VERSION "HNNBNNNYNNNNNNNNNNNNNNNNNNNNNNNNNNNNNNNNNN/4/%%%/4/'%**4NNN///"

NS_ :

BS_:

BU_: AWC BAP_Tester BMC_MLBevo BMS_MV BMS_NV DCDC_800V_PAG DCDC_HV DCDC_HV_02 DCDC_IHEV FCU_MLBevo_FCEV Gateway Gateway_PAG Ladegeraet_2 Ladegeraet_Konzern LE1 LE2 LE2_3_MLBevo_LB LE_MLBevo LE_MLBevo_LB Sub_Gateway TME

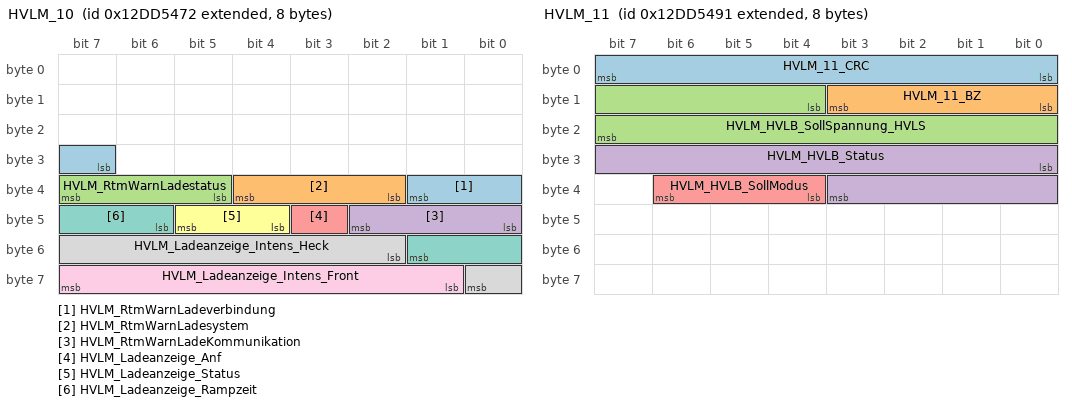
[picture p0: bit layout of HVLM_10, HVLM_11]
BO_ 2463978610 HVLM_10: 8 Ladegeraet_Konzern
 SG_ HVLM_RtmWarnLadeverbindung : 31|3@1+ (1,0) [0|7] ""  Gateway,Gateway_PAG,Sub_Gateway
 SG_ HVLM_RtmWarnLadesystem : 34|3@1+ (1,0) [0|7] ""  Gateway,Gateway_PAG,Sub_Gateway
 SG_ HVLM_RtmWarnLadestatus : 37|3@1+ (1,0) [0|7] ""  Gateway,Gateway_PAG,Sub_Gateway
 SG_ HVLM_RtmWarnLadeKommunikation : 40|3@1+ (1,0) [0|7] ""  Gateway,Gateway_PAG,Sub_Gateway
 SG_ HVLM_Ladeanzeige_Anf : 43|1@1+ (1,0) [0|1] ""  Gateway,Gateway_PAG,Sub_Gateway
 SG_ HVLM_Ladeanzeige_Status : 44|2@1+ (1,0) [0|3] ""  Gateway,Gateway_PAG,Sub_Gateway
 SG_ HVLM_Ladeanzeige_Rampzeit : 46|4@1+ (50,0) [0|750] "Unit_MilliSecon"  Gateway,Gateway_PAG,Sub_Gateway
 SG_ HVLM_Ladeanzeige_Intens_Heck : 50|7@1+ (1,0) [0|100] "Unit_PerCent"  Gateway,Gateway_PAG,Sub_Gateway
 SG_ HVLM_Ladeanzeige_Intens_Front : 57|7@1+ (1,0) [0|100] "Unit_PerCent"  Gateway,Gateway_PAG,Sub_Gateway

BO_ 2463978641 HVLM_11: 8 Ladegeraet_Konzern
 SG_ HVLM_11_CRC : 0|8@1+ (1,0) [0|255] ""  DCDC_HV_02
 SG_ HVLM_11_BZ : 8|4@1+ (1,0) [0|15] ""  DCDC_HV_02
 SG_ HVLM_HVLB_SollSpannung_HVLS : 12|12@1+ (0.25,0) [0|1023.25] "Unit_Volt"  DCDC_HV_02
 SG_ HVLM_HVLB_Status : 24|12@1+ (1,0) [0|4095] ""  DCDC_HV_02
 SG_ HVLM_HVLB_SollModus : 36|3@1+ (1,0) [0|7] ""  DCDC_HV_02

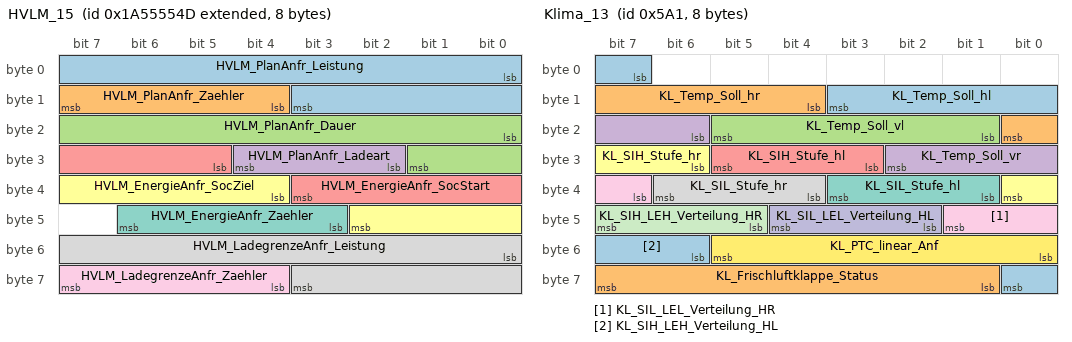
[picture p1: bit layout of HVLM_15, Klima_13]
BO_ 2589283661 HVLM_15: 8 Ladegeraet_Konzern
 SG_ HVLM_PlanAnfr_Leistung : 0|12@1+ (200,0) [0|818600] "Unit_Watt"  AWC,DCDC_HV_02,TME
 SG_ HVLM_PlanAnfr_Zaehler : 12|4@1+ (1,0) [0|13] "Unit_None"  AWC,DCDC_HV_02,TME
 SG_ HVLM_PlanAnfr_Dauer : 16|10@1+ (1,0) [0|1021] "Unit_Minut"  AWC,DCDC_HV_02,TME
 SG_ HVLM_PlanAnfr_Ladeart : 26|3@1+ (1,0) [0|7] ""  AWC,DCDC_HV_02,TME
 SG_ HVLM_EnergieAnfr_SocStart : 29|7@1+ (1,0) [0|100] "Unit_PerCent"  BMC_MLBevo
 SG_ HVLM_EnergieAnfr_SocZiel : 36|7@1+ (1,0) [0|100] "Unit_PerCent"  BMC_MLBevo
 SG_ HVLM_EnergieAnfr_Zaehler : 43|4@1+ (1,0) [0|13] "Unit_None"  BMC_MLBevo
 SG_ HVLM_LadegrenzeAnfr_Leistung : 48|12@1+ (200,0) [0|818600] "Unit_Watt"  BMC_MLBevo
 SG_ HVLM_LadegrenzeAnfr_Zaehler : 60|4@1+ (1,0) [0|13] "Unit_None"  BMC_MLBevo

BO_ 1857 ISO_DCDC_Req: 8 Gateway
 SG_ ISO_DCDC_Req_Data : 0|64@1+ (1,0) [0|1.84467440737096E+019] ""  DCDC_IHEV

BO_ 1963 ISO_DCDC_Resp: 8 DCDC_IHEV
 SG_ ISO_DCDC_Resp_Data : 0|64@1+ (1,0) [0|1.84467440737096E+019] ""  Gateway,Gateway_PAG

BO_ 1795 ISO_Funktionaler_Req_Abgas: 8 Gateway
 SG_ ISO_Funktionaler_Req_Abgas : 0|64@1+ (1,0) [0|1.84467440737096E+019] ""  AWC,BMC_MLBevo,BMS_MV,Ladegeraet_2,Ladegeraet_Konzern,TME

BO_ 1792 ISO_Funktionaler_Req_All: 8 Gateway
 SG_ ISO_ALL_01_Req_Data : 0|64@1+ (1,0) [0|1.84467440737096E+019] ""  AWC,BMC_MLBevo,BMS_MV,BMS_NV,DCDC_800V_PAG,DCDC_HV,DCDC_HV_02,DCDC_IHEV,FCU_MLBevo_FCEV,Ladegeraet_2,Ladegeraet_Konzern,Sub_Gateway,TME

BO_ 2015 ISO_Funktionaler_Req_OBD: 8 Gateway
 SG_ ISO_OBD_Funktionaler_Req_Data : 0|64@1+ (1,0) [0|1.84467440737096E+019] ""  AWC,BMC_MLBevo,BMS_MV,Ladegeraet_2,Ladegeraet_Konzern,TME

BO_ 1860 ISO_Ladegeraet_Req: 8 Gateway
 SG_ ISO_Ladegeraet_Req_Data : 0|64@1+ (1,0) [0|1.84467440737096E+019] ""  Ladegeraet_Konzern

BO_ 1966 ISO_Ladegeraet_Resp: 8 Ladegeraet_Konzern
 SG_ ISO_Ladegeraet_Resp_Data : 0|64@1+ (1,0) [0|1.84467440737096E+019] ""  Gateway,Gateway_PAG

BO_ 2021 ISO_OBD_04_Req: 8 Gateway
 SG_ ISO_OBD_04_Req_Data : 0|64@1+ (1,0) [0|1.84467440737096E+019] ""  BMC_MLBevo,BMS_MV

BO_ 2029 ISO_OBD_04_Resp: 8 BMC_MLBevo
 SG_ ISO_OBD_04_Resp_Data : 0|64@1+ (1,0) [0|1.84467440737096E+019] ""  Gateway,Gateway_PAG

BO_ 2023 ISO_OBD_06_Req: 8 Gateway
 SG_ ISO_OBD_06_Req_Data : 0|64@1+ (1,0) [0|1.84467440737096E+019] ""  TME

BO_ 2031 ISO_OBD_06_Resp: 8 TME
 SG_ ISO_OBD_06_Resp_Data : 0|64@1+ (1,0) [0|1.84467440737096E+019] ""  Gateway,Gateway_PAG

BO_ 2549350937 ISO_OBDC_RTM_Req: 8 Gateway
 SG_ ISO_OBDC_RTM_Req_Data : 0|64@1+ (1,0) [0|1.84467440737096E+019] ""  Sub_Gateway

BO_ 2549487874 ISO_OBDC_RTM_Resp: 8 Sub_Gateway
 SG_ ISO_OBDC_RTM_Resp_Data : 0|64@1+ (1,0) [0|1.84467440737096E+019] ""  Gateway,Gateway_PAG

BO_ 2549356802 ISO_RTM_OBDC_Req: 8 Sub_Gateway
 SG_ ISO_RTM_OBDC_Req_Data : 0|64@1+ (1,0) [0|1.84467440737096E+019] ""  Gateway,Gateway_PAG

BO_ 2549482009 ISO_RTM_OBDC_Resp: 8 Gateway
 SG_ ISO_RTM_OBDC_Resp_Data : 0|64@1+ (1,0) [0|1.84467440737096E+019] ""  Sub_Gateway

BO_ 1865 ISO_Sub_Gateway_Req: 8 Gateway
 SG_ ISO_Sub_Gateway_Req_Data : 0|64@1+ (1,0) [0|1.84467440737096E+019] ""  Sub_Gateway

BO_ 1971 ISO_Sub_Gateway_Resp: 8 Sub_Gateway
 SG_ ISO_Sub_Gateway_Resp_Data : 0|64@1+ (1,0) [0|1.84467440737096E+019] ""  Gateway,Gateway_PAG

BO_ 1858 ISO_TME_Req: 8 Gateway
 SG_ ISO_TME_Req_Data : 0|64@1+ (1,0) [0|1.84467440737096E+019] ""  TME

BO_ 1964 ISO_TME_Resp: 8 TME
 SG_ ISO_TME_Resp_Data : 0|64@1+ (1,0) [0|1.84467440737096E+019] ""  Gateway,Gateway_PAG

BO_ 2549874831 ISOx_AWC_Req: 8 Gateway
 SG_ ISO_AWC_Req_Data : 0|64@1+ (1,0) [0|1.84467440737096E+019] ""  AWC

BO_ 2550005903 ISOx_AWC_Resp: 8 AWC
 SG_ ISO_AWC_Resp_Data : 0|64@1+ (1,0) [0|1.84467440737096E+019] ""  Gateway,Gateway_PAG

BO_ 2549874862 ISOx_BattRegelung_Req: 8 Gateway
 SG_ ISO_BattRegelung_Req_Data : 0|64@1+ (1,0) [0|1.84467440737096E+019] ""  BMS_NV

BO_ 2550005934 ISOx_BattRegelung_Resp: 8 BMS_NV
 SG_ ISO_BattRegelung_Resp_Data : 0|64@1+ (1,0) [0|1.84467440737096E+019] ""  Gateway,Gateway_PAG

BO_ 2549874844 ISOx_BMS_48V_Req: 8 Gateway
 SG_ ISO_BMS_48V_Req_Data : 0|64@1+ (1,0) [0|1.84467440737096E+019] ""  BMS_MV

BO_ 2550005916 ISOx_BMS_48V_Resp: 8 BMS_MV
 SG_ ISO_BMS_48V_Resp_Data : 0|64@1+ (1,0) [0|1.84467440737096E+019] ""  Gateway,Gateway_PAG

BO_ 2549874887 ISOx_DCDC_HV_02_Req: 8 Gateway
 SG_ ISO_DCDC_HV_02_Req_Data : 0|64@1+ (1,0) [0|1.84467440737096E+019] "Unit_None"  DCDC_HV_02

BO_ 2550005959 ISOx_DCDC_HV_02_Resp: 8 DCDC_HV_02
 SG_ ISO_DCDC_HV_02_Resp_Data : 0|64@1+ (1,0) [0|1.84467440737096E+019] "Unit_None"  Gateway,Gateway_PAG

BO_ 2549874895 ISOx_DCDC_HV_03_Req: 8 Gateway
 SG_ ISOx_DCDC_HV_03_Req_Data : 0|64@1+ (1,0) [0|1.84467440737096E+019] ""  FCU_MLBevo_FCEV

BO_ 2550005967 ISOx_DCDC_HV_03_Resp: 8 FCU_MLBevo_FCEV
 SG_ ISOx_DCDC_HV_03_Resp_Data : 0|64@1+ (1,0) [0|1.84467440737096E+019] ""  Gateway

BO_ 2549874871 ISOx_DCDC_HV_Req: 8 Gateway
 SG_ ISO_DCDC_HV_Req_Data : 0|64@1+ (1,0) [0|1.84467440737096E+019] ""  DCDC_800V_PAG,DCDC_HV

BO_ 2550005943 ISOx_DCDC_HV_Resp: 8 DCDC_800V_PAG
 SG_ ISO_DCDC_HV_Resp_Data : 0|64@1+ (1,0) [0|1.84467440737096E+019] ""  Gateway,Gateway_PAG

BO_ 2549874869 ISOx_FCU_Req: 8 Gateway
 SG_ ISOx_FCU_Req_Data : 0|64@1+ (1,0) [0|1.84467440737096E+019] ""  FCU_MLBevo_FCEV

BO_ 2550005941 ISOx_FCU_Resp: 8 FCU_MLBevo_FCEV
 SG_ ISOx_FCU_Resp_Data : 0|64@1+ (1,0) [0|1.84467440737096E+019] ""  Gateway

BO_ 2549874811 ISOx_Hybrid_01_Req: 8 Gateway
 SG_ ISO_Hybrid_01_Req_Data : 0|64@1+ (1,0) [0|1.84467440737096E+019] ""  BMC_MLBevo

BO_ 2550005883 ISOx_Hybrid_01_Resp: 8 BMC_MLBevo
 SG_ ISO_Hybrid_01_Resp_Data : 0|64@1+ (1,0) [0|1.84467440737096E+019] ""  Gateway,Gateway_PAG

BO_ 2549874886 ISOx_Ladegeraet_2_Req: 8 Gateway
 SG_ ISO_Ladegeraet_2_Req_Data : 0|64@1+ (1,0) [0|1.84467440737096E+019] "Unit_None"  Ladegeraet_2

BO_ 2550005958 ISOx_Ladegeraet_2_Resp: 8 Ladegeraet_2
 SG_ ISO_Ladegeraet_2_Resp_Data : 0|64@1+ (1,0) [0|1.84467440737096E+019] "Unit_None"  Gateway,Gateway_PAG

BO_ 2549874868 ISOx_TelemetrieSG_Req: 8 Gateway
 SG_ ISOx_TelemetrieSG_Req_Data : 0|64@1+ (1,0) [0|1.84467440737096E+019] ""  Sub_Gateway

BO_ 2550005940 ISOx_TelemetrieSG_Resp: 8 Sub_Gateway
 SG_ ISOx_TelemetrieSG_Resp_Data : 0|64@1+ (1,0) [0|1.84467440737096E+019] ""  Gateway,Gateway_PAG

BO_ 497 Kessy_11: 8 Gateway
 SG_ KY_IDG_in_Reichweite : 12|1@1+ (1,0) [0|1] "" Vector__XXX
 SG_ KY_Auf_Taste : 13|1@1+ (1,0) [0|1] ""  FCU_MLBevo_FCEV,Ladegeraet_Konzern
 SG_ KY_HDF_Taste : 14|1@1+ (1,0) [0|1] "" Vector__XXX
 SG_ KY_Panik_Taste : 15|1@1+ (1,0) [0|1] "" Vector__XXX
 SG_ KY_Zu_Taste : 16|1@1+ (1,0) [0|1] ""  Ladegeraet_Konzern
 SG_ KY_FT_Entriegelung_Autorisiert : 17|1@1+ (1,0) [0|1] ""  FCU_MLBevo_FCEV
 SG_ KY_FT_Verriegelung_Autorisiert : 18|1@1+ (1,0) [0|1] "" Vector__XXX
 SG_ KY_BT_Entriegelung_Autorisiert : 19|1@1+ (1,0) [0|1] ""  FCU_MLBevo_FCEV
 SG_ KY_BT_Verriegelung_Autorisiert : 20|1@1+ (1,0) [0|1] "" Vector__XXX
 SG_ KY_HFS_Entriegelung_Autorisiert : 21|1@1+ (1,0) [0|1] ""  FCU_MLBevo_FCEV
 SG_ KY_HFS_Verriegelung_Autorisiert : 22|1@1+ (1,0) [0|1] "" Vector__XXX
 SG_ KY_HBFS_Entriegelung_Autorisiert : 23|1@1+ (1,0) [0|1] ""  FCU_MLBevo_FCEV
 SG_ KY_HBFS_Verriegelung_Autorisiert : 24|1@1+ (1,0) [0|1] "" Vector__XXX
 SG_ KY_Front_Entr_Autorisiert : 25|1@1+ (1,0) [0|1] "" Vector__XXX
 SG_ KY_Front_Verr_Autorisiert : 26|1@1+ (1,0) [0|1] "" Vector__XXX
 SG_ KY_HD_Entriegelung_Autorisiert : 27|1@1+ (1,0) [0|1] ""  FCU_MLBevo_FCEV
 SG_ KY_HD_Verriegelung_Autorisiert : 28|1@1+ (1,0) [0|1] "" Vector__XXX
 SG_ KY_Bereich : 29|3@1+ (1,0) [0|7] "" Vector__XXX
 SG_ KY_Position : 32|3@1+ (1,0) [0|7] "" Vector__XXX
 SG_ KY_ZV_Signatur : 35|11@1+ (1,0) [0|2047] "" Vector__XXX
 SG_ Schluesselnr_Personalisierung : 46|4@1+ (1,0) [0|15] "" Vector__XXX
 SG_ FFB_FDF_Taste : 50|1@1+ (1,0) [0|1] "" Vector__XXX
 SG_ FFB_Joker_Taste : 51|1@1+ (1,0) [0|1] "" Vector__XXX
 SG_ FFB_Park_Taste : 52|1@1+ (1,0) [0|1] "" Vector__XXX
 SG_ FFB_Remotestart_Taste : 53|1@1+ (1,0) [0|1] "" Vector__XXX
 SG_ FBS_Aktivierung_Pilot_Parken : 54|1@1+ (1,0) [0|1] "" Vector__XXX
 SG_ KY_Schluessel_im_Fzg : 55|1@1+ (1,0) [0|1] "" Vector__XXX
 SG_ KY_EasyClose_Abbruch : 56|1@1+ (1,0) [0|1] "" Vector__XXX
 SG_ KY_EasyClose_Status : 57|3@1+ (1,0) [0|7] "" Vector__XXX
 SG_ KY_HD_Auffahrt : 60|1@1+ (1,0) [0|1] "" Vector__XXX
 SG_ KY_HD_Zufahrt : 61|1@1+ (1,0) [0|1] "" Vector__XXX
 SG_ KY_LKL_1_Autorisierung : 62|1@1+ (1,0) [0|1] ""  Ladegeraet_Konzern
 SG_ KY_LKL_2_Autorisierung : 63|1@1+ (1,0) [0|1] ""  Ladegeraet_Konzern

BO_ 960 Klemmen_Status_01: 4 Gateway
 SG_ Klemmen_Status_01_CRC : 0|8@1+ (1,0) [0|255] ""  BMC_MLBevo,DCDC_HV_02,FCU_MLBevo_FCEV,Ladegeraet_2,Ladegeraet_Konzern
 SG_ Klemmen_Status_01_BZ : 8|4@1+ (1,0) [0|15] ""  BMC_MLBevo,DCDC_HV_02,FCU_MLBevo_FCEV,Ladegeraet_2,Ladegeraet_Konzern
 SG_ RSt_Fahrerhinweise : 12|4@1+ (1,0) [0|15] ""  FCU_MLBevo_FCEV
 SG_ ZAS_Kl_S : 16|1@1+ (1,0) [0|1] ""  FCU_MLBevo_FCEV,Ladegeraet_2,Ladegeraet_Konzern,TME
 SG_ ZAS_Kl_15 : 17|1@1+ (1,0) [0|1] ""  AWC,BMC_MLBevo,BMS_NV,DCDC_800V_PAG,DCDC_HV,DCDC_HV_02,DCDC_IHEV,FCU_MLBevo_FCEV,Ladegeraet_2,Ladegeraet_Konzern,Sub_Gateway,TME
 SG_ ZAS_Kl_X : 18|1@1+ (1,0) [0|1] ""  FCU_MLBevo_FCEV
 SG_ ZAS_Kl_50_Startanforderung : 19|1@1+ (1,0) [0|1] ""  AWC,BMC_MLBevo,FCU_MLBevo_FCEV,Ladegeraet_2,Ladegeraet_Konzern,TME
 SG_ BCM_Remotestart_Betrieb : 20|1@1+ (1,0) [0|1] ""  FCU_MLBevo_FCEV
 SG_ ZAS_Kl_Infotainment : 21|1@1+ (1,0) [0|1] ""  FCU_MLBevo_FCEV
 SG_ BCM_Remotestart_KL15_Anf : 22|1@1+ (1,0) [0|1] ""  FCU_MLBevo_FCEV
 SG_ BCM_Remotestart_MO_Start : 23|1@1+ (1,0) [0|1] ""  FCU_MLBevo_FCEV
 SG_ KST_Warn_P1_ZST_def : 24|1@1+ (1,0) [0|1] ""  FCU_MLBevo_FCEV
 SG_ KST_Warn_P2_ZST_def : 25|1@1+ (1,0) [0|1] ""  FCU_MLBevo_FCEV
 SG_ KST_Fahrerhinweis_1 : 26|1@1+ (1,0) [0|1] ""  FCU_MLBevo_FCEV
 SG_ KST_Fahrerhinweis_2 : 27|1@1+ (1,0) [0|1] ""  FCU_MLBevo_FCEV
 SG_ BCM_Ausparken_Betrieb : 28|1@1+ (1,0) [0|1] ""  FCU_MLBevo_FCEV
 SG_ KST_Fahrerhinweis_4 : 29|1@1+ (1,0) [0|1] ""  FCU_MLBevo_FCEV
 SG_ KST_Fahrerhinweis_5 : 30|1@1+ (1,0) [0|1] ""  FCU_MLBevo_FCEV
 SG_ KST_Fahrerhinweis_6 : 31|1@1+ (1,0) [0|1] ""  FCU_MLBevo_FCEV

BO_ 1646 Klima_03: 8 Gateway
 SG_ KL_STL_aktiv : 0|1@1+ (1,0) [0|1] "" Vector__XXX
 SG_ KL_STH_aktiv : 1|1@1+ (1,0) [0|1] "" Vector__XXX
 SG_ KL_Solarluefter_aktiv : 2|1@1+ (1,0) [0|1] "" Vector__XXX
 SG_ KL_Umluft_Taste : 3|1@1+ (1,0) [0|1] ""  TME
 SG_ KL_Geblaese_Fond_Status : 4|4@1+ (1,0) [0|15] ""  TME
 SG_ KL_STH_Ansteuerung : 8|2@1+ (1,0) [0|3] "" Vector__XXX
 SG_ KL_STH_Betriebsdauer : 10|6@1+ (1,0) [0|60] "Unit_Minut" Vector__XXX
 SG_ KL_Magnetventil : 16|1@1+ (1,0) [0|1] "" Vector__XXX
 SG_ KL_WaPu : 17|1@1+ (1,0) [0|1] "" Vector__XXX
 SG_ KL_Geblaese_Status : 18|4@1+ (1,0) [0|15] ""  TME
 SG_ KL_Restwaerme_aktiv : 22|1@1+ (1,0) [0|1] "" Vector__XXX
 SG_ KL_Kompressorkupplung : 23|1@1+ (1,0) [0|1] "" Vector__XXX
 SG_ KL_BCmE_Livetip_Freigabe : 24|1@1+ (1,0) [0|1] ""  TME
 SG_ KL_HYB_ASV_hinten_schliessen_Anf : 25|1@1+ (1,0) [0|1] ""  TME
 SG_ KL_HYB_ASV_vorne_schliessen_Anf : 26|1@1+ (1,0) [0|1] ""  TME
 SG_ KL_ErwVK_Zusatzrelais : 27|1@1+ (1,0) [0|1] "" Vector__XXX
 SG_ KL_Status_Beduftung : 28|1@1+ (1,0) [0|1] "" Vector__XXX
 SG_ KL_Status_Ionisator_Front : 29|1@1+ (1,0) [0|1] "" Vector__XXX
 SG_ KL_STH_Timer_Status : 30|1@1+ (1,0) [0|1] "" Vector__XXX
 SG_ KL_ErwVK_Anf : 31|1@1+ (1,0) [0|1] ""  TME
 SG_ KL_Innen_Temp : 32|8@1+ (0.5,-50) [-50|76] "Unit_DegreCelsi"  TME
 SG_ KL_I_Geblaese_Fond : 40|8@1+ (0.25,0) [0|63.5] "Unit_Amper" Vector__XXX
 SG_ KL_Anf_AussenspiegelHzg : 48|1@1+ (1,0) [0|1] "" Vector__XXX
 SG_ KL_Heizkreisventilstellung : 49|2@1+ (1,0) [0|3] "" Vector__XXX
 SG_ KL_FSH_Automatikbetrieb : 51|1@1+ (1,0) [0|1] "" Vector__XXX
 SG_ KL_SIH_LEH_Verteilung_VL : 52|3@1+ (1,0) [0|7] "" Vector__XXX
 SG_ KL_SIH_LEL_Verteilung_VL : 55|3@1+ (1,0) [0|7] "" Vector__XXX
 SG_ KL_SIH_LEH_Verteilung_VR : 58|3@1+ (1,0) [0|7] "" Vector__XXX
 SG_ KL_SIH_LEL_Verteilung_VR : 61|3@1+ (1,0) [0|7] "" Vector__XXX

BO_ 1649 Klima_06: 8 Gateway
 SG_ KL_ZZ_Minute : 0|6@1+ (1,0) [0|59] "Unit_Minut"  TME
 SG_ KL_ZZ_Status_Timer : 6|2@1+ (1,0) [0|3] ""  TME
 SG_ KL_ZZ_Monat : 8|4@1+ (1,0) [1|12] "Unit_Month"  TME
 SG_ KL_ZZ_Stunde : 16|5@1+ (1,0) [0|23] "Unit_Hours"  TME
 SG_ KL_ZZ_Betriebsmodus : 21|3@1+ (1,0) [0|7] ""  TME
 SG_ KL_ZZ_Tag : 24|5@1+ (1,0) [1|31] "Unit_Day"  TME
 SG_ KL_Betriebsmodus_FH : 29|3@1+ (1,0) [0|7] "" Vector__XXX
 SG_ KL_Stopp_Wiederstart_Anz_01 : 32|1@1+ (1,0) [0|1] "" Vector__XXX
 SG_ KL_Stopp_Wiederstart_Anz_02 : 33|1@1+ (1,0) [0|1] "" Vector__XXX
 SG_ KL_Stopp_Wiederstart_Anz_03 : 34|1@1+ (1,0) [0|1] "" Vector__XXX
 SG_ KL_Stopp_Wiederstart_Anz_04 : 35|1@1+ (1,0) [0|1] "" Vector__XXX
 SG_ KL_Stopp_Wiederstart_Anz_05 : 36|1@1+ (1,0) [0|1] "" Vector__XXX
 SG_ KL_Stopp_Wiederstart_Anz_06 : 37|1@1+ (1,0) [0|1] "" Vector__XXX
 SG_ KL_Stopp_Wiederstart_Anz_07 : 38|1@1+ (1,0) [0|1] "" Vector__XXX
 SG_ KL_Stopp_Wiederstart_Anz_08 : 39|1@1+ (1,0) [0|1] "" Vector__XXX
 SG_ KL_Stopp_Wiederstart_Anz_09 : 40|1@1+ (1,0) [0|1] "" Vector__XXX
 SG_ KL_Stopp_Wiederstart_Anz_Std1 : 41|1@1+ (1,0) [0|1] "" Vector__XXX
 SG_ KL_Stopp_Wiederstart_Anz_Std2 : 42|1@1+ (1,0) [0|1] "" Vector__XXX

BO_ 949 Klima_11: 8 Gateway
 SG_ KL_Drehz_Anh : 0|1@1+ (1,0) [0|1] ""  TME
 SG_ KL_Vorwarn_Komp_ein : 1|1@1+ (1,0) [0|1] ""  TME
 SG_ KL_AC_Schalter : 2|1@1+ (1,0) [0|1] ""  TME
 SG_ KL_Komp_Moment_alt : 3|1@1+ (1,0) [0|1] ""  TME
 SG_ KL_Vorwarn_Zuheizer_ein : 6|1@1+ (1,0) [0|1] "" Vector__XXX
 SG_ KL_Zustand : 7|1@1+ (1,0) [0|1] ""  TME
 SG_ KL_Kompressorkupplung_linear : 8|8@1+ (20,0) [0|4000] "Unit_MilliAmper" Vector__XXX
 SG_ KL_Charisma_FahrPr : 16|4@1+ (1,0) [0|15] ""  TME
 SG_ KL_Charisma_Status : 20|2@1+ (1,0) [0|3] ""  TME
 SG_ KL_nachtr_Stopp_Anf : 22|1@1+ (1,0) [0|1] "" Vector__XXX
 SG_ KL_T_Charge : 23|1@1+ (1,0) [0|1] "" Vector__XXX
 SG_ KL_Last_Kompr : 24|8@1+ (0.25,0) [0|63.5] "Unit_NewtoMeter"  TME
 SG_ KL_Spannungs_Anf : 32|2@1+ (1,0) [0|3] "" Vector__XXX
 SG_ KL_Thermomanagement : 34|2@1+ (1,0) [0|3] ""  TME
 SG_ KL_StartStopp_Info : 36|2@1+ (1,0) [0|3] ""  TME
 SG_ KL_Freilauf_Info : 38|2@1+ (1,0) [0|3] "" Vector__XXX
 SG_ KL_Anf_KL : 40|8@1+ (0.4,0) [0|101.6] "Unit_PerCent"  TME
 SG_ KL_el_Zuheizer_Stufe : 48|3@1+ (1,0) [0|7] ""  TME
 SG_ KL_Ausstattung_Klima : 51|3@1+ (1,0) [0|7] "" Vector__XXX
 SG_ KL_Variante_Standheizung : 54|2@1+ (1,0) [0|3] "" Vector__XXX

BO_ 1640 Klima_12: 8 Gateway
 SG_ KL_LRH_Taster : 0|1@1+ (1,0) [0|1] "" Vector__XXX
 SG_ KL_LRH_Stufe : 1|2@1+ (1,0) [0|3] "" Vector__XXX
 SG_ HSH_Taster : 3|2@1+ (1,0) [0|3] "" Vector__XXX
 SG_ FSH_Taster : 5|1@1+ (1,0) [0|1] "" Vector__XXX
 SG_ KL_Zuheizer_Freigabe : 6|1@1+ (1,0) [0|1] ""  TME
 SG_ KL_Beschlagsgefahr : 7|1@1+ (1,0) [0|1] ""  TME
 SG_ KL_SIH_Soll_li : 8|3@1+ (1,0) [0|7] ""  TME
 SG_ KL_SIH_Soll_re : 11|3@1+ (1,0) [0|7] ""  TME
 SG_ KRH_Soll_li : 14|2@1+ (1,0) [0|3] "" Vector__XXX
 SG_ KL_SIL_Soll_li : 16|3@1+ (1,0) [0|7] ""  TME
 SG_ KL_SIL_Soll_re : 19|3@1+ (1,0) [0|7] ""  TME
 SG_ KRH_Soll_re : 22|2@1+ (1,0) [0|3] "" Vector__XXX
 SG_ KL_Geblspng_Soll : 24|8@1+ (0.05,1.45) [1.5|14] "Unit_Volt" Vector__XXX
 SG_ KL_Geblspng_Fond_Soll : 32|8@1+ (0.05,1.45) [1.5|14] "Unit_Volt" Vector__XXX
 SG_ KL_I_Geblaese : 40|8@1+ (0.25,0) [0|63.5] "Unit_Amper" Vector__XXX
 SG_ KL_Kompressorstrom_soll : 48|10@1+ (1,0) [0|1021] ""  TME
 SG_ KL_Umluftklappe_Status : 58|4@1+ (1,0) [0|15] ""  TME
 SG_ KL_PTC_Verbauinfo : 62|2@1+ (1,0) [0|3] "" Vector__XXX

BO_ 1441 Klima_13: 8 Gateway
 SG_ KL_Temp_Soll_hl : 7|5@1+ (0.5,15.5) [15.5|30] "Unit_DegreCelsi"  TME
 SG_ KL_Temp_Soll_hr : 12|5@1+ (0.5,15.5) [15.5|30] "Unit_DegreCelsi"  TME
 SG_ KL_Temp_Soll_vl : 17|5@1+ (0.5,15.5) [15.5|30] "Unit_DegreCelsi"  TME
 SG_ KL_Temp_Soll_vr : 22|5@1+ (0.5,15.5) [15.5|30] "Unit_DegreCelsi"  TME
 SG_ KL_SIH_Stufe_hl : 27|3@1+ (1,0) [0|6] "" Vector__XXX
 SG_ KL_SIH_Stufe_hr : 30|3@1+ (1,0) [0|6] "" Vector__XXX
 SG_ KL_SIL_Stufe_hl : 33|3@1+ (1,0) [0|6] "" Vector__XXX
 SG_ KL_SIL_Stufe_hr : 36|3@1+ (1,0) [0|6] "" Vector__XXX
 SG_ KL_SIL_LEL_Verteilung_HR : 39|3@1+ (1,0) [0|7] "" Vector__XXX
 SG_ KL_SIL_LEL_Verteilung_HL : 42|3@1+ (1,0) [0|7] "" Vector__XXX
 SG_ KL_SIH_LEH_Verteilung_HR : 45|3@1+ (1,0) [0|7] "" Vector__XXX
 SG_ KL_PTC_linear_Anf : 48|6@1+ (50,0) [0|3100] "Unit_Watt" Vector__XXX
 SG_ KL_SIH_LEH_Verteilung_HL : 54|3@1+ (1,0) [0|7] "" Vector__XXX
 SG_ KL_Frischluftklappe_Status : 57|7@1+ (1,0) [0|100] "Unit_PerCent"  TME

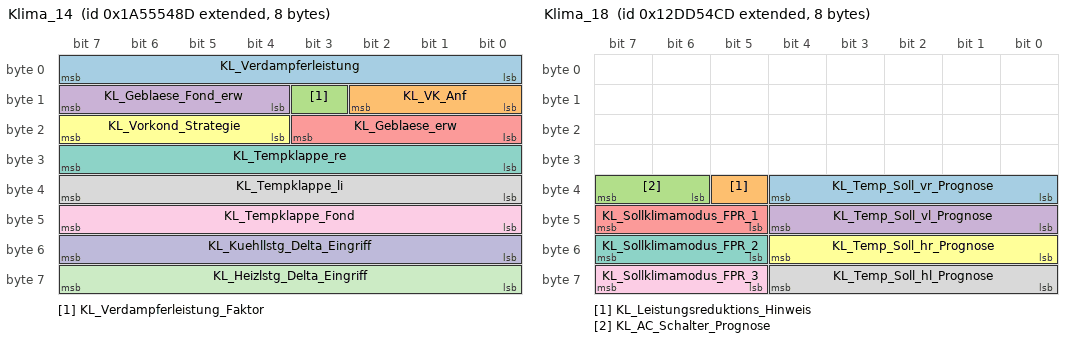
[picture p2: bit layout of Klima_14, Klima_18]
BO_ 2589283469 Klima_14: 8 Gateway
 SG_ KL_Verdampferleistung : 0|8@1+ (25,0) [0|6325] "Unit_Watt"  TME
 SG_ KL_VK_Anf : 8|3@1+ (1,0) [0|7] ""  Ladegeraet_Konzern,TME
 SG_ KL_Verdampferleistung_Faktor : 11|1@1+ (1,0) [0|1] ""  TME
 SG_ KL_Geblaese_Fond_erw : 12|4@1+ (1,0) [0|15] "" Vector__XXX
 SG_ KL_Geblaese_erw : 16|4@1+ (1,0) [0|15] "" Vector__XXX
 SG_ KL_Vorkond_Strategie : 20|4@1+ (1,0) [0|15] ""  TME
 SG_ KL_Tempklappe_re : 24|8@1+ (0.5,0) [0|100] "Unit_PerCent"  TME
 SG_ KL_Tempklappe_li : 32|8@1+ (0.5,0) [0|100] "Unit_PerCent"  TME
 SG_ KL_Tempklappe_Fond : 40|8@1+ (0.5,0) [0|100] "Unit_PerCent"  TME
 SG_ KL_Kuehllstg_Delta_Eingriff : 48|8@1+ (50,-6300) [-6300|6350] "Unit_Watt"  TME
 SG_ KL_Heizlstg_Delta_Eingriff : 56|8@1+ (50,-6300) [-6300|6350] "Unit_Watt"  TME

BO_ 2589283621 Klima_17: 8 Gateway
 SG_ KL_NV_Energie_Anf : 12|8@1+ (10,0) [0|2530] "Unit_WattHour"  Ladegeraet_Konzern,TME
 SG_ KL_FlHz_Soll_VL : 20|3@1+ (1,0) [0|6] "Unit_None" Vector__XXX
 SG_ KL_FlHz_Soll_HL : 23|3@1+ (1,0) [0|6] "Unit_None" Vector__XXX
 SG_ KL_FlHz_Soll_VR : 26|3@1+ (1,0) [0|6] "Unit_None" Vector__XXX
 SG_ KL_FlHz_Soll_HR : 29|3@1+ (1,0) [0|6] "Unit_None" Vector__XXX
 SG_ KL_Umluft_Connect_status : 32|3@1+ (1,0) [0|7] "" Vector__XXX
 SG_ KL_ECO_PRO_Aktiv : 35|1@1+ (1,0) [0|1] ""  TME
 SG_ KL_QBit_Sonnenintensitaet : 36|1@1+ (1,0) [0|1] ""  TME
 SG_ KL_ZR_Anforderung : 37|2@1+ (1,0) [0|3] "" Vector__XXX
 SG_ KL_ACmax_Aktiv : 39|1@1+ (1,0) [0|1] ""  TME
 SG_ KL_Defrost_Aktiv : 40|1@1+ (1,0) [0|1] ""  TME
 SG_ KL_ECO_Aktiv : 41|1@1+ (1,0) [0|1] ""  TME
 SG_ KL_Status_Klimastil : 42|2@1+ (1,0) [0|3] ""  TME
 SG_ KL_Kundeneingriff_Geblaese : 44|1@1+ (1,0) [0|1] ""  TME
 SG_ KL_Thermischer_Bedarf : 45|3@1+ (1,0) [0|7] ""  TME
 SG_ KL_Eps_Innen : 48|8@1+ (0.5,-50) [-50|50] "Unit_DegreCelsi"  TME
 SG_ KL_Sonnenintensitaet : 56|8@1+ (10,0) [0|1000] "Unit_WattPerMeterSquar"  TME

BO_ 2463978701 Klima_18: 8 Gateway
 SG_ KL_Temp_Soll_vr_Prognose : 32|5@1+ (0.5,15.5) [15.5|30] "Unit_DegreCelsi"  TME
 SG_ KL_Leistungsreduktions_Hinweis : 37|1@1+ (1,0) [0|1] "" Vector__XXX
 SG_ KL_AC_Schalter_Prognose : 38|2@1+ (1,0) [0|3] ""  TME
 SG_ KL_Temp_Soll_vl_Prognose : 40|5@1+ (0.5,15.5) [15.5|30] "Unit_DegreCelsi"  TME
 SG_ KL_Sollklimamodus_FPR_1 : 45|3@1+ (1,0) [0|7] ""  TME
 SG_ KL_Temp_Soll_hr_Prognose : 48|5@1+ (0.5,15.5) [15.5|30] "Unit_DegreCelsi"  TME
 SG_ KL_Sollklimamodus_FPR_2 : 53|3@1+ (1,0) [0|7] ""  TME
 SG_ KL_Temp_Soll_hl_Prognose : 56|5@1+ (0.5,15.5) [15.5|30] "Unit_DegreCelsi"  TME
 SG_ KL_Sollklimamodus_FPR_3 : 61|3@1+ (1,0) [0|7] ""  TME

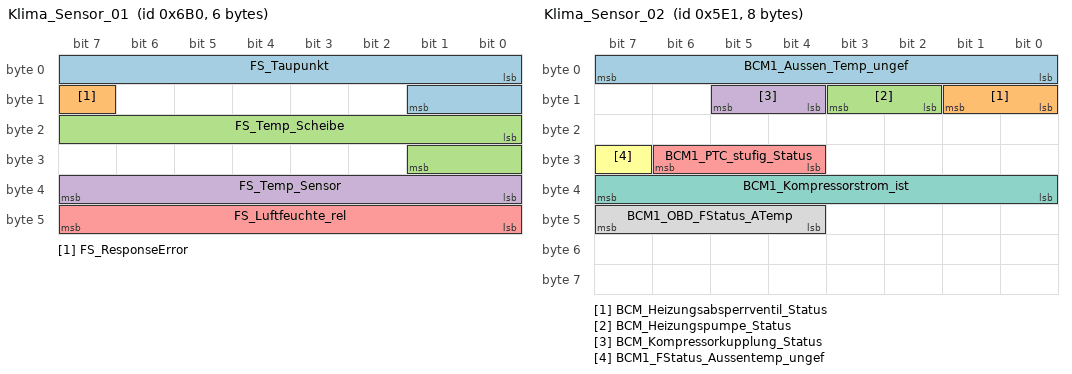
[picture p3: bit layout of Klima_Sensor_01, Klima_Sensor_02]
BO_ 1712 Klima_Sensor_01: 6 Gateway
 SG_ FS_Taupunkt : 0|10@1+ (0.1,-39.6) [-39.5|60.4] "Unit_DegreCelsi"  TME
 SG_ FS_ResponseError : 15|1@1+ (1,0) [0|1] "" Vector__XXX
 SG_ FS_Temp_Scheibe : 16|10@1+ (0.1,-39.6) [-39.5|60.4] "Unit_DegreCelsi"  TME
 SG_ FS_Temp_Sensor : 32|8@1+ (0.5,-40) [-39.5|87] "Unit_DegreCelsi"  TME
 SG_ FS_Luftfeuchte_rel : 40|8@1+ (0.5,-0.5) [0|100] "Unit_PerCent"  TME

BO_ 1505 Klima_Sensor_02: 8 Gateway
 SG_ BCM1_Aussen_Temp_ungef : 0|8@1+ (0.5,-50) [-50|76] "Unit_DegreCelsi"  BMC_MLBevo,BMS_NV,FCU_MLBevo_FCEV,Ladegeraet_Konzern,TME
 SG_ BCM_Heizungsabsperrventil_Status : 8|2@1+ (1,0) [0|3] "" Vector__XXX
 SG_ BCM_Heizungspumpe_Status : 10|2@1+ (1,0) [0|3] "" Vector__XXX
 SG_ BCM_Kompressorkupplung_Status : 12|2@1+ (1,0) [0|3] "" Vector__XXX
 SG_ BCM1_PTC_stufig_Status : 28|3@1+ (1,0) [0|7] "" Vector__XXX
 SG_ BCM1_FStatus_Aussentemp_ungef : 31|1@1+ (1,0) [0|1] ""  TME
 SG_ BCM1_Kompressorstrom_ist : 32|8@1+ (4,0) [0|1000] "Unit_MilliAmper" Vector__XXX
 SG_ BCM1_OBD_FStatus_ATemp : 44|4@1+ (1,0) [0|15] ""  BMC_MLBevo,Ladegeraet_Konzern,TME

BO_ 1717 Klima_Sensor_03: 8 Gateway
 SG_ FSA_Taupunkt : 0|10@1+ (0.1,-40) [-40|60] "Unit_DegreCelsi"  TME
 SG_ FSA_Err_Defekt_Tsens_TF : 10|1@1+ (1,0) [0|1] "" Vector__XXX
 SG_ FSA_Luftfeuchte_TNCTOC : 11|1@1+ (1,0) [0|1] "" Vector__XXX
 SG_ FSA_Luftfeuchte_TF : 12|1@1+ (1,0) [0|1] "" Vector__XXX
 SG_ FSA_Err_Unterspannung_TF : 13|1@1+ (1,0) [0|1] "" Vector__XXX
 SG_ FSA_Err_RAMROM_Check_TF : 14|1@1+ (1,0) [0|1] "" Vector__XXX
 SG_ FSA_ResponseError : 15|1@1+ (1,0) [0|1] "" Vector__XXX
 SG_ FSA_Temp_Luft : 16|10@1+ (0.1,-40) [-40|61] "Unit_DegreCelsi"  TME
 SG_ FSA_Err_RAMROM_Check_TNCTOC : 26|1@1+ (1,0) [0|1] "" Vector__XXX
 SG_ FSA_Lokal_Bus_elektr_Fehler : 27|1@1+ (1,0) [0|1] "" Vector__XXX
 SG_ FSA_Timeout : 28|1@1+ (1,0) [0|1] "" Vector__XXX
 SG_ FSA_Lokal_Bus_Unterbrechung : 29|1@1+ (1,0) [0|1] "" Vector__XXX
 SG_ FSA_Err_Ueberspannung_TF : 30|1@1+ (1,0) [0|1] "" Vector__XXX
 SG_ FSA_Luftfeuchte_rel : 32|8@1+ (0.5,0) [0|126] "Unit_PerCent"  TME
 SG_ FSA_HW : 40|4@1+ (1,0) [0|15] "" Vector__XXX
 SG_ FSA_SW : 44|4@1+ (1,0) [0|15] "" Vector__XXX
 SG_ FSA_Temp_Sensor : 48|11@1+ (0.1,-40) [-40|90] "Unit_DegreCelsi"  TME
 SG_ FSA_Sensorheizung_Status : 59|1@1+ (1,0) [0|1] ""  TME
 SG_ FSA_Err_Defekt_HumSense_TF : 60|1@1+ (1,0) [0|1] "" Vector__XXX
 SG_ FSA_Err_Defekt_HumSens_TNCTOC : 61|1@1+ (1,0) [0|1] "" Vector__XXX
 SG_ FSA_ErrMemState : 62|2@1+ (1,0) [0|3] "" Vector__XXX

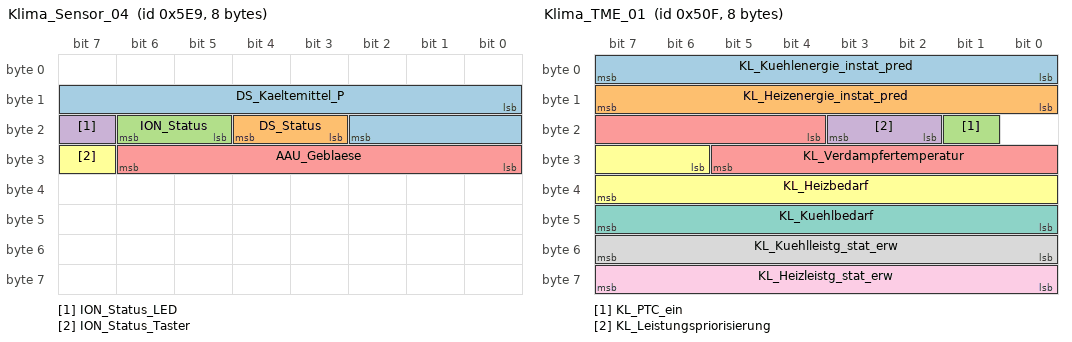
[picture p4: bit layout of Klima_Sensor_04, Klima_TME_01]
BO_ 1513 Klima_Sensor_04: 8 Gateway
 SG_ DS_Kaeltemittel_P : 8|11@1+ (0.0161,0) [0|32.9245] "Unit_Bar"  TME
 SG_ DS_Status : 19|2@1+ (1,0) [0|3] ""  TME
 SG_ ION_Status : 21|2@1+ (1,0) [0|3] "" Vector__XXX
 SG_ ION_Status_LED : 23|1@1+ (1,0) [0|1] "" Vector__XXX
 SG_ AAU_Geblaese : 24|7@1+ (1,0) [0|100] "Unit_PerCent" Vector__XXX
 SG_ ION_Status_Taster : 31|1@1+ (1,0) [0|1] "" Vector__XXX

BO_ 1295 Klima_TME_01: 8 Gateway
 SG_ KL_Kuehlenergie_instat_pred : 0|8@1+ (25,0) [0|6325] "Unit_WattHour"  TME
 SG_ KL_Heizenergie_instat_pred : 8|8@1+ (25,0) [0|6325] "Unit_WattHour"  TME
 SG_ KL_PTC_ein : 17|1@1+ (1,0) [0|1] "" Vector__XXX
 SG_ KL_Leistungspriorisierung : 18|2@1+ (1,0) [0|3] ""  TME
 SG_ KL_Verdampfertemperatur : 20|10@1+ (0.1,-20) [-20|70] "Unit_DegreCelsi"  TME
 SG_ KL_Heizbedarf : 30|10@1+ (0.1,0) [0.1|90] "Unit_DegreCelsi"  TME
 SG_ KL_Kuehlbedarf : 40|8@1+ (0.1,0) [0|25] "Unit_DegreCelsi"  TME
 SG_ KL_Kuehlleistg_stat_erw : 48|8@1+ (50,0) [0|12650] "Unit_Watt"  TME
 SG_ KL_Heizleistg_stat_erw : 56|8@1+ (50,0) [0|12650] "Unit_Watt"  TME

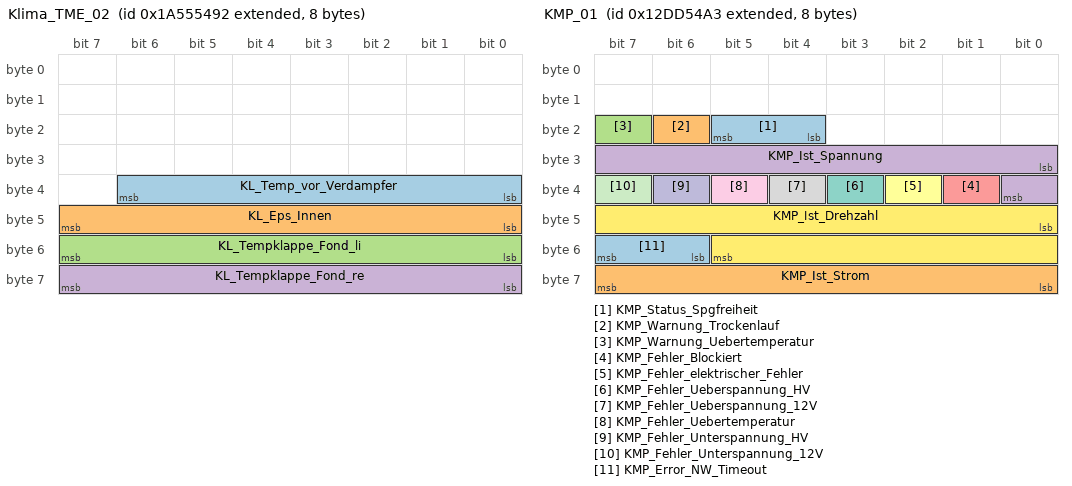
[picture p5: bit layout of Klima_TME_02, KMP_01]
BO_ 2589283474 Klima_TME_02: 8 Gateway
 SG_ KL_Temp_vor_Verdampfer : 32|7@1+ (1,-20) [-20|70] "Unit_DegreCelsi"  TME
 SG_ KL_Eps_Innen : 40|8@1+ (0.5,-50) [-50|50] "Unit_DegreCelsi" Vector__XXX
 SG_ KL_Tempklappe_Fond_li : 48|8@1+ (0.5,0) [0|100] "Unit_PerCent" Vector__XXX
 SG_ KL_Tempklappe_Fond_re : 56|8@1+ (0.5,0) [0|100] "Unit_PerCent" Vector__XXX

BO_ 2463978659 KMP_01: 8 FCU_MLBevo_FCEV
 SG_ KMP_Status_Spgfreiheit : 20|2@1+ (1,0) [0|3] ""  Gateway
 SG_ KMP_Warnung_Trockenlauf : 22|1@1+ (1,0) [0|1] "" Vector__XXX
 SG_ KMP_Warnung_Uebertemperatur : 23|1@1+ (1,0) [0|1] "" Vector__XXX
 SG_ KMP_Ist_Spannung : 24|9@1+ (2,0) [0|1022] "Unit_Volt"  Gateway
 SG_ KMP_Fehler_Blockiert : 33|1@1+ (1,0) [0|1] "" Vector__XXX
 SG_ KMP_Fehler_elektrischer_Fehler : 34|1@1+ (1,0) [0|1] "" Vector__XXX
 SG_ KMP_Fehler_Ueberspannung_HV : 35|1@1+ (1,0) [0|1] "" Vector__XXX
 SG_ KMP_Fehler_Ueberspannung_12V : 36|1@1+ (1,0) [0|1] "" Vector__XXX
 SG_ KMP_Fehler_Uebertemperatur : 37|1@1+ (1,0) [0|1] "" Vector__XXX
 SG_ KMP_Fehler_Unterspannung_HV : 38|1@1+ (1,0) [0|1] "" Vector__XXX
 SG_ KMP_Fehler_Unterspannung_12V : 39|1@1+ (1,0) [0|1] "" Vector__XXX
 SG_ KMP_Ist_Drehzahl : 40|14@1+ (1,0) [0|16383] "Unit_RevPerMinute"  TME
 SG_ KMP_Error_NW_Timeout : 54|2@1+ (1,0) [0|3] "" Vector__XXX
 SG_ KMP_Ist_Strom : 56|8@1+ (0.1,0) [0|25.5] "Unit_Amper" Vector__XXX

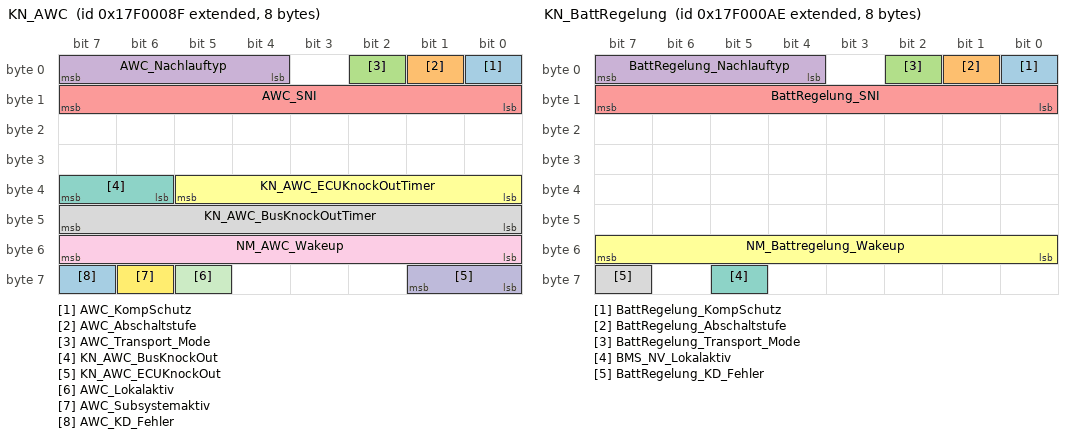
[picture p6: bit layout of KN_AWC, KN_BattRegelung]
BO_ 2549088399 KN_AWC: 8 AWC
 SG_ AWC_KompSchutz : 0|1@1+ (1,0) [0|1] "" Vector__XXX
 SG_ AWC_Abschaltstufe : 1|1@1+ (1,0) [0|1] "" Vector__XXX
 SG_ AWC_Transport_Mode : 2|1@1+ (1,0) [0|1] "" Vector__XXX
 SG_ AWC_Nachlauftyp : 4|4@1+ (1,0) [0|15] ""  Gateway,Gateway_PAG
 SG_ AWC_SNI : 8|8@1+ (1,0) [0|255] ""  Gateway,Gateway_PAG
 SG_ KN_AWC_ECUKnockOutTimer : 32|6@1+ (1,0) [0|62] "Unit_Minut"  Gateway,Gateway_PAG
 SG_ KN_AWC_BusKnockOut : 38|2@1+ (1,0) [0|3] ""  Gateway,Gateway_PAG
 SG_ KN_AWC_BusKnockOutTimer : 40|8@1+ (1,0) [0|254] ""  Gateway,Gateway_PAG
 SG_ NM_AWC_Wakeup : 48|8@1+ (1,0) [0|255] "" Vector__XXX
 SG_ KN_AWC_ECUKnockOut : 56|2@1+ (1,0) [0|3] ""  Gateway,Gateway_PAG
 SG_ AWC_Lokalaktiv : 61|1@1+ (1,0) [0|1] ""  Gateway,Gateway_PAG
 SG_ AWC_Subsystemaktiv : 62|1@1+ (1,0) [0|1] "" Vector__XXX
 SG_ AWC_KD_Fehler : 63|1@1+ (1,0) [0|1] ""  Gateway,Gateway_PAG

BO_ 2549088430 KN_BattRegelung: 8 BMS_NV
 SG_ BattRegelung_KompSchutz : 0|1@1+ (1,0) [0|1] "" Vector__XXX
 SG_ BattRegelung_Abschaltstufe : 1|1@1+ (1,0) [0|1] "" Vector__XXX
 SG_ BattRegelung_Transport_Mode : 2|1@1+ (1,0) [0|1] "" Vector__XXX
 SG_ BattRegelung_Nachlauftyp : 4|4@1+ (1,0) [0|15] ""  Gateway,Gateway_PAG
 SG_ BattRegelung_SNI : 8|8@1+ (1,0) [0|255] ""  Gateway,Gateway_PAG
 SG_ NM_Battregelung_Wakeup : 48|8@1+ (1,0) [0|255] "" Vector__XXX
 SG_ BMS_NV_Lokalaktiv : 61|1@1+ (1,0) [0|1] ""  Gateway,Gateway_PAG
 SG_ BattRegelung_KD_Fehler : 63|1@1+ (1,0) [0|1] ""  Gateway,Gateway_PAG

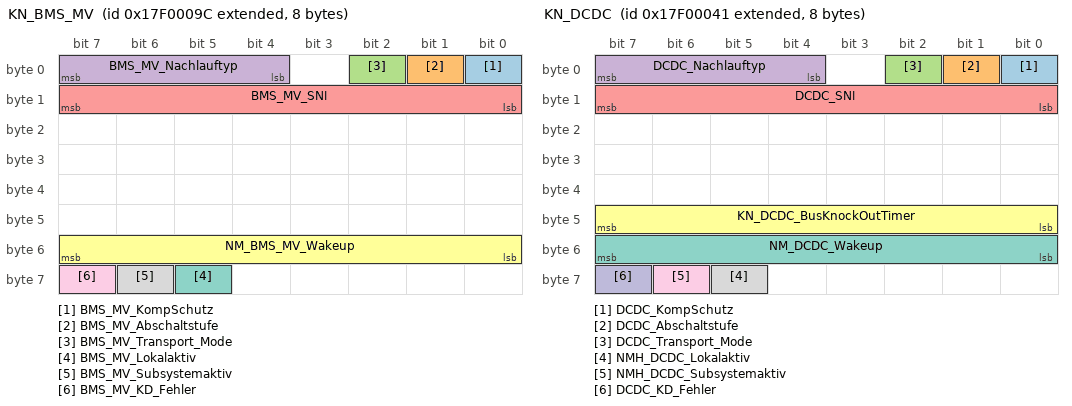
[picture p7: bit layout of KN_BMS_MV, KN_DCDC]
BO_ 2549088412 KN_BMS_MV: 8 Vector__XXX
 SG_ BMS_MV_KompSchutz : 0|1@1+ (1,0) [0|1] "" Vector__XXX
 SG_ BMS_MV_Abschaltstufe : 1|1@1+ (1,0) [0|1] "" Vector__XXX
 SG_ BMS_MV_Transport_Mode : 2|1@1+ (1,0) [0|1] "" Vector__XXX
 SG_ BMS_MV_Nachlauftyp : 4|4@1+ (1,0) [0|15] ""  Gateway,Gateway_PAG
 SG_ BMS_MV_SNI : 8|8@1+ (1,0) [0|255] ""  Gateway,Gateway_PAG
 SG_ NM_BMS_MV_Wakeup : 48|8@1+ (1,0) [0|255] "" Vector__XXX
 SG_ BMS_MV_Lokalaktiv : 61|1@1+ (1,0) [0|1] ""  Gateway,Gateway_PAG
 SG_ BMS_MV_Subsystemaktiv : 62|1@1+ (1,0) [0|1] ""  Gateway,Gateway_PAG
 SG_ BMS_MV_KD_Fehler : 63|1@1+ (1,0) [0|1] ""  Gateway,Gateway_PAG

BO_ 2549088321 KN_DCDC: 8 DCDC_IHEV
 SG_ DCDC_KompSchutz : 0|1@1+ (1,0) [0|1] "" Vector__XXX
 SG_ DCDC_Abschaltstufe : 1|1@1+ (1,0) [0|1] "" Vector__XXX
 SG_ DCDC_Transport_Mode : 2|1@1+ (1,0) [0|1] "" Vector__XXX
 SG_ DCDC_Nachlauftyp : 4|4@1+ (1,0) [0|15] ""  Gateway,Gateway_PAG
 SG_ DCDC_SNI : 8|8@1+ (1,0) [0|255] ""  Gateway,Gateway_PAG
 SG_ KN_DCDC_BusKnockOutTimer : 40|8@1+ (1,0) [0|254] ""  Gateway,Gateway_PAG
 SG_ NM_DCDC_Wakeup : 48|8@1+ (1,0) [0|255] "" Vector__XXX
 SG_ NMH_DCDC_Lokalaktiv : 61|1@1+ (1,0) [0|1] ""  Gateway,Gateway_PAG
 SG_ NMH_DCDC_Subsystemaktiv : 62|1@1+ (1,0) [0|1] "" Vector__XXX
 SG_ DCDC_KD_Fehler : 63|1@1+ (1,0) [0|1] ""  Gateway,Gateway_PAG

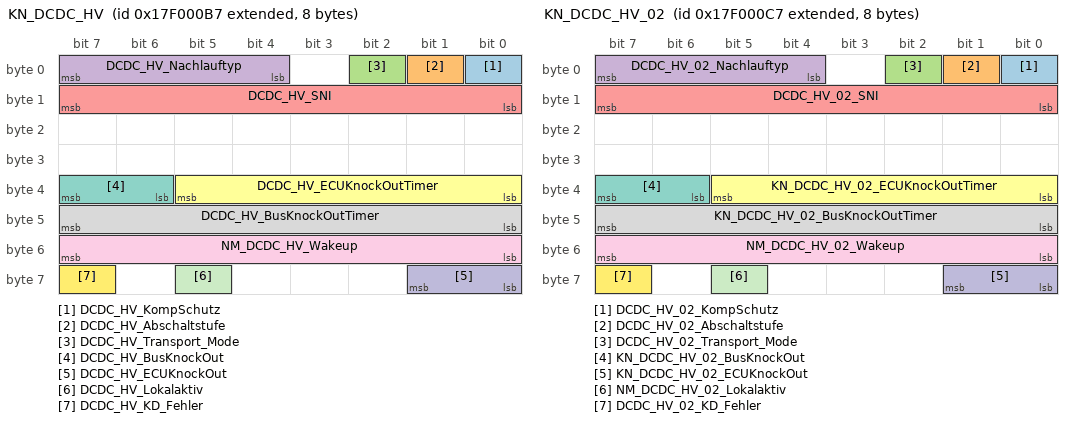
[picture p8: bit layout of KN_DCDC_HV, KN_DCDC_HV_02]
BO_ 2549088439 KN_DCDC_HV: 8 DCDC_800V_PAG
 SG_ DCDC_HV_KompSchutz : 0|1@1+ (1,0) [0|1] "" Vector__XXX
 SG_ DCDC_HV_Abschaltstufe : 1|1@1+ (1,0) [0|1] "" Vector__XXX
 SG_ DCDC_HV_Transport_Mode : 2|1@1+ (1,0) [0|1] "" Vector__XXX
 SG_ DCDC_HV_Nachlauftyp : 4|4@1+ (1,0) [0|15] ""  Gateway,Gateway_PAG
 SG_ DCDC_HV_SNI : 8|8@1+ (1,0) [0|255] ""  Gateway,Gateway_PAG
 SG_ DCDC_HV_ECUKnockOutTimer : 32|6@1+ (1,0) [0|62] "Unit_Minut"  Gateway,Gateway_PAG
 SG_ DCDC_HV_BusKnockOut : 38|2@1+ (1,0) [0|3] ""  Gateway,Gateway_PAG
 SG_ DCDC_HV_BusKnockOutTimer : 40|8@1+ (1,0) [0|254] ""  Gateway,Gateway_PAG
 SG_ NM_DCDC_HV_Wakeup : 48|8@1+ (1,0) [0|255] "" Vector__XXX
 SG_ DCDC_HV_ECUKnockOut : 56|2@1+ (1,0) [0|3] ""  Gateway,Gateway_PAG
 SG_ DCDC_HV_Lokalaktiv : 61|1@1+ (1,0) [0|1] ""  Gateway,Gateway_PAG
 SG_ DCDC_HV_KD_Fehler : 63|1@1+ (1,0) [0|1] ""  Gateway,Gateway_PAG

BO_ 2549088455 KN_DCDC_HV_02: 8 DCDC_HV_02
 SG_ DCDC_HV_02_KompSchutz : 0|1@1+ (1,0) [0|1] "" Vector__XXX
 SG_ DCDC_HV_02_Abschaltstufe : 1|1@1+ (1,0) [0|1] "" Vector__XXX
 SG_ DCDC_HV_02_Transport_Mode : 2|1@1+ (1,0) [0|1] "" Vector__XXX
 SG_ DCDC_HV_02_Nachlauftyp : 4|4@1+ (1,0) [0|15] ""  Gateway,Gateway_PAG
 SG_ DCDC_HV_02_SNI : 8|8@1+ (1,0) [0|255] ""  Gateway,Gateway_PAG
 SG_ KN_DCDC_HV_02_ECUKnockOutTimer : 32|6@1+ (1,0) [0|62] "Unit_Minut"  Gateway,Gateway_PAG
 SG_ KN_DCDC_HV_02_BusKnockOut : 38|2@1+ (1,0) [0|3] ""  Gateway,Gateway_PAG
 SG_ KN_DCDC_HV_02_BusKnockOutTimer : 40|8@1+ (1,0) [0|254] ""  Gateway,Gateway_PAG
 SG_ NM_DCDC_HV_02_Wakeup : 48|8@1+ (1,0) [0|255] "" Vector__XXX
 SG_ KN_DCDC_HV_02_ECUKnockOut : 56|2@1+ (1,0) [0|3] ""  Gateway,Gateway_PAG
 SG_ NM_DCDC_HV_02_Lokalaktiv : 61|1@1+ (1,0) [0|1] ""  Gateway,Gateway_PAG
 SG_ DCDC_HV_02_KD_Fehler : 63|1@1+ (1,0) [0|1] ""  Gateway,Gateway_PAG

BO_TX_BU_ 1857 : Gateway,Gateway_PAG;
BO_TX_BU_ 1795 : Gateway,Gateway_PAG;
BO_TX_BU_ 1792 : Gateway,Gateway_PAG;
BO_TX_BU_ 2015 : Gateway,Gateway_PAG;
BO_TX_BU_ 1860 : Gateway,Gateway_PAG;
BO_TX_BU_ 2021 : Gateway,Gateway_PAG;
BO_TX_BU_ 2029 : BMC_MLBevo,BMS_MV;
BO_TX_BU_ 2023 : Gateway,Gateway_PAG;
BO_TX_BU_ 2549350937 : Gateway,Gateway_PAG;
BO_TX_BU_ 2549482009 : Gateway,Gateway_PAG;
BO_TX_BU_ 1865 : Gateway,Gateway_PAG;
BO_TX_BU_ 1858 : Gateway,Gateway_PAG;
BO_TX_BU_ 2549874831 : Gateway,Gateway_PAG;
BO_TX_BU_ 2549874862 : Gateway,Gateway_PAG;
BO_TX_BU_ 2549874844 : Gateway,Gateway_PAG;
BO_TX_BU_ 2549874887 : Gateway,Gateway_PAG;
BO_TX_BU_ 2549874871 : Gateway,Gateway_PAG;
BO_TX_BU_ 2550005943 : DCDC_800V_PAG,DCDC_HV;
BO_TX_BU_ 2549874811 : Gateway,Gateway_PAG;
BO_TX_BU_ 2549874886 : Gateway,Gateway_PAG;
BO_TX_BU_ 2549874868 : Gateway,Gateway_PAG;
BO_TX_BU_ 497 : Gateway,Gateway_PAG;
BO_TX_BU_ 960 : Gateway,Gateway_PAG;
BO_TX_BU_ 1646 : Gateway,Gateway_PAG;
BO_TX_BU_ 1649 : Gateway,Gateway_PAG;
BO_TX_BU_ 949 : Gateway,Gateway_PAG;
BO_TX_BU_ 1640 : Gateway,Gateway_PAG;
BO_TX_BU_ 1441 : Gateway,Gateway_PAG;
BO_TX_BU_ 2589283469 : Gateway,Gateway_PAG;
BO_TX_BU_ 2589283621 : Gateway,Gateway_PAG;
BO_TX_BU_ 2463978701 : Gateway,Gateway_PAG;
BO_TX_BU_ 1712 : Gateway,Gateway_PAG;
BO_TX_BU_ 1505 : Gateway,Gateway_PAG;
BO_TX_BU_ 1717 : Gateway,Gateway_PAG;
BO_TX_BU_ 1513 : Gateway,Gateway_PAG;
BO_TX_BU_ 1295 : Gateway,Gateway_PAG;
BO_TX_BU_ 2589283474 : Gateway,Gateway_PAG;
BO_TX_BU_ 2549088439 : DCDC_800V_PAG,DCDC_HV;
CM_ SG_ 2463978610 HVLM_RtmWarnLadeverbindung "RTM Charging connection fault";
CM_ SG_ 2463978610 HVLM_RtmWarnLadesystem "RTM Electrical machine CAN communication fault";
CM_ SG_ 2463978610 HVLM_RtmWarnLadestatus "RTM Warning of charging status fault";
CM_ SG_ 2463978610 HVLM_RtmWarnLadeKommunikation "RTM Warning of charging communction fault";
CM_ SG_ 2463978610 HVLM_Ladeanzeige_Anf "Lichtmuster für Charge Check
Sendeart = On Change, Zykluszeit = 500ms, Inhibitzeit = 10ms anlog des Signals im MQB (HVLM_10) auf dem A CAN";
CM_ SG_ 2463978610 HVLM_Ladeanzeige_Status "Funktionsstatus ChargeCheck
Sendeart = On Change, Zykluszeit = 500ms, Inhibitzeit = 10ms anlog des Signals im MQB (HVLM_10) auf dem A CAN";
CM_ SG_ 2463978610 HVLM_Ladeanzeige_Rampzeit "Zeit innerhalb der die gesendet Intensität für die Ladeanzeige erreicht werden soll";
CM_ SG_ 2463978610 HVLM_Ladeanzeige_Intens_Heck "aktuelle Helligkeit für die Anzeige des Ladestatus über Heck-Fahrzeug-Lichtelemente";
CM_ SG_ 2463978610 HVLM_Ladeanzeige_Intens_Front "aktuelle Helligkeit für die Anzeige des Ladestatus über Front-Fahrzeug-Lichtelemente ";
CM_ SG_ 2463978641 HVLM_11_CRC "Für MLB:
Berechnung siehe Lastenheft 'Kommunikationsabsicherung für FlexRay und CAN'
Ab MQB und MLBevo:
Berechnung siehe Lastenheft 'End-to-End Kommunikationsabsicherung'

Endwerte siehe Begleitdokument 'S-PDU Kennungsfolgen'";
CM_ SG_ 2463978641 HVLM_11_BZ "4bit Botschaftszähler, wird mit jeder Sendebotschaft inkrementiert";
CM_ SG_ 2463978641 HVLM_HVLB_SollSpannung_HVLS "Vorgabe SollSpannung Eingangsseite vom HVLM an HVLB";
CM_ SG_ 2463978641 HVLM_HVLB_Status "Statusübermittlung von Ladesäulenspezifika";
CM_ SG_ 2463978641 HVLM_HVLB_SollModus "Vorgabe SollModus vom HVLM an HVLB";
CM_ SG_ 2589283661 HVLM_PlanAnfr_Leistung "Ladeplan-Anfrage für die Ladeplanung: Leistung";
CM_ SG_ 2589283661 HVLM_PlanAnfr_Zaehler "Ladeplan-Anfrage für die Ladeplanung: Zähler";
CM_ SG_ 2589283661 HVLM_PlanAnfr_Dauer "Ladeplan-Anfrage für die Ladeplanung: Dauer";
CM_ SG_ 2589283661 HVLM_PlanAnfr_Ladeart "Anfrage Ladeart für Ladeplanerstellung";
CM_ SG_ 2589283661 HVLM_EnergieAnfr_SocStart "Energieanfrage für die Ladeplanung: Start-SoC";
CM_ SG_ 2589283661 HVLM_EnergieAnfr_SocZiel "Energieanfrage für die Ladeplanung: Ziel-SOC";
CM_ SG_ 2589283661 HVLM_EnergieAnfr_Zaehler "Fortlaufender Zähler für die Anfrage Energie";
CM_ SG_ 2589283661 HVLM_LadegrenzeAnfr_Leistung "Anfrage Ladeleistung mit welcher bis zu SOC aus BMS_LadegrenzeAntw_SOC geladen werden kann";
CM_ SG_ 2589283661 HVLM_LadegrenzeAnfr_Zaehler "Fortlaufender Zähler für die Anfrage Ladegrenze";
CM_ SG_ 1857 ISO_DCDC_Req_Data "Diagnose Request DCDC-Wandler";
CM_ SG_ 1963 ISO_DCDC_Resp_Data "Diagnose Response DCDC-Wandler";
CM_ SG_ 1795 ISO_Funktionaler_Req_Abgas "Funktionaler Request für abgasrelevante Steuergeraete";
CM_ SG_ 1792 ISO_ALL_01_Req_Data "Funktionaler Request ALL";
CM_ SG_ 2015 ISO_OBD_Funktionaler_Req_Data "Funktionaler Request für OBD relevante Steuergeraete";
CM_ SG_ 1860 ISO_Ladegeraet_Req_Data "Diagnose Request Ladegerät";
CM_ SG_ 1966 ISO_Ladegeraet_Resp_Data "Diagnose Response Ladegerät";
CM_ SG_ 2021 ISO_OBD_04_Req_Data "Diagnose Request 04 für OBD relevante Steuergeraete
MLB: BMS
MLBevo: BMS
MQB: BMC";
CM_ SG_ 2029 ISO_OBD_04_Resp_Data "Diagnose Response 04 für OBD relevante Steuergeraete
MLB: BMS
MLBevo: BMS
MQB: BMC";
CM_ SG_ 2023 ISO_OBD_06_Req_Data "Diagnose Request 06 für OBD relevante Steuergeraete
MLBevo: TME
MQB: Klima-SG";
CM_ SG_ 2031 ISO_OBD_06_Resp_Data "Diagnose Response 06 für OBD relevante Steuergeraete
MLBevo: TME
MQB: Klima-SG";
CM_ BO_ 2549350937 "Datenübertragung vom OBDC zum Datenanforderer OPR";
CM_ SG_ 2549350937 ISO_OBDC_RTM_Req_Data "Kommunikation zwischen OBDC (Onboard Data Collector) und Datenanforderer RTM (RealTimeMonitoring)";
CM_ BO_ 2549487874 "Datenübertragung vom OBDC zum Datenanforderer OPR";
CM_ SG_ 2549487874 ISO_OBDC_RTM_Resp_Data "Kommunikation zwischen OBDC (Onboard Data Collector) und Datenanforderer RTM (RealTimeMonitoring)";
CM_ BO_ 2549356802 "Datenübertragung vom OBDC zum Datenanforderer OPR";
CM_ SG_ 2549356802 ISO_RTM_OBDC_Req_Data "Kommunikation zwischen Datenanforderer RTM (RealTimeMonitoring) und OBDC (Onboard Data Collector)";
CM_ BO_ 2549482009 "Datenübertragung vom OBDC zum Datenanforderer OPR";
CM_ SG_ 2549482009 ISO_RTM_OBDC_Resp_Data "Kommunikation zwischen Datenanforderer RTM (RealTimeMonitoring) und OBDC (Onboard Data Collector)";
CM_ SG_ 1865 ISO_Sub_Gateway_Req_Data "Diagnose Request Sub_Gateway";
CM_ SG_ 1971 ISO_Sub_Gateway_Resp_Data "Diagnose Response Sub_Gateway";
CM_ SG_ 1858 ISO_TME_Req_Data "Diagnose Request TME";
CM_ SG_ 1964 ISO_TME_Resp_Data "Diagnose Response TME";
CM_ SG_ 2549874831 ISO_AWC_Req_Data "Diagnose Request Automatic wireless charging";
CM_ SG_ 2550005903 ISO_AWC_Resp_Data "Diagnose Response Automatic wireless charging";
CM_ SG_ 2549874862 ISO_BattRegelung_Req_Data "Diagnose Request BattRegelung";
CM_ SG_ 2550005934 ISO_BattRegelung_Resp_Data "Diagnose Response BattRegelung";
CM_ SG_ 2549874844 ISO_BMS_48V_Req_Data "Diagnose Request Batterie-Management-System 48V";
CM_ SG_ 2550005916 ISO_BMS_48V_Resp_Data "Diagnose Response Batterie-Management-System 48V";
CM_ SG_ 2549874887 ISO_DCDC_HV_02_Req_Data "Diagnose Request DCDC_HV_02";
CM_ SG_ 2550005959 ISO_DCDC_HV_02_Resp_Data "Diagnose Request DCDC_HV_02";
CM_ SG_ 2549874895 ISOx_DCDC_HV_03_Req_Data "Diagnose Request";
CM_ SG_ 2550005967 ISOx_DCDC_HV_03_Resp_Data "Diagnose Response";
CM_ SG_ 2549874869 ISOx_FCU_Req_Data "Diagnose Request";
CM_ SG_ 2550005941 ISOx_FCU_Resp_Data "Diagnose Response";
CM_ SG_ 2549874811 ISO_Hybrid_01_Req_Data "Diagnose Request Batterie-Management-System";
CM_ SG_ 2550005883 ISO_Hybrid_01_Resp_Data "Diagnose Response Batterie-Management-System";
CM_ SG_ 2549874886 ISO_Ladegeraet_2_Req_Data "Diagnose Request Ladegerät_2";
CM_ SG_ 2550005958 ISO_Ladegeraet_2_Resp_Data "Diagnose Response Ladegerät_2";
CM_ SG_ 2549874868 ISOx_TelemetrieSG_Req_Data "Diagnose Request TelemetrieSG";
CM_ SG_ 2550005940 ISOx_TelemetrieSG_Resp_Data "Diagnose Response TelemetrieSG";
CM_ SG_ 497 KY_IDG_in_Reichweite "Für elektrisch betätigte Türen und Klappen muss für eine Betätigung über Funk eine Reichweitenbegrenzung eingeführt werden. Diese Bit zeigt an, dass sich der Funkschlüssel innerhalb der geforderten Reichweite befindet";
CM_ SG_ 497 KY_Auf_Taste "Auf-Taste Funkschluessel";
CM_ SG_ 497 KY_HDF_Taste "HDF Taste am Funkschluessel";
CM_ SG_ 497 KY_Panik_Taste "Panik Taste Funkschluessel";
CM_ SG_ 497 KY_Zu_Taste "Zu-Taste Funkschluessel";
CM_ SG_ 497 KY_FT_Entriegelung_Autorisiert "Erkennung / Authorisierung Keyless FT
";
CM_ SG_ 497 KY_FT_Verriegelung_Autorisiert "Authorisierung Verriegelungssensor Keyless FT
";
CM_ SG_ 497 KY_BT_Entriegelung_Autorisiert "Erkennung / Authorisierung Keyless BT
";
CM_ SG_ 497 KY_BT_Verriegelung_Autorisiert "Authorisierung Verriegelungssensor Keyless BT
";
CM_ SG_ 497 KY_HFS_Entriegelung_Autorisiert "Erkennung / Authorisierung Keyless HFS
";
CM_ SG_ 497 KY_HFS_Verriegelung_Autorisiert "Authorisierung Verriegelungssensor Keyless HFS

";
CM_ SG_ 497 KY_HBFS_Entriegelung_Autorisiert "Erkennung / Authorisierung Keyless HBFS
";
CM_ SG_ 497 KY_HBFS_Verriegelung_Autorisiert "Authorisierung Verriegelungssensor Keyless HBFS


";
CM_ SG_ 497 KY_Front_Entr_Autorisiert "Erkennung / Authorisierung Keyless Front";
CM_ SG_ 497 KY_Front_Verr_Autorisiert "Authorisierung Verriegelungssensor Keyless Front";
CM_ SG_ 497 KY_HD_Entriegelung_Autorisiert "Erkennung / Authorisierung Keyless Heck
";
CM_ SG_ 497 KY_HD_Verriegelung_Autorisiert "Autorisierung der Schließanforderung über Verriegelungsinnentaster";
CM_ SG_ 497 KY_Bereich "Schlüsselentfernung für Funktionen Annäherungslicht, automatisches Entriegeln";
CM_ SG_ 497 KY_Position "Schlüsselposition für Funktionen Annäherungslicht, automatisches Entriegeln";
CM_ SG_ 497 KY_ZV_Signatur "Signatur der ZV";
CM_ SG_ 497 Schluesselnr_Personalisierung "Signal gibt die jewels aktuelle Schlüsselnummer für die Personalisierung wieder";
CM_ SG_ 497 FFB_FDF_Taste "FDF Taste am Funkschluessel";
CM_ SG_ 497 FFB_Joker_Taste "Frei konfigurierbare Taste auf der Funkfernbedienung (für Verdecktaste, UGDO Taste).
";
CM_ SG_ 497 FFB_Park_Taste "Parktaste Funkschluessel";
CM_ SG_ 497 FFB_Remotestart_Taste "Remotestart Taste Funkschluessel";
CM_ SG_ 497 FBS_Aktivierung_Pilot_Parken "Aktivierung der Funktion pilotiertes Parken";
CM_ SG_ 497 KY_Schluessel_im_Fzg "Zeigt einen erkannten Schlüssel im Fzg an.";
CM_ SG_ 497 KY_EasyClose_Abbruch "ID-Geber während HD-Zufahrt im Nahbereich EasyClose erkannt";
CM_ SG_ 497 KY_EasyClose_Status "Signal zur LED Ansteuerung im HD-Verriegelungstaster für die Funktion EasyClose.";
CM_ SG_ 497 KY_HD_Auffahrt "Auffahrt HD nach Wiedereintritt ID-Geber in EasyClose Nahbereich";
CM_ SG_ 497 KY_HD_Zufahrt "Zufahrt HD nach erfolgreicher Funktion EasyClose";
CM_ SG_ 497 KY_LKL_1_Autorisierung "Schlüsselstatus für Anfragen der Ladeklappe 1";
CM_ SG_ 497 KY_LKL_2_Autorisierung "Schlüsselstatus für Anfragen der Ladeklappe 2";
CM_ BO_ 960 "MQB";
CM_ SG_ 960 Klemmen_Status_01_CRC "Für MLB:
'Berechnung siehe Lastenheft 'Kommunikationsabsicherung für FlexRay und CAN''

Ab MQB und MLBevo:
'Berechnung siehe Lastenheft 'End-to-End Kommunikationsabsicherung''

Endwerte siehe Begleitdokument 'S-PDU Kennungsfolgen'";
CM_ SG_ 960 Klemmen_Status_01_BZ "4bit Botschaftszaehler; wird in jeder Sendebotschaft inkrementiert";
CM_ SG_ 960 RSt_Fahrerhinweise "Über das Signal fordert das BCM Fahrerhinweise im Kombi für die Funktion RemoteStart an.";
CM_ SG_ 960 ZAS_Kl_S "Klemme S: S-Kontakt (Schluessel steckt)
";
CM_ SG_ 960 ZAS_Kl_15 "Klemme 15: Zuendung (SW-Kl.15)
";
CM_ SG_ 960 ZAS_Kl_X "Klemme 75
";
CM_ SG_ 960 ZAS_Kl_50_Startanforderung "Klemme 50: Startwunsch Fahrer
";
CM_ SG_ 960 BCM_Remotestart_Betrieb "Zeigt den Status des RemoteStarts an, d.h. KL15_RSt ist aktiviert und der Motorlauf ist im RSt-Betrieb aktiv.";
CM_ SG_ 960 ZAS_Kl_Infotainment "Separate Klemmeninformation für das Infotainment. Signal entspricht im wesentlichen einer Klemme S Information, kann aber über einen Vor - bzw. Nachlauf zu Klemme S verfügen. 
Ein konkreter Anwendungsfall für einen Nachlauf ist die Abschaltung der Klemme";
CM_ SG_ 960 BCM_Remotestart_KL15_Anf "Zeigt den Status der Aktivierung der KL15_RST durch das BCM an.";
CM_ SG_ 960 BCM_Remotestart_MO_Start "Nachdem das BCM die Remotestart MSG Freigabe sicher erkannt hat, fordert das BCM wiederum über dieses Signal vom MSG einen Motorstart durchzuführen.";
CM_ SG_ 960 KST_Warn_P1_ZST_def "Kombi Prio Warnung Klemmensteuerung 
Zündschloß defekt, Service aufsuchen!";
CM_ SG_ 960 KST_Warn_P2_ZST_def "Kombi Prio Warnung Klemmensteuerung
Zündschloß defekt!
";
CM_ SG_ 960 KST_Fahrerhinweis_1 "Signalisierung Fahrerhinweis 1 der Klemmensteuerung an das Kombi";
CM_ SG_ 960 KST_Fahrerhinweis_2 "Signalisierung Fahrerhinweis 2 der Klemmensteuerung an das Kombi";
CM_ SG_ 960 BCM_Ausparken_Betrieb "Anforderung zur erneuten Lampenaufprüfung und Anzeige von Warnhinweisen nach einem pilotierten Ausparkvorgang (Trigger: fallende Flanke)";
CM_ SG_ 960 KST_Fahrerhinweis_4 "Signalisierung Fahrerhinweis 4 der Klemmensteuerung an das Kombi";
CM_ SG_ 960 KST_Fahrerhinweis_5 "Anzeigesignal für RemoteStart";
CM_ SG_ 960 KST_Fahrerhinweis_6 "Signal aktiviert die Kombi-Anzeigeinstrumente (Drehzahl, Tankinhalt, Kühlmitteltemperatur) während aktiviertem RemoteStart-Betrieb";
CM_ BO_ 1646 "ab MQB 7.3";
CM_ SG_ 1646 KL_STL_aktiv "Betriebsstatus Standlueftung
";
CM_ SG_ 1646 KL_STH_aktiv "Betriebsstatus Standheizung
";
CM_ SG_ 1646 KL_Solarluefter_aktiv "Betriebsstatus Solarluefter
";
CM_ SG_ 1646 KL_Umluft_Taste "Betaetigung Umlufttaste
";
CM_ SG_ 1646 KL_Geblaese_Fond_Status "Status Geblaese









";
CM_ SG_ 1646 KL_STH_Ansteuerung "Ansteuerung STH

";
CM_ SG_ 1646 KL_STH_Betriebsdauer "Betriebsdauer STH";
CM_ SG_ 1646 KL_Magnetventil "Anforderung des Bypassventils.";
CM_ SG_ 1646 KL_WaPu "Ansteuerung der Standheizungswasserpumpe";
CM_ SG_ 1646 KL_Geblaese_Status "Status Geblaese









";
CM_ SG_ 1646 KL_Restwaerme_aktiv "Signal zur Aktivierung/Deaktivierung der Wasserpumpe bei Restwärme; 
reduzierte IRÜ Empfindlichkeit";
CM_ SG_ 1646 KL_Kompressorkupplung "Signal zur Aktivierung/Deaktivierung der Kompressorkupplung";
CM_ SG_ 1646 KL_BCmE_Livetip_Freigabe "Status der Klimaanlage. 
Zeigt an, ob der Livetip 'Fenster schließen wegen Ineffizienz Klimaanlage' sinvollerweise angezeigt werden soll";
CM_ SG_ 1646 KL_HYB_ASV_hinten_schliessen_Anf "Anforderung der Klima an das BMS, das Absperrventil des Kältemittelkreislaufs zur Batteriekühlung zu schliessen";
CM_ SG_ 1646 KL_HYB_ASV_vorne_schliessen_Anf "Anforderung der Klima an das BMS, das Absperrventil des Kältemittelkreislaufs der Klimaanlage zu schliessen";
CM_ SG_ 1646 KL_ErwVK_Zusatzrelais "Steuerung Zusatzrelais für Erweiterte Voko";
CM_ SG_ 1646 KL_Status_Beduftung "Status der Beduftung";
CM_ SG_ 1646 KL_Status_Ionisator_Front "Status des Ionisator Front";
CM_ SG_ 1646 KL_STH_Timer_Status "Status des Standheizungstimers (für VW621 initial zur Übermittelung der Information von KlimaMSB zu Kombi)
Zur Anzeige im Kombi für 10 Sekunden nach Kl.15 aus;";
CM_ SG_ 1646 KL_ErwVK_Anf "Erweiterte Voko angefordertert / aktiv";
CM_ SG_ 1646 KL_Innen_Temp "Innentemperatur

";
CM_ SG_ 1646 KL_I_Geblaese_Fond "Stromaufnahme Gebläse Heck";
CM_ SG_ 1646 KL_Anf_AussenspiegelHzg "Anforderung Außenspiegelheizung seitens Klimafunktion (z.B. bei Erweiterter VoKo)";
CM_ SG_ 1646 KL_Heizkreisventilstellung "Bei MQB PHEV: Stellung Heizkreisventil Motor";
CM_ SG_ 1646 KL_FSH_Automatikbetrieb "Ermöglicht eine Unterscheidung von Anforderung FSH durch Kundenwunsch und Anforderung FSH durch Regelung des Klimasteuergeräts.
Das Signal liegt als Pegel an.";
CM_ SG_ 1646 KL_SIH_LEH_Verteilung_VL "Vom Kunden eingestellte Aufteilung der Heizleistung auf Sitzfläche und Lehnefläche für Sitz vorne links";
CM_ SG_ 1646 KL_SIH_LEL_Verteilung_VL "Vom Kunden eingestellte Aufteilung der Lüftungsleistung auf Sitzfläche und Lehnenfläche für Sitz vorne links";
CM_ SG_ 1646 KL_SIH_LEH_Verteilung_VR "Vom Kunden eingestellte Aufteilung der Heizleistung auf Sitzfläche und Lehnefläche für Sitz vorne rechts";
CM_ SG_ 1646 KL_SIH_LEL_Verteilung_VR "Vom Kunden eingestellte Aufteilung der Lüftungsleistung auf Sitzfläche und Lehnenfläche für Sitz vorne rechts";
CM_ SG_ 1649 KL_ZZ_Minute "Zielzeittimeranzeige im Display der Funkfernbedienung (Minute); Initwert ist der zuletzt gültige Wert";
CM_ SG_ 1649 KL_ZZ_Status_Timer "Timerstatusanzeige im Display der Funkfernbedienung (Timer aktiv/n.aktiv)";
CM_ SG_ 1649 KL_ZZ_Monat "Zielzeittimeranzeige im Display der Funkfernbedienung (Datum, Monat); Initwert ist der zuletzt gültige Wert";
CM_ SG_ 1649 KL_ZZ_Stunde "Zielzeittimeranzeige im Display der Funkfernbedienung (Stunde); Initwert ist der zuletzt gültige Wert";
CM_ SG_ 1649 KL_ZZ_Betriebsmodus "Betriebsdauerberechnung anhand Aussentemperaturauswertung mit Faktor 'ZZ_Betriebsmodus'";
CM_ SG_ 1649 KL_ZZ_Tag "Zielzeittimeranzeige im Display der Funkfernbedienung (Datum, Tag); Initwert ist der zuletzt gültige Wert";
CM_ SG_ 1649 KL_Betriebsmodus_FH "Synchronisation des Betriebsmodus zwischen Front und Fond";
CM_ SG_ 1649 KL_Stopp_Wiederstart_Anz_01 "Dieses Signal gibt die detaillierte Begründung für eine Stoppverbot-/Wiederstartanfrage der Klima-SG an.";
CM_ SG_ 1649 KL_Stopp_Wiederstart_Anz_02 "Dieses Signal gibt die detaillierte Begründung für eine Stoppverbot-/Wiederstartanfrage der Klima-SG an.";
CM_ SG_ 1649 KL_Stopp_Wiederstart_Anz_03 "Dieses Signal gibt die detaillierte Begründung für eine Stoppverbot-/Wiederstartanfrage der Klima-SG an.";
CM_ SG_ 1649 KL_Stopp_Wiederstart_Anz_04 "Dieses Signal gibt die detaillierte Begründung für eine Stoppverbot-/Wiederstartanfrage der Klima-SG an.";
CM_ SG_ 1649 KL_Stopp_Wiederstart_Anz_05 "Dieses Signal gibt die detaillierte Begründung für eine Stoppverbot-/Wiederstartanfrage der Klima-SG an.";
CM_ SG_ 1649 KL_Stopp_Wiederstart_Anz_06 "Dieses Signal gibt die detaillierte Begründung für eine Stoppverbot-/Wiederstartanfrage der Klima-SG an.";
CM_ SG_ 1649 KL_Stopp_Wiederstart_Anz_07 "Dieses Signal gibt die detaillierte Begründung für eine Stoppverbot-/Wiederstartanfrage der Klima-SG an.";
CM_ SG_ 1649 KL_Stopp_Wiederstart_Anz_08 "Dieses Signal gibt die detaillierte Begründung für eine Stoppverbot-/Wiederstartanfrage der Klima-SG an.";
CM_ SG_ 1649 KL_Stopp_Wiederstart_Anz_09 "Dieses Signal gibt die detaillierte Begründung für eine Stoppverbot-/Wiederstartanfrage der Klima-SG an.";
CM_ SG_ 1649 KL_Stopp_Wiederstart_Anz_Std1 "Dieses Signal gibt die detaillierte Begründung für eine Stoppverbot-/Wiederstartanfrage der Klima-SG an.";
CM_ SG_ 1649 KL_Stopp_Wiederstart_Anz_Std2 "Dieses Signal gibt die detaillierte Begründung für eine Stoppverbot-/Wiederstartanfrage der Klima-SG an.";
CM_ BO_ 949 "ab MQB 7.4";
CM_ SG_ 949 KL_Drehz_Anh "Drehzahlanhebung vom Motor angefordert

";
CM_ SG_ 949 KL_Vorwarn_Komp_ein "Vorwarnung Kompressor ein; 140ms vorher; Information für Motor zum Aufbau Momentenreserve";
CM_ SG_ 949 KL_AC_Schalter "AC Schalter
";
CM_ SG_ 949 KL_Vorwarn_Zuheizer_ein "Vorwarnung Zuheizerbetrieb
";
CM_ SG_ 949 KL_Zustand "Beschreibt den Zustand des Klima-/Heizungsbedienteils. (OFF-Mode Bedienteil)

PAG (MLB): Beschreibt den Zustand des Kompressors";
CM_ SG_ 949 KL_Kompressorkupplung_linear "Sollwert zur Ansteuerung der Kompressorkupplung";
CM_ SG_ 949 KL_Charisma_FahrPr "MLBevo: Aktuelles Fahrprogramm des Charisma-Teilnehmers (siehe Systemlastenheft Drive Select)
MQB: Istwert der Kennlinie (siehe Systemlastenheft MQB FPA)";
CM_ SG_ 949 KL_Charisma_Status "Charisma Systemstatus des Charisma-Teilnehmers

Wert 0x3 ist nur für Fahrzeuge ab MQB relevant";
CM_ SG_ 949 KL_nachtr_Stopp_Anf "Dieses Signal dient dem Motor als Trigger, dass ein nachträglicher Motorstopp eingeleitet werden kann, wenn es die Bedingungen des StSt Koordinators dies zulassen. ";
CM_ SG_ 949 KL_T_Charge "Signal für Tastenbetätigung Charge-Taste (SOC Increasing)";
CM_ SG_ 949 KL_Last_Kompr "Aktuelles Verlustmoment der Klimaanlage bezogen auf die Kurbelwelle. Wird der Klimakompressor nicht angesteuert, ist das Schleppmoment bezogen auf die Kurbelwelle zu senden.";
CM_ SG_ 949 KL_Spannungs_Anf "Forderung des Klima-SG's zur Spannungsanhebung.";
CM_ SG_ 949 KL_Thermomanagement "Stufen des Thermomanagements;
Bei Klemme 15 AUS und erkannten Timeout zum Klimabedienteil (z.B. Klimabedienteil während des Motorsteuergeräte-Kommunikations-Nachlaufs bereits im NM-Zustand ¿Bus Sleep¿)
erfolgt keine Ansteuerung der Wasserpumpe durch die";
CM_ SG_ 949 KL_StartStopp_Info "Stopp-Freigabe und Start-Anforderung an den Start-Stopp-Koordinator";
CM_ SG_ 949 KL_Freilauf_Info "Freilauf Informationssignal von Klima zum Freilaufkoordinator. Klima kann über dieses Signal den Freilauf freigeben, verhindern bzw. explizit anfordern.";
CM_ SG_ 949 KL_Anf_KL "Anforderung Kühlerlüfter der Klimaanlage in Prozent

";
CM_ SG_ 949 KL_el_Zuheizer_Stufe "Vorgabe für Motorsteuergeraet PTC-Stufe; im MLB-B8 und MQB nur Stufe 0...3

";
CM_ SG_ 949 KL_Ausstattung_Klima "Austtattungsart der Klimabedienung";
CM_ SG_ 949 KL_Variante_Standheizung "Identifikation der Variante der Standheizungen zur Berechnung der energetischen Zielzeit";
CM_ BO_ 1640 "ab MQB IS-4";
CM_ SG_ 1640 KL_LRH_Taster "Tasterbetätigung Lenkradheizung";
CM_ SG_ 1640 KL_LRH_Stufe "Eingestellte Temperaturstufe der Lenkradheizung";
CM_ SG_ 1640 HSH_Taster "An-/Abforderung Heckscheibenheizung über spezielles Tastersignal
";
CM_ SG_ 1640 FSH_Taster "Tasterbetätigung Frontscheibenheizung
";
CM_ SG_ 1640 KL_Zuheizer_Freigabe "Freigabe Zuheizer
";
CM_ SG_ 1640 KL_Beschlagsgefahr "Beschlagsgefahr auf der Frontscheibe im Bereich des Spiegelfusses. Dient zur präventiven Ansteuerung der  Kamera-Scheibenheizung, um Kamera-Blindheit zu vermeiden
PHEV: volle Leistungsfreigabe 
HV Heizer und HV EKK bei Scheibenbeschlag ";
CM_ SG_ 1640 KL_SIH_Soll_li "Einstellung Sitzheizung Fahrer (0...6)";
CM_ SG_ 1640 KL_SIH_Soll_re "Einstellung Sitzheizung Beifahrer (0...6)";
CM_ SG_ 1640 KRH_Soll_li "Ausgabe des Sollwertes für die Kopfraumheizung links.";
CM_ SG_ 1640 KL_SIL_Soll_li "Einstellung Sitzlüftung Fahrer (0...6)";
CM_ SG_ 1640 KL_SIL_Soll_re "Einstellung Sitzlüftung Beifahrer (0...6)";
CM_ SG_ 1640 KRH_Soll_re "Ausgabe des Sollwertes für die Kopfraumheizung rechts.";
CM_ SG_ 1640 KL_Geblspng_Soll "Ausgabe des Sollwertes für die Spannung des Klimagebläsemotores vorne.







";
CM_ SG_ 1640 KL_Geblspng_Fond_Soll "Ausgabe des Sollwertes für die Spannung des Klimagebläsemotores hinten.






";
CM_ SG_ 1640 KL_I_Geblaese "Stromaufnahme Gebläse";
CM_ SG_ 1640 KL_Kompressorstrom_soll "Sollvorgabe Klima-Kompressorstrom";
CM_ SG_ 1640 KL_Umluftklappe_Status "Status Umluftklappe";
CM_ SG_ 1640 KL_PTC_Verbauinfo "Im Klima- bzw. Heizungsbedienteil wird der Verbau eines PTCs und dessen elektr. Leistungsklasse codiert";
CM_ SG_ 1441 KL_Temp_Soll_hl "Eingestellte Solltemperatur hinten links für verteilte Komfortfunktionen";
CM_ SG_ 1441 KL_Temp_Soll_hr "Eingestellte Solltemperatur hinten rechts für verteilte Komfortfunktionen";
CM_ SG_ 1441 KL_Temp_Soll_vl "Eingestellte Solltemperatur vorne links für verteilte Komfortfunktionen";
CM_ SG_ 1441 KL_Temp_Soll_vr "Eingestellte Solltemperatur vorne rechts für verteilte Komfortfunktionen";
CM_ SG_ 1441 KL_SIH_Stufe_hl "Eingestellte Sitzheizungsstufe hinten links für verteilte Komfortfunktionen";
CM_ SG_ 1441 KL_SIH_Stufe_hr "Eingestellte Sitzheizungsstufe hinten rechts für verteilte Komfortfunktionen";
CM_ SG_ 1441 KL_SIL_Stufe_hl "Eingestellte Sitzlüftungsstufe hinten links für verteilte Komfortfunktionen";
CM_ SG_ 1441 KL_SIL_Stufe_hr "Eingestellte Sitzlüftungsstufe hinten rechts für verteilte Komfortfunktionen";
CM_ SG_ 1441 KL_SIL_LEL_Verteilung_HR "Vom Kunden eingestellte Aufteilung der Lüftungsleistung auf Sitzfläche und Lehnenfläche für Sitz hinten rechts";
CM_ SG_ 1441 KL_SIL_LEL_Verteilung_HL "Vom Kunden eingestellte Aufteilung der Lüftungsleistung auf Sitzfläche und Lehnenfläche für Sitz hinten links";
CM_ SG_ 1441 KL_SIH_LEH_Verteilung_HR "Vom Kunden eingestellte Aufteilung der Heizleistung auf Sitz und Lehne für Sitz hinten rechts.";
CM_ SG_ 1441 KL_PTC_linear_Anf "Kundenanforderung des PTC (linear)";
CM_ SG_ 1441 KL_SIH_LEH_Verteilung_HL "Vom Kunden eingestellte Aufteilung der Heizleistung auf Sitz und Lehne für Sitz hinten links";
CM_ SG_ 1441 KL_Frischluftklappe_Status "Aktuelle Position der Frischluftklappe";
CM_ SG_ 2589283469 KL_Verdampferleistung "Ist-Kühlleistung am Verdampfer
Bei KL_Verdampferleistung_Faktor = 1 wird der Signalwert mit dem Faktor 2 multipliziert.";
CM_ SG_ 2589283469 KL_VK_Anf "Starten einer Standklimatisierung ausgehend von der Climatronic Richtung Lademanagment.";
CM_ SG_ 2589283469 KL_Verdampferleistung_Faktor "Faktor für Signal KL_Verdampferleistung, 
Bei Signalwert 1 wird das Signal KL_Verdampferleistung mit dem Faktor 2 Multipliziert";
CM_ SG_ 2589283469 KL_Geblaese_Fond_erw "Erwarteter Fond-Gebläsestatus im eingeschwungenen Zustand";
CM_ SG_ 2589283469 KL_Geblaese_erw "Erwarteter Gebläsestatus im eingeschwungenen Zustand";
CM_ SG_ 2589283469 KL_Vorkond_Strategie "Strategie der Vorkonditionierung des Innenraums";
CM_ SG_ 2589283469 KL_Tempklappe_re "Sollwert der Temperaturklappe rechts";
CM_ SG_ 2589283469 KL_Tempklappe_li "Sollwert der Temperaturklappe links (2 zonig)
Sollwert der Temperaturklappe (1-zonig)";
CM_ SG_ 2589283469 KL_Tempklappe_Fond "Sollwert der Temperaturklappe Fond";
CM_ SG_ 2589283469 KL_Kuehllstg_Delta_Eingriff "Durch Kundeneingriff erwartete Veränderung der  Kühlleistung bei aktuellen klimatischen Bedingungen";
CM_ SG_ 2589283469 KL_Heizlstg_Delta_Eingriff "Durch Kundeneingriff erwartete Veränderung der  Heizleistung bei aktuellen klimatischen Bedingungen";
CM_ SG_ 2589283621 KL_NV_Energie_Anf "Benötigte Energie (12V) für die Erweiterte Vorkonditionierung";
CM_ SG_ 2589283621 KL_FlHz_Soll_VL "Sollwertvorgabe für Flächenheizung vorne links";
CM_ SG_ 2589283621 KL_FlHz_Soll_HL "Sollwertvorgabe für Flächenheizung hinten links";
CM_ SG_ 2589283621 KL_FlHz_Soll_VR "Sollwertvorgabe für Flächenheizung vorne rechts";
CM_ SG_ 2589283621 KL_FlHz_Soll_HR "Sollwertvorgabe für Flächenheizung hinten rechts";
CM_ SG_ 2589283621 KL_Umluft_Connect_status "Umluft Status zum Backend Server";
CM_ SG_ 2589283621 KL_ECO_PRO_Aktiv "Funktion ECO-PRO durch Kundeneingriff aktiviert";
CM_ SG_ 2589283621 KL_QBit_Sonnenintensitaet "Gültigkeitsbit für Signal KL_Sonenintensität
Gesetzt bei Ersatzwert, Init oder Fehler.";
CM_ SG_ 2589283621 KL_ZR_Anforderung "Anforderung an MIB die Displays zu aktivieren";
CM_ SG_ 2589283621 KL_ACmax_Aktiv "Funktion ACmax durch Kundeneingriff aktiviert";
CM_ SG_ 2589283621 KL_Defrost_Aktiv "Funktion Defrost durch Kundeneingriff aktiviert";
CM_ SG_ 2589283621 KL_ECO_Aktiv "Funktion Eco durch Kundeneingriff aktiviert";
CM_ SG_ 2589283621 KL_Status_Klimastil "Signal für aktuelles Programm des KBT";
CM_ SG_ 2589283621 KL_Kundeneingriff_Geblaese "Manueller Kundeneingriff in die Geblaeseregelung";
CM_ SG_ 2589283621 KL_Thermischer_Bedarf "Temperierungsbedarf zur Innenraumklimatisierung";
CM_ SG_ 2589283621 KL_Eps_Innen "mittlerer Wert der Klima Regelabweichung";
CM_ SG_ 2589283621 KL_Sonnenintensitaet "gemittelte eingestrahlte Leistung in W/m2";
CM_ SG_ 2463978701 KL_Temp_Soll_vr_Prognose "Solltemperatur vorne rechts (Kundenwunsch) für die Prognose bei einem Fahrprogrammwechsel im BEV";
CM_ SG_ 2463978701 KL_Leistungsreduktions_Hinweis "Signal zum Auslösen der Kombi-Meldung das bei einem Klima Defizit die Leistung der Klimatisierung reduziert wird.";
CM_ SG_ 2463978701 KL_AC_Schalter_Prognose "Erwarteter Zustand des Klimakompressorwunschs bei einem Fahrprogramm-Wechsel";
CM_ SG_ 2463978701 KL_Temp_Soll_vl_Prognose "Solltemperatur vorne links (Kundenwunsch) für die Prognose bei einem Fahrprogrammwechsel im BEV";
CM_ SG_ 2463978701 KL_Sollklimamodus_FPR_1 "Ziel Modus der Klimatisierung für ein definierbares Fahrprogramm.";
CM_ SG_ 2463978701 KL_Temp_Soll_hr_Prognose "Solltemperatur hinten rechts (Kundenwunsch) für die Prognose bei einem Fahrprogrammwechsel im BEV";
CM_ SG_ 2463978701 KL_Sollklimamodus_FPR_2 "Ziel Modus der Klimatisierung für ein definierbares Fahrprogramm.";
CM_ SG_ 2463978701 KL_Temp_Soll_hl_Prognose "Solltemperatur (Kundenwunsch) für die Prognose bei einem Fahrprogrammwechsel im BEV";
CM_ SG_ 2463978701 KL_Sollklimamodus_FPR_3 "Ziel Modus der Klimatisierung für ein definierbares Fahrprogramm.";
CM_ BO_ 1712 "D4 und B8-PA

1:1 LIN-CAN Botschaft, nur bei Kl.15 EIN gesendet";
CM_ SG_ 1712 FS_ResponseError "siehe LIN2.0-Specification
(Darf nicht über ein Fehlergueltigkeitsbit abgesichtert werden!)";
CM_ BO_ 1505 "ab MQB 7.3";
CM_ SG_ 1505 BCM1_Aussen_Temp_ungef "ungefilterter Wert des Aussentemperatursensors
";
CM_ SG_ 1505 BCM_Heizungsabsperrventil_Status "Das Signal beschreibt den Zustand des Heizungsabsperrventils, welches als Portexpander vom BCM1 elektrisch angesteuert wird.";
CM_ SG_ 1505 BCM_Heizungspumpe_Status "Das Signal beschreibt den Zustand der Heizungspumpe, welche als Portexpander vom BCM1 elektrisch angesteuert wird.";
CM_ SG_ 1505 BCM_Kompressorkupplung_Status "Das Signal beschreibt den Zustand der Klimakompressorkupplung, welche als Portexpander vom BCM1 elektrisch angesteuert wird.";
CM_ SG_ 1505 BCM1_PTC_stufig_Status "Status des BCM1-Heizverbrauchers PTC (stufig)";
CM_ SG_ 1505 BCM1_FStatus_Aussentemp_ungef "Fehlerstatus für Aussentemperatur (Kombianzeige)";
CM_ SG_ 1505 BCM1_Kompressorstrom_ist "IST-Strom vom Klima-Kompressor";
CM_ SG_ 1505 BCM1_OBD_FStatus_ATemp "Fehlerstatus Umgebungstemperatursensor (OBD relevanter Sensor)
";
CM_ BO_ 1717 "ab D4 gültig  --  geänderter Wertebereich und Signalnamen
1:1 LIN-CAN Botschaft vom BCM1, nur bei Kl.15 EIN gesendet";
CM_ SG_ 1717 FSA_Taupunkt "'Init' falls nicht verbaut";
CM_ SG_ 1717 FSA_Err_Defekt_Tsens_TF "OBD TestFailed Flag, Statusbotschaft für diden Feuchtesensor, testFailed (TF)";
CM_ SG_ 1717 FSA_Luftfeuchte_TNCTOC "Signal meldet den Status der Diagnosen nach OBD LIN-LAH, testNotCompletedThisOperationCycle (TNCTOC)";
CM_ SG_ 1717 FSA_Luftfeuchte_TF "OBD TestFailed Flag, Statusbotschaft für den Feuchtesensor, testFailed (TF)";
CM_ SG_ 1717 FSA_Err_Unterspannung_TF "OBD TestFailed Flag, Statusbotschaft für den Feuchtesensor, testFailed (TF)";
CM_ SG_ 1717 FSA_Err_RAMROM_Check_TF "OBD TestFailed Flag, Statusbotschaft für den Feuchtesensor, testFailed (TF)";
CM_ SG_ 1717 FSA_ResponseError "siehe LIN2.0-Specification
(Darf nicht über ein Fehlergueltigkeitsbit abgesichtert werden!)";
CM_ SG_ 1717 FSA_Temp_Luft "gemessene Temperatur im Luftstrom (z.B. NTC am Sensor)
'Init' falls nicht verbaut
(+61°C bedeutet: Temp_Luft > 60,9°C !)";
CM_ SG_ 1717 FSA_Err_RAMROM_Check_TNCTOC "Signal meldet den Status der Diagnosen nach OBD LIN-LAH, testNotCompletedThisOperationCycle (TNCTOC)";
CM_ SG_ 1717 FSA_Lokal_Bus_elektr_Fehler "Bit wird gesetzt, wenn fuer lokaler Datenbus elektr. Fehler eingetragen wird";
CM_ SG_ 1717 FSA_Timeout "Bit wird gesetzt, wenn Time-Out DTC eingetragen wird";
CM_ SG_ 1717 FSA_Lokal_Bus_Unterbrechung "Bit wird gesetzt, wenn fuer lokaler Datenbus DTC wegen Unterbrechung eingetragen wird";
CM_ SG_ 1717 FSA_Err_Ueberspannung_TF "OBD TestFailed Flag, Statusbotschaft für den Feuchtesensor Außen, testFailed (TF)";
CM_ SG_ 1717 FSA_Luftfeuchte_rel "Maximaler Feuchtebereich bis 126% für theoretisch errechnete Feuchtewerte des Sensors. Signalwerte >100% bedeuten  rel. Feuchte = 100%";
CM_ SG_ 1717 FSA_HW "Hardwarestand";
CM_ SG_ 1717 FSA_SW "Softwarestand";
CM_ SG_ 1717 FSA_Sensorheizung_Status "Status der Heizung im Feuchteelement (z.B. SHT10).
0 (=inaktiv) auch bei nicht verbaut";
CM_ SG_ 1717 FSA_Err_Defekt_HumSense_TF "OBD TestFailed Flag, Statusbotschaft für Feuchtesensor außen, testFailed (TF)";
CM_ SG_ 1717 FSA_Err_Defekt_HumSens_TNCTOC "OBD TestNotCompletedThisOperationCycle nach LIN LAH für Feuchteelement, testNotCompletedThisOperationCycle (TNCTOC)";
CM_ SG_ 1717 FSA_ErrMemState "OBD Signal statusbotschaft für den Feuchtesensor außen";
CM_ SG_ 1513 DS_Kaeltemittel_P "Drucksensor Kältemittel Druck, das Signal wird bei Kl.15 AUS mit dem letzten empfangenen Wert gesendet";
CM_ SG_ 1513 DS_Status "Status des Drucksensors (= LIN-Slave BCM1);
bei Kl.15 AUS wird für 4s noch der letzte Wert gesendet, danach wird das Signal mit dem Wert 3 (= Fehler) gesendet";
CM_ SG_ 1513 ION_Status_LED "Status Funktions LED";
CM_ SG_ 1513 AAU_Geblaese "Ansteuergrad des Gebläses";
CM_ SG_ 1513 ION_Status_Taster "Status Kundenwunsch (Bedientaster) Ionisator";
CM_ SG_ 1295 KL_Kuehlenergie_instat_pred "Erwartete thermische Energie für den instationären Kühlbetrieb bis zum Übergang in den stationären Betrieb";
CM_ SG_ 1295 KL_Heizenergie_instat_pred "Erwartete thermische Energie für den instationären Heizbetrieb bis zum Übergang in den stationären Betrieb";
CM_ SG_ 1295 KL_PTC_ein "PTC Aus/Ein";
CM_ SG_ 1295 KL_Leistungspriorisierung "Priorisierungsvorgaben";
CM_ SG_ 1295 KL_Verdampfertemperatur "Istwert der Verdampfertemperatur";
CM_ SG_ 1295 KL_Heizbedarf "Bedarf an Heizmenge für Innenraumklimatisierung";
CM_ SG_ 1295 KL_Kuehlbedarf "Bedarf an Kühlmenge für Innenraumklimatisierung";
CM_ SG_ 1295 KL_Kuehlleistg_stat_erw "Erwartete thermische Kühlleistungsaufnahme für den stationären Klimabetrieb bei aktuellen klimatischen Bedingungen";
CM_ SG_ 1295 KL_Heizleistg_stat_erw "Erwartete thermische Heizleistungsaufnahme für den stationären Klimabetrieb bei aktuellen klimatischen Bedingungen";
CM_ SG_ 2589283474 KL_Temp_vor_Verdampfer "Ist Lufttemperatur vor Verdampfer";
CM_ SG_ 2589283474 KL_Eps_Innen "mittlerer Wert der Klima Regelabweichung";
CM_ SG_ 2589283474 KL_Tempklappe_Fond_li "Sollwert der Temperaturklappe Fond links";
CM_ SG_ 2589283474 KL_Tempklappe_Fond_re "Sollwert der Temperaturklappe Fond rechts";
CM_ SG_ 2463978659 KMP_Status_Spgfreiheit "Status der HV-Spannungsfreiheitserfassungsfunktion in der LE der KMP";
CM_ SG_ 2463978659 KMP_Warnung_Trockenlauf "Warnung Trockenlauf Kühlmittelpumpe";
CM_ SG_ 2463978659 KMP_Warnung_Uebertemperatur "Warnung Übertemperatur";
CM_ SG_ 2463978659 KMP_Ist_Spannung "Spannung HV am der Kühlmittelpumpe";
CM_ SG_ 2463978659 KMP_Fehler_Blockiert "Fehler Blockierter Rotor";
CM_ SG_ 2463978659 KMP_Fehler_elektrischer_Fehler "Fehler elektrischer Fehler Kühlmittelpumpe";
CM_ SG_ 2463978659 KMP_Fehler_Ueberspannung_HV "Fehler Überspannung HV";
CM_ SG_ 2463978659 KMP_Fehler_Ueberspannung_12V "Fehler Ueberspannung 12V";
CM_ SG_ 2463978659 KMP_Fehler_Uebertemperatur "Fehler Uebertemperatur der Kühlmittelpumpe im FCEV ZP4";
CM_ SG_ 2463978659 KMP_Fehler_Unterspannung_HV "Fehler Unterspannung HV";
CM_ SG_ 2463978659 KMP_Fehler_Unterspannung_12V "Fehler Unterspannung 12V";
CM_ SG_ 2463978659 KMP_Ist_Drehzahl "Ist- Drehzahl der Kühlmittelpumpe";
CM_ SG_ 2463978659 KMP_Error_NW_Timeout "Fehler CAN Kommunikation";
CM_ SG_ 2463978659 KMP_Ist_Strom "Ist- Stromaufnahme der Kühlmittelpumpe auf HV Leitung";
CM_ SG_ 2549088399 AWC_KompSchutz "Funktionseinschraenkung aufgrund Komponentenschutz aktiv";
CM_ SG_ 2549088399 AWC_Abschaltstufe "Funktionseinschraenkung aufgrund aktiver Abschaltstufe";
CM_ SG_ 2549088399 AWC_Transport_Mode "Funktionseinschränkung aufgrund aktivem Transport Mode und/ oder Transport Schutz";
CM_ SG_ 2549088399 AWC_Nachlauftyp "Abgebildet wird die von der Hardware vorgegebene Möglichkeit, die Kommunikation nach Klemme 15 = AUS aufrecht zu erhalten. Es wird ein Init-Wert gesendet.
0 = Kommunikation nur bei KL15=EIN (kein Nachlauf, nicht weckfähig)
1 = Kommunikation nach KL15=AU";
CM_ SG_ 2549088399 AWC_SNI "Das Signal beinhaltet den Source Node Identifier (Knotenadresse, die auch in der Abbildungsvorschrift zur CAN-ID für die NM-High Botschaft verwendet wird).";
CM_ SG_ 2549088399 KN_AWC_ECUKnockOutTimer "Ausgabe des ECUKnockOut-Timer in der Knotenbotschaft";
CM_ SG_ 2549088399 KN_AWC_BusKnockOut "Ausgabe des BusKnockOut-Status in der Knotenbotschaft";
CM_ SG_ 2549088399 KN_AWC_BusKnockOutTimer "Ausgabe des BusKnockOut-Timer in der Knotenbotschaft";
CM_ SG_ 2549088399 NM_AWC_Wakeup "enthält die Weckursache; stehen mehrere Weckursachen parallel an, dann muss der kleinste Wert übertragen werden";
CM_ SG_ 2549088399 KN_AWC_ECUKnockOut "Ausgabe des ECUKnockOut-Status in der Knotenbotschaft";
CM_ SG_ 2549088399 AWC_Lokalaktiv "Zeigt an ob das SG nach Klemme15 AUS und nach entsprechender MAX Aktivzeit noch aktiv war";
CM_ SG_ 2549088399 AWC_Subsystemaktiv "Zeigt an ob ein Subsystem des SGs nach Klemme15 AUS und nach entsprechender MAX Aktivzeit noch aktiv war";
CM_ SG_ 2549088399 AWC_KD_Fehler "Bei gesetztem Bit ist mindestens ein Kundendienstfehler eingetragen";
CM_ SG_ 2549088430 BattRegelung_KompSchutz "Funktionseinschränkung aufgrund Komponentenschutz aktiv";
CM_ SG_ 2549088430 BattRegelung_Abschaltstufe "Funktionseinschränkung aufgrund aktiver Abschaltstufe";
CM_ SG_ 2549088430 BattRegelung_Transport_Mode "Funktionseinschränkung aufgrund aktivem Transport Mode und/oder Transport Schutz";
CM_ SG_ 2549088430 BattRegelung_Nachlauftyp "Abgebildet wird die von der Hardware vorgegebene Möglichkeit, die Kommunikation nach Klemme 15 = AUS aufrecht zu erhalten. Es wird ein Init-Wert gesendet.
0 = Kommunikation nur bei KL15=EIN (kein Nachlauf, nicht weckfähig)
1 = Kommunikation nach KL15=AU";
CM_ SG_ 2549088430 BattRegelung_SNI "Das Signal beinhaltet den Source Node Identifier (Knotenadresse, die auch in der Abbildungsvorschrift zur CAN-ID für die NM-High Botschaft verwendet wird).";
CM_ SG_ 2549088430 NM_Battregelung_Wakeup "enthält die Weckursache; stehen mehrere Weckursachen parallel an, dann muss der kleinste Wert übertragen werden";
CM_ SG_ 2549088430 BMS_NV_Lokalaktiv "Zeigt an ob das SG nach Klemme15 AUS und nach entsprechender MAX Aktivzeit noch aktiv war. LAH.DUM.907.T.1_Abschaltungen Ruhestrommgm MLBevo";
CM_ SG_ 2549088430 BattRegelung_KD_Fehler "Bei gesetztem Bit ist mindestens ein Kundendienstfehler eingetragen";
CM_ SG_ 2549088412 BMS_MV_KompSchutz "Funktionseinschränkung aufgrund Komponentenschutz aktiv";
CM_ SG_ 2549088412 BMS_MV_Abschaltstufe "Funktionseinschränkung aufgrund aktiver Abschaltstufe";
CM_ SG_ 2549088412 BMS_MV_Transport_Mode "Funktionseinschränkung aufgrund aktivem Transport Mode und/oder Transport Schutz";
CM_ SG_ 2549088412 BMS_MV_Nachlauftyp "Abgebildet wird die von der Hardware vorgegebene Möglichkeit, die Kommunikation nach Klemme 15 = AUS aufrecht zu erhalten. Es wird ein Init-Wert gesendet.
0 = Kommunikation nur bei KL15=EIN (kein Nachlauf, nicht weckfähig)
1 = Kommunikation nach KL15=AU";
CM_ SG_ 2549088412 BMS_MV_SNI "Das Signal beinhaltet den Source Node Identifier (Knotenadresse, die auch in der Abbildungsvorschrift zur CAN-ID für die NM-High Botschaft verwendet wird).";
CM_ SG_ 2549088412 NM_BMS_MV_Wakeup "enthält die Weckursache; stehen mehrere Weckursachen parallel an, dann muss der kleinste Wert übertragen werden";
CM_ SG_ 2549088412 BMS_MV_Lokalaktiv "Zeigt an ob das SG nach Klemme15 AUS und nach entsprechender MAX Aktivzeit noch aktiv war";
CM_ SG_ 2549088412 BMS_MV_Subsystemaktiv "Zeigt an ob ein Subsystem des SGs nach Klemme15 AUS und nach entsprechender MAX Aktivzeit noch aktiv war";
CM_ SG_ 2549088412 BMS_MV_KD_Fehler "Bei gesetztem Bit ist mindestens ein Kundendienstfehler eingetragen";
CM_ SG_ 2549088321 DCDC_KompSchutz "Funktionseinschränkung aufgrund Komponentenschutz aktiv";
CM_ SG_ 2549088321 DCDC_Abschaltstufe "Funktionseinschränkung aufgrund aktiver Abschaltstufe";
CM_ SG_ 2549088321 DCDC_Transport_Mode "Funktionseinschränkung aufgrund aktivem Transport Mode und/oder Transport Schutz";
CM_ SG_ 2549088321 DCDC_Nachlauftyp "Abgebildet wird die von der Hardware vorgegebene Möglichkeit, die Kommunikation nach Klemme 15 = AUS aufrecht zu erhalten. Es wird ein Init-Wert gesendet.
0 = Kommunikation nur bei KL15=EIN (kein Nachlauf, nicht weckfähig)
1 = Kommunikation nach KL15=AU";
CM_ SG_ 2549088321 DCDC_SNI "Das Signal beinhaltet den Source Node Identifier (Knotenadresse, die auch in der Abbildungsvorschrift zur CAN-ID für die NM-High Botschaft verwendet wird).";
CM_ SG_ 2549088321 KN_DCDC_BusKnockOutTimer "Ausgabe des BusKnockOut-Timer in der Knotenbotschaft";
CM_ SG_ 2549088321 NM_DCDC_Wakeup "enthält die Weckursache; stehen mehrere Weckursachen parallel an, dann muss der kleinste Wert übertragen werden";
CM_ SG_ 2549088321 NMH_DCDC_Lokalaktiv "Zeigt an ob Steuergerät lokal aktiv war";
CM_ SG_ 2549088321 NMH_DCDC_Subsystemaktiv "Zeigt an ob ein Subsystem des SGs nach Klemme15 AUS und nach entsprechender MAX Aktivzeit noch aktiv war";
CM_ SG_ 2549088321 DCDC_KD_Fehler "Bei gesetztem Bit ist mindestens ein Kundendienstfehler eingetragen";
CM_ SG_ 2549088439 DCDC_HV_KompSchutz "Funktionseinschraenkung aufgrund Komponentenschutz aktiv";
CM_ SG_ 2549088439 DCDC_HV_Abschaltstufe "Funktionseinschraenkung aufgrund aktiver Abschaltstufe";
CM_ SG_ 2549088439 DCDC_HV_Transport_Mode "Funktionseinschraenkung aufgrund aktivem Transport Mode und/oder Transport Schutz";
CM_ SG_ 2549088439 DCDC_HV_Nachlauftyp "Abgebildet wird die von der Hardware vorgegebene Moeglichkeit, die Kommunikation nach Klemme 15 = AUS aufrecht zu erhalten. Es wird ein Init-Wert gesendet.
0 = Kommunikation nur bei KL15=EIN (kein Nachlauf, nicht weckfähig)
1 = Kommunikation nach KL15=A";
CM_ SG_ 2549088439 DCDC_HV_SNI "Source Node-Identifier (SNI) identifiziert den Sender der NM-Botschaft (Knotenadresse) eindeutig im Fahrzeug";
CM_ SG_ 2549088439 DCDC_HV_ECUKnockOutTimer "Ausgabe des ECUKnockOut-Timer in der Knotenbotschaft";
CM_ SG_ 2549088439 DCDC_HV_BusKnockOut "Ausgabe des BusKnockout-Status in der Knotenbotschaft";
CM_ SG_ 2549088439 DCDC_HV_BusKnockOutTimer "Ausgabe des BusKnockOut-Timer in der Knotenbotschaft";
CM_ SG_ 2549088439 NM_DCDC_HV_Wakeup "enthaelt die Weckursache; stehen mehrere Weckursachen parallel an, dann muss der kleinste Wert übertragen werden";
CM_ SG_ 2549088439 DCDC_HV_ECUKnockOut "Ausgabe des ECUKnockout-Status in der Knotenbotschaft";
CM_ SG_ 2549088439 DCDC_HV_Lokalaktiv "Zeigt an ob das SG nach Klemme15 AUS und nach entsprechender MAX Aktivzeit noch aktiv war.";
CM_ SG_ 2549088439 DCDC_HV_KD_Fehler "Bei gesetztem Bit ist mindestens ein Kundendienstfehler eingetragen";
CM_ SG_ 2549088455 DCDC_HV_02_KompSchutz "Funktionseinschränkung aufgrund Komponentenschutz aktiv";
CM_ SG_ 2549088455 DCDC_HV_02_Abschaltstufe "Funktionseinschränkung aufgrund aktiver Abschaltstufe";
CM_ SG_ 2549088455 DCDC_HV_02_Transport_Mode "Funktionseinschränkung aufgrund aktivem Transport Mode und/oder Transport Schutz";
CM_ SG_ 2549088455 DCDC_HV_02_Nachlauftyp "Abgebildet wird die von der Hardware vorgegebene Möglichkeit, die Kommunikation nach Klemme 15 = AUS aufrecht zu erhalten. Es wird ein Init-Wert gesendet.
0 = Kommunikation nur bei KL15=EIN (kein Nachlauf, nicht weckfähig)
1 = Kommunikation nach KL15=AU";
CM_ SG_ 2549088455 DCDC_HV_02_SNI "Source Node-Identifier (SNI) identifiziert den Sender der NM-Botschaft (Knotenadresse) eindeutig im Fahrzeug";
CM_ SG_ 2549088455 KN_DCDC_HV_02_ECUKnockOutTimer "Ausgabe des ECUKnockOut-Timer in der Knotenbotschaft";
CM_ SG_ 2549088455 KN_DCDC_HV_02_BusKnockOut "Ausgabe des BusKnockout-Status in der Knotenbotschaft";
CM_ SG_ 2549088455 KN_DCDC_HV_02_BusKnockOutTimer "Ausgabe des BusKnockOut-Timer in der Knotenbotschaft";
CM_ SG_ 2549088455 NM_DCDC_HV_02_Wakeup "enthält die Weckursache; stehen mehrere Weckursachen parallel an, dann muss der kleinste Wert übertragen werden";
CM_ SG_ 2549088455 KN_DCDC_HV_02_ECUKnockOut "Ausgabe des ECUKnockout-Status in der Knotenbotschaft";
CM_ SG_ 2549088455 NM_DCDC_HV_02_Lokalaktiv "Zeigt an ob das SG nach Klemme15 AUS und nach entsprechender MAX Aktivzeit noch aktiv war.";
CM_ SG_ 2549088455 DCDC_HV_02_KD_Fehler "Bei gesetztem Bit ist mindestens ein Kundendienstfehler eingetragen";
BA_DEF_ BO_  "DiagRequest" ENUM  "No","Yes";
BA_DEF_ BO_  "DiagResponse" ENUM  "No","Yes";
BA_DEF_ BO_  "DiagState" ENUM  "No","Yes";
BA_DEF_ BO_  "GenMsgChkConstant" HEX 0 4095;
BA_DEF_ BO_  "GenMsgCycleTime" INT 0 65535;
BA_DEF_ BO_  "GenMsgCycleTimeFast" INT 0 65535;
BA_DEF_ BO_  "GenMsgDelayTime" INT 0 100000;
BA_DEF_ BO_  "GenMsgILSupport" ENUM  "No","Yes";
BA_DEF_ BO_  "GenMsgNrOfRepetition" INT 0 100;
BA_DEF_ BO_  "GenMsgPDUConstants" STRING ;
BA_DEF_ BO_  "GenMsgSendType" ENUM  "Cyclic","not_used","not_used","not_used","not_used","not_used","not_used","IfActive","NoMsgSendType";
BA_DEF_ BO_  "GenMsgStartDelayTime" INT 0 100000;
BA_DEF_ BO_  "NmMessage" ENUM  "No","Yes";
BA_DEF_ BO_  "NmhMessage" ENUM  "No","Yes";
BA_DEF_ BO_  "MsgType" ENUM  "Application","NM ","NMH","TP2.0","ISO-TP ","BAP","EID","KS","XCP_PRE_CONFIGURED","XCP_RUNTIME_CONFIGURED";
BA_DEF_ BO_  "VAGTP20_API" HEX 0 255;
BA_DEF_ BO_  "VAGTP20_DynConnection" ENUM  "No","Yes";
BA_DEF_ BO_  "VAGTP20_DynSetup" ENUM  "No","Yes";
BA_DEF_ BO_  "VAGTP20_StatConnection" ENUM  "No","Yes";
BA_DEF_ SG_  "GenSigActiveRepetitions" INT -2147483648 2147483647;
BA_DEF_ SG_  "GenSigInactiveValue" INT -2147483648 2147483647;
BA_DEF_ SG_  "GenSigSendType" ENUM  "Cyclic","OnWrite","OnWriteWithRepetition","OnChange","OnChangeWithRepetition","IfActive","IfActiveWithRepetition","NoSigSendType","OnChangeAndIfActive","OnChangeAndIfActiveWithRepetition";
BA_DEF_ SG_  "GenSigStartValue" INT -2147483648 2147483647;
BA_DEF_ SG_  "NWM-WakeupAllowed" ENUM  "No","Yes";
BA_DEF_ SG_  "GenSigFuncType" ENUM  "NoFunction","MsgCounter","CRC-8","XOR","XOR-2","DatedBit","SW-Kl15","CHK","Constant","Protocol","CRC-8-SAE_J1850","CRC-32","DataLength","DataID","MsgCounter16","SOK-Signatur","Cluster";
BA_DEF_ SG_  "GenSigSwitchedByIgnition" ENUM  "No","Yes";
BA_DEF_ SG_  "Fehlerwert" HEX 0 2147483647;
BA_DEF_ SG_  "GenSigMissingSourceValue" HEX 0 2147483647;
BA_DEF_REL_ BU_SG_REL_  "GenSigTimeoutTime" INT 0 65535;
BA_DEF_DEF_REL_ "GenSigTimeoutTime" 0;
BA_DEF_DEF_  "DiagRequest" "No";
BA_DEF_DEF_  "DiagResponse" "No";
BA_DEF_DEF_  "DiagState" "No";
BA_DEF_DEF_  "GenMsgChkConstant" 0;
BA_DEF_DEF_  "GenMsgCycleTime" 0;
BA_DEF_DEF_  "GenMsgCycleTimeFast" 0;
BA_DEF_DEF_  "GenMsgDelayTime" 0;
BA_DEF_DEF_  "GenMsgILSupport" "No";
BA_DEF_DEF_  "GenMsgNrOfRepetition" 0;
BA_DEF_DEF_  "GenMsgPDUConstants" "";
BA_DEF_DEF_  "GenMsgSendType" "NoMsgSendType";
BA_DEF_DEF_  "GenMsgStartDelayTime" 0;
BA_DEF_DEF_  "NmMessage" "No";
BA_DEF_DEF_  "NmhMessage" "No";
BA_DEF_DEF_  "MsgType" "Application";
BA_DEF_DEF_  "VAGTP20_API" 0;
BA_DEF_DEF_  "VAGTP20_DynConnection" "No";
BA_DEF_DEF_  "VAGTP20_DynSetup" "No";
BA_DEF_DEF_  "VAGTP20_StatConnection" "No";
BA_DEF_DEF_  "GenSigActiveRepetitions" 0;
BA_DEF_DEF_  "GenSigInactiveValue" 0;
BA_DEF_DEF_  "GenSigSendType" "NoSigSendType";
BA_DEF_DEF_  "GenSigStartValue" 0;
BA_DEF_DEF_  "NWM-WakeupAllowed" "No";
BA_DEF_DEF_  "GenSigFuncType" "NoFunction";
BA_DEF_DEF_  "GenSigSwitchedByIgnition" "Yes";
BA_DEF_DEF_  "Fehlerwert" 0;
BA_DEF_DEF_  "GenSigMissingSourceValue" 0;
BA_ "GenMsgSendType" BO_ 2463978610 0;
BA_ "GenMsgILSupport" BO_ 2463978610 1;
BA_ "GenMsgDelayTime" BO_ 2463978610 10;
BA_ "GenMsgCycleTime" BO_ 2463978610 500;
BA_ "GenMsgSendType" BO_ 2463978641 0;
BA_ "GenMsgPDUConstants" BO_ 2463978641 "0xb1,0x44,0x37,0xca,0xb5,0xd6,0x0e,0xa3,0x3b,0x16,0xa6,0x1a,0x23,0x1d,0x91,0x9c";
BA_ "GenMsgILSupport" BO_ 2463978641 1;
BA_ "GenMsgCycleTime" BO_ 2463978641 100;
BA_ "GenMsgSendType" BO_ 2589283661 0;
BA_ "GenMsgILSupport" BO_ 2589283661 1;
BA_ "GenMsgDelayTime" BO_ 2589283661 100;
BA_ "GenMsgCycleTime" BO_ 2589283661 1000;
BA_ "MsgType" BO_ 1857 4;
BA_ "DiagRequest" BO_ 1857 1;
BA_ "MsgType" BO_ 1963 4;
BA_ "DiagResponse" BO_ 1963 1;
BA_ "MsgType" BO_ 1795 4;
BA_ "DiagState" BO_ 1795 1;
BA_ "MsgType" BO_ 1792 4;
BA_ "DiagState" BO_ 1792 1;
BA_ "MsgType" BO_ 2015 4;
BA_ "DiagState" BO_ 2015 1;
BA_ "MsgType" BO_ 1860 4;
BA_ "DiagRequest" BO_ 1860 1;
BA_ "MsgType" BO_ 1966 4;
BA_ "DiagResponse" BO_ 1966 1;
BA_ "MsgType" BO_ 2021 4;
BA_ "DiagRequest" BO_ 2021 1;
BA_ "MsgType" BO_ 2029 4;
BA_ "DiagResponse" BO_ 2029 1;
BA_ "MsgType" BO_ 2023 4;
BA_ "DiagRequest" BO_ 2023 1;
BA_ "MsgType" BO_ 2031 4;
BA_ "DiagResponse" BO_ 2031 1;
BA_ "MsgType" BO_ 2549350937 4;
BA_ "MsgType" BO_ 2549487874 4;
BA_ "MsgType" BO_ 2549356802 4;
BA_ "MsgType" BO_ 2549482009 4;
BA_ "MsgType" BO_ 1865 4;
BA_ "DiagRequest" BO_ 1865 1;
BA_ "MsgType" BO_ 1971 4;
BA_ "DiagResponse" BO_ 1971 1;
BA_ "MsgType" BO_ 1858 4;
BA_ "DiagRequest" BO_ 1858 1;
BA_ "MsgType" BO_ 1964 4;
BA_ "DiagResponse" BO_ 1964 1;
BA_ "MsgType" BO_ 2549874831 4;
BA_ "DiagRequest" BO_ 2549874831 1;
BA_ "MsgType" BO_ 2550005903 4;
BA_ "DiagResponse" BO_ 2550005903 1;
BA_ "MsgType" BO_ 2549874862 4;
BA_ "DiagRequest" BO_ 2549874862 1;
BA_ "MsgType" BO_ 2550005934 4;
BA_ "DiagResponse" BO_ 2550005934 1;
BA_ "MsgType" BO_ 2549874844 4;
BA_ "DiagRequest" BO_ 2549874844 1;
BA_ "MsgType" BO_ 2550005916 4;
BA_ "DiagResponse" BO_ 2550005916 1;
BA_ "MsgType" BO_ 2549874887 4;
BA_ "DiagRequest" BO_ 2549874887 1;
BA_ "MsgType" BO_ 2550005959 4;
BA_ "DiagResponse" BO_ 2550005959 1;
BA_ "MsgType" BO_ 2549874895 4;
BA_ "DiagRequest" BO_ 2549874895 1;
BA_ "MsgType" BO_ 2550005967 4;
BA_ "DiagResponse" BO_ 2550005967 1;
BA_ "MsgType" BO_ 2549874871 4;
BA_ "DiagRequest" BO_ 2549874871 1;
BA_ "MsgType" BO_ 2550005943 4;
BA_ "DiagResponse" BO_ 2550005943 1;
BA_ "MsgType" BO_ 2549874869 4;
BA_ "DiagRequest" BO_ 2549874869 1;
BA_ "MsgType" BO_ 2550005941 4;
BA_ "DiagResponse" BO_ 2550005941 1;
BA_ "MsgType" BO_ 2549874811 4;
BA_ "DiagRequest" BO_ 2549874811 1;
BA_ "MsgType" BO_ 2550005883 4;
BA_ "DiagResponse" BO_ 2550005883 1;
BA_ "MsgType" BO_ 2549874886 4;
BA_ "DiagRequest" BO_ 2549874886 1;
BA_ "MsgType" BO_ 2550005958 4;
BA_ "DiagResponse" BO_ 2550005958 1;
BA_ "MsgType" BO_ 2549874868 4;
BA_ "DiagRequest" BO_ 2549874868 1;
BA_ "MsgType" BO_ 2550005940 4;
BA_ "DiagResponse" BO_ 2550005940 1;
BA_ "GenMsgSendType" BO_ 497 0;
BA_ "GenMsgNrOfRepetition" BO_ 497 7;
BA_ "GenMsgILSupport" BO_ 497 1;
BA_ "GenMsgDelayTime" BO_ 497 20;
BA_ "GenMsgCycleTimeFast" BO_ 497 40;
BA_ "GenMsgCycleTime" BO_ 497 500;
BA_ "GenMsgSendType" BO_ 960 0;
BA_ "GenMsgPDUConstants" BO_ 960 "0xc3,0xc3,0xc3,0xc3,0xc3,0xc3,0xc3,0xc3,0xc3,0xc3,0xc3,0xc3,0xc3,0xc3,0xc3,0xc3";
BA_ "GenMsgILSupport" BO_ 960 1;
BA_ "GenMsgDelayTime" BO_ 960 10;
BA_ "GenMsgCycleTime" BO_ 960 100;
BA_ "GenMsgChkConstant" BO_ 960 195;
BA_ "GenMsgSendType" BO_ 1646 0;
BA_ "GenMsgILSupport" BO_ 1646 1;
BA_ "GenMsgDelayTime" BO_ 1646 200;
BA_ "GenMsgCycleTime" BO_ 1646 2000;
BA_ "GenMsgSendType" BO_ 1649 0;
BA_ "GenMsgILSupport" BO_ 1649 1;
BA_ "GenMsgDelayTime" BO_ 1649 200;
BA_ "GenMsgCycleTime" BO_ 1649 2000;
BA_ "GenMsgSendType" BO_ 949 0;
BA_ "GenMsgILSupport" BO_ 949 1;
BA_ "GenMsgCycleTime" BO_ 949 100;
BA_ "GenMsgSendType" BO_ 1640 0;
BA_ "GenMsgNrOfRepetition" BO_ 1640 5;
BA_ "GenMsgILSupport" BO_ 1640 1;
BA_ "GenMsgDelayTime" BO_ 1640 25;
BA_ "GenMsgCycleTimeFast" BO_ 1640 100;
BA_ "GenMsgCycleTime" BO_ 1640 200;
BA_ "GenMsgSendType" BO_ 1441 0;
BA_ "GenMsgILSupport" BO_ 1441 1;
BA_ "GenMsgCycleTime" BO_ 1441 500;
BA_ "GenMsgSendType" BO_ 2589283469 0;
BA_ "GenMsgILSupport" BO_ 2589283469 1;
BA_ "GenMsgDelayTime" BO_ 2589283469 100;
BA_ "GenMsgCycleTime" BO_ 2589283469 1000;
BA_ "GenMsgSendType" BO_ 2589283621 0;
BA_ "GenMsgILSupport" BO_ 2589283621 1;
BA_ "GenMsgDelayTime" BO_ 2589283621 100;
BA_ "GenMsgCycleTime" BO_ 2589283621 1000;
BA_ "GenMsgSendType" BO_ 2463978701 0;
BA_ "GenMsgILSupport" BO_ 2463978701 1;
BA_ "GenMsgCycleTime" BO_ 2463978701 100;
BA_ "GenMsgSendType" BO_ 1712 0;
BA_ "GenMsgILSupport" BO_ 1712 1;
BA_ "GenMsgCycleTime" BO_ 1712 500;
BA_ "GenMsgSendType" BO_ 1505 0;
BA_ "GenMsgILSupport" BO_ 1505 1;
BA_ "GenMsgCycleTime" BO_ 1505 200;
BA_ "GenMsgSendType" BO_ 1717 0;
BA_ "GenMsgILSupport" BO_ 1717 1;
BA_ "GenMsgCycleTime" BO_ 1717 500;
BA_ "GenMsgSendType" BO_ 1513 0;
BA_ "GenMsgILSupport" BO_ 1513 1;
BA_ "GenMsgCycleTime" BO_ 1513 200;
BA_ "GenMsgSendType" BO_ 1295 0;
BA_ "GenMsgILSupport" BO_ 1295 1;
BA_ "GenMsgCycleTime" BO_ 1295 100;
BA_ "GenMsgSendType" BO_ 2589283474 0;
BA_ "GenMsgILSupport" BO_ 2589283474 1;
BA_ "GenMsgDelayTime" BO_ 2589283474 100;
BA_ "GenMsgCycleTime" BO_ 2589283474 1000;
BA_ "GenMsgSendType" BO_ 2463978659 0;
BA_ "GenMsgILSupport" BO_ 2463978659 1;
BA_ "GenMsgDelayTime" BO_ 2463978659 10;
BA_ "GenMsgCycleTime" BO_ 2463978659 100;
BA_ "GenMsgSendType" BO_ 2549088399 0;
BA_ "GenMsgILSupport" BO_ 2549088399 1;
BA_ "GenMsgCycleTime" BO_ 2549088399 500;
BA_ "GenMsgSendType" BO_ 2549088430 0;
BA_ "GenMsgILSupport" BO_ 2549088430 1;
BA_ "GenMsgCycleTime" BO_ 2549088430 500;
BA_ "GenMsgSendType" BO_ 2549088412 0;
BA_ "GenMsgILSupport" BO_ 2549088412 1;
BA_ "GenMsgCycleTime" BO_ 2549088412 500;
BA_ "GenMsgSendType" BO_ 2549088321 0;
BA_ "GenMsgILSupport" BO_ 2549088321 1;
BA_ "GenMsgCycleTime" BO_ 2549088321 500;
BA_ "GenMsgSendType" BO_ 2549088439 0;
BA_ "GenMsgILSupport" BO_ 2549088439 1;
BA_ "GenMsgCycleTime" BO_ 2549088439 500;
BA_ "GenMsgSendType" BO_ 2549088455 0;
BA_ "GenMsgILSupport" BO_ 2549088455 1;
BA_ "GenMsgCycleTime" BO_ 2549088455 500;
BA_ "GenSigSwitchedByIgnition" SG_ 2463978610 HVLM_RtmWarnLadeverbindung 0;
BA_ "GenSigSendType" SG_ 2463978610 HVLM_RtmWarnLadeverbindung 3;
BA_ "GenSigSwitchedByIgnition" SG_ 2463978610 HVLM_RtmWarnLadesystem 0;
BA_ "GenSigSendType" SG_ 2463978610 HVLM_RtmWarnLadesystem 3;
BA_ "GenSigSwitchedByIgnition" SG_ 2463978610 HVLM_RtmWarnLadestatus 0;
BA_ "GenSigSendType" SG_ 2463978610 HVLM_RtmWarnLadestatus 3;
BA_ "GenSigSwitchedByIgnition" SG_ 2463978610 HVLM_RtmWarnLadeKommunikation 0;
BA_ "GenSigSendType" SG_ 2463978610 HVLM_RtmWarnLadeKommunikation 3;
BA_ "GenSigSwitchedByIgnition" SG_ 2463978610 HVLM_Ladeanzeige_Anf 0;
BA_ "GenSigSendType" SG_ 2463978610 HVLM_Ladeanzeige_Anf 3;
BA_ "GenSigSwitchedByIgnition" SG_ 2463978610 HVLM_Ladeanzeige_Status 0;
BA_ "GenSigSendType" SG_ 2463978610 HVLM_Ladeanzeige_Status 3;
BA_ "GenSigSendType" SG_ 2463978610 HVLM_Ladeanzeige_Rampzeit 3;
BA_ "Fehlerwert" SG_ 2463978610 HVLM_Ladeanzeige_Intens_Heck 127;
BA_ "GenSigStartValue" SG_ 2463978610 HVLM_Ladeanzeige_Intens_Heck 126;
BA_ "GenSigSendType" SG_ 2463978610 HVLM_Ladeanzeige_Intens_Heck 3;
BA_ "Fehlerwert" SG_ 2463978610 HVLM_Ladeanzeige_Intens_Front 127;
BA_ "GenSigStartValue" SG_ 2463978610 HVLM_Ladeanzeige_Intens_Front 126;
BA_ "GenSigSendType" SG_ 2463978610 HVLM_Ladeanzeige_Intens_Front 3;
BA_ "GenSigSwitchedByIgnition" SG_ 2463978641 HVLM_11_CRC 0;
BA_ "GenSigFuncType" SG_ 2463978641 HVLM_11_CRC 2;
BA_ "GenSigSendType" SG_ 2463978641 HVLM_11_CRC 0;
BA_ "GenSigSwitchedByIgnition" SG_ 2463978641 HVLM_11_BZ 0;
BA_ "GenSigFuncType" SG_ 2463978641 HVLM_11_BZ 1;
BA_ "GenSigSendType" SG_ 2463978641 HVLM_11_BZ 0;
BA_ "Fehlerwert" SG_ 2463978641 HVLM_HVLB_SollSpannung_HVLS 4095;
BA_ "GenSigSwitchedByIgnition" SG_ 2463978641 HVLM_HVLB_SollSpannung_HVLS 0;
BA_ "GenSigStartValue" SG_ 2463978641 HVLM_HVLB_SollSpannung_HVLS 4094;
BA_ "GenSigSendType" SG_ 2463978641 HVLM_HVLB_SollSpannung_HVLS 0;
BA_ "GenSigSwitchedByIgnition" SG_ 2463978641 HVLM_HVLB_Status 0;
BA_ "GenSigSendType" SG_ 2463978641 HVLM_HVLB_Status 0;
BA_ "GenSigSwitchedByIgnition" SG_ 2463978641 HVLM_HVLB_SollModus 0;
BA_ "GenSigStartValue" SG_ 2463978641 HVLM_HVLB_SollModus 7;
BA_ "GenSigSendType" SG_ 2463978641 HVLM_HVLB_SollModus 0;
BA_ "Fehlerwert" SG_ 2589283661 HVLM_PlanAnfr_Leistung 4095;
BA_ "GenSigSwitchedByIgnition" SG_ 2589283661 HVLM_PlanAnfr_Leistung 0;
BA_ "GenSigStartValue" SG_ 2589283661 HVLM_PlanAnfr_Leistung 4094;
BA_ "GenSigSendType" SG_ 2589283661 HVLM_PlanAnfr_Leistung 0;
BA_ "Fehlerwert" SG_ 2589283661 HVLM_PlanAnfr_Zaehler 15;
BA_ "GenSigSwitchedByIgnition" SG_ 2589283661 HVLM_PlanAnfr_Zaehler 0;
BA_ "GenSigStartValue" SG_ 2589283661 HVLM_PlanAnfr_Zaehler 14;
BA_ "GenSigSendType" SG_ 2589283661 HVLM_PlanAnfr_Zaehler 3;
BA_ "Fehlerwert" SG_ 2589283661 HVLM_PlanAnfr_Dauer 1023;
BA_ "GenSigSwitchedByIgnition" SG_ 2589283661 HVLM_PlanAnfr_Dauer 0;
BA_ "GenSigStartValue" SG_ 2589283661 HVLM_PlanAnfr_Dauer 1022;
BA_ "GenSigSendType" SG_ 2589283661 HVLM_PlanAnfr_Dauer 0;
BA_ "Fehlerwert" SG_ 2589283661 HVLM_PlanAnfr_Ladeart 7;
BA_ "GenSigSwitchedByIgnition" SG_ 2589283661 HVLM_PlanAnfr_Ladeart 0;
BA_ "GenSigStartValue" SG_ 2589283661 HVLM_PlanAnfr_Ladeart 6;
BA_ "GenSigSendType" SG_ 2589283661 HVLM_PlanAnfr_Ladeart 0;
BA_ "Fehlerwert" SG_ 2589283661 HVLM_EnergieAnfr_SocStart 127;
BA_ "GenSigSwitchedByIgnition" SG_ 2589283661 HVLM_EnergieAnfr_SocStart 0;
BA_ "GenSigStartValue" SG_ 2589283661 HVLM_EnergieAnfr_SocStart 126;
BA_ "GenSigSendType" SG_ 2589283661 HVLM_EnergieAnfr_SocStart 0;
BA_ "Fehlerwert" SG_ 2589283661 HVLM_EnergieAnfr_SocZiel 127;
BA_ "GenSigSwitchedByIgnition" SG_ 2589283661 HVLM_EnergieAnfr_SocZiel 0;
BA_ "GenSigStartValue" SG_ 2589283661 HVLM_EnergieAnfr_SocZiel 126;
BA_ "GenSigSendType" SG_ 2589283661 HVLM_EnergieAnfr_SocZiel 0;
BA_ "Fehlerwert" SG_ 2589283661 HVLM_EnergieAnfr_Zaehler 15;
BA_ "GenSigSwitchedByIgnition" SG_ 2589283661 HVLM_EnergieAnfr_Zaehler 0;
BA_ "GenSigStartValue" SG_ 2589283661 HVLM_EnergieAnfr_Zaehler 14;
BA_ "GenSigSendType" SG_ 2589283661 HVLM_EnergieAnfr_Zaehler 3;
BA_ "Fehlerwert" SG_ 2589283661 HVLM_LadegrenzeAnfr_Leistung 4095;
BA_ "GenSigSwitchedByIgnition" SG_ 2589283661 HVLM_LadegrenzeAnfr_Leistung 0;
BA_ "GenSigStartValue" SG_ 2589283661 HVLM_LadegrenzeAnfr_Leistung 4094;
BA_ "GenSigSendType" SG_ 2589283661 HVLM_LadegrenzeAnfr_Leistung 0;
BA_ "Fehlerwert" SG_ 2589283661 HVLM_LadegrenzeAnfr_Zaehler 15;
BA_ "GenSigSwitchedByIgnition" SG_ 2589283661 HVLM_LadegrenzeAnfr_Zaehler 0;
BA_ "GenSigStartValue" SG_ 2589283661 HVLM_LadegrenzeAnfr_Zaehler 14;
BA_ "GenSigSendType" SG_ 2589283661 HVLM_LadegrenzeAnfr_Zaehler 3;
BA_ "GenSigSwitchedByIgnition" SG_ 1857 ISO_DCDC_Req_Data 0;
BA_ "GenSigSendType" SG_ 1857 ISO_DCDC_Req_Data 3;
BA_ "GenSigSwitchedByIgnition" SG_ 1963 ISO_DCDC_Resp_Data 0;
BA_ "GenSigSendType" SG_ 1963 ISO_DCDC_Resp_Data 3;
BA_ "GenSigSwitchedByIgnition" SG_ 1795 ISO_Funktionaler_Req_Abgas 0;
BA_ "GenSigFuncType" SG_ 1795 ISO_Funktionaler_Req_Abgas 9;
BA_ "GenSigSendType" SG_ 1795 ISO_Funktionaler_Req_Abgas 3;
BA_ "GenSigSwitchedByIgnition" SG_ 1792 ISO_ALL_01_Req_Data 0;
BA_ "GenSigFuncType" SG_ 1792 ISO_ALL_01_Req_Data 9;
BA_ "GenSigSendType" SG_ 1792 ISO_ALL_01_Req_Data 3;
BA_ "GenSigSwitchedByIgnition" SG_ 2015 ISO_OBD_Funktionaler_Req_Data 0;
BA_ "GenSigFuncType" SG_ 2015 ISO_OBD_Funktionaler_Req_Data 9;
BA_ "GenSigSendType" SG_ 2015 ISO_OBD_Funktionaler_Req_Data 3;
BA_ "GenSigSwitchedByIgnition" SG_ 1860 ISO_Ladegeraet_Req_Data 0;
BA_ "GenSigFuncType" SG_ 1860 ISO_Ladegeraet_Req_Data 9;
BA_ "GenSigSendType" SG_ 1860 ISO_Ladegeraet_Req_Data 3;
BA_ "GenSigSwitchedByIgnition" SG_ 1966 ISO_Ladegeraet_Resp_Data 0;
BA_ "GenSigFuncType" SG_ 1966 ISO_Ladegeraet_Resp_Data 9;
BA_ "GenSigSendType" SG_ 1966 ISO_Ladegeraet_Resp_Data 3;
BA_ "GenSigSwitchedByIgnition" SG_ 2021 ISO_OBD_04_Req_Data 0;
BA_ "GenSigFuncType" SG_ 2021 ISO_OBD_04_Req_Data 9;
BA_ "GenSigSendType" SG_ 2021 ISO_OBD_04_Req_Data 3;
BA_ "GenSigSwitchedByIgnition" SG_ 2029 ISO_OBD_04_Resp_Data 0;
BA_ "GenSigFuncType" SG_ 2029 ISO_OBD_04_Resp_Data 9;
BA_ "GenSigSendType" SG_ 2029 ISO_OBD_04_Resp_Data 3;
BA_ "GenSigSwitchedByIgnition" SG_ 2023 ISO_OBD_06_Req_Data 0;
BA_ "GenSigFuncType" SG_ 2023 ISO_OBD_06_Req_Data 9;
BA_ "GenSigSendType" SG_ 2023 ISO_OBD_06_Req_Data 3;
BA_ "GenSigSwitchedByIgnition" SG_ 2031 ISO_OBD_06_Resp_Data 0;
BA_ "GenSigFuncType" SG_ 2031 ISO_OBD_06_Resp_Data 9;
BA_ "GenSigSendType" SG_ 2031 ISO_OBD_06_Resp_Data 3;
BA_ "GenSigSwitchedByIgnition" SG_ 2549350937 ISO_OBDC_RTM_Req_Data 0;
BA_ "GenSigFuncType" SG_ 2549350937 ISO_OBDC_RTM_Req_Data 9;
BA_ "GenSigSendType" SG_ 2549350937 ISO_OBDC_RTM_Req_Data 3;
BA_ "GenSigSwitchedByIgnition" SG_ 2549487874 ISO_OBDC_RTM_Resp_Data 0;
BA_ "GenSigFuncType" SG_ 2549487874 ISO_OBDC_RTM_Resp_Data 9;
BA_ "GenSigSendType" SG_ 2549487874 ISO_OBDC_RTM_Resp_Data 3;
BA_ "GenSigSwitchedByIgnition" SG_ 2549356802 ISO_RTM_OBDC_Req_Data 0;
BA_ "GenSigFuncType" SG_ 2549356802 ISO_RTM_OBDC_Req_Data 9;
BA_ "GenSigSendType" SG_ 2549356802 ISO_RTM_OBDC_Req_Data 3;
BA_ "GenSigSwitchedByIgnition" SG_ 2549482009 ISO_RTM_OBDC_Resp_Data 0;
BA_ "GenSigFuncType" SG_ 2549482009 ISO_RTM_OBDC_Resp_Data 9;
BA_ "GenSigSendType" SG_ 2549482009 ISO_RTM_OBDC_Resp_Data 3;
BA_ "GenSigSwitchedByIgnition" SG_ 1865 ISO_Sub_Gateway_Req_Data 0;
BA_ "GenSigFuncType" SG_ 1865 ISO_Sub_Gateway_Req_Data 9;
BA_ "GenSigSendType" SG_ 1865 ISO_Sub_Gateway_Req_Data 3;
BA_ "GenSigSwitchedByIgnition" SG_ 1971 ISO_Sub_Gateway_Resp_Data 0;
BA_ "GenSigFuncType" SG_ 1971 ISO_Sub_Gateway_Resp_Data 9;
BA_ "GenSigSendType" SG_ 1971 ISO_Sub_Gateway_Resp_Data 3;
BA_ "GenSigSwitchedByIgnition" SG_ 1858 ISO_TME_Req_Data 0;
BA_ "GenSigSendType" SG_ 1858 ISO_TME_Req_Data 3;
BA_ "GenSigSwitchedByIgnition" SG_ 1964 ISO_TME_Resp_Data 0;
BA_ "GenSigSendType" SG_ 1964 ISO_TME_Resp_Data 3;
BA_ "GenSigSwitchedByIgnition" SG_ 2549874831 ISO_AWC_Req_Data 0;
BA_ "GenSigFuncType" SG_ 2549874831 ISO_AWC_Req_Data 9;
BA_ "GenSigSendType" SG_ 2549874831 ISO_AWC_Req_Data 3;
BA_ "GenSigSwitchedByIgnition" SG_ 2550005903 ISO_AWC_Resp_Data 0;
BA_ "GenSigFuncType" SG_ 2550005903 ISO_AWC_Resp_Data 9;
BA_ "GenSigSendType" SG_ 2550005903 ISO_AWC_Resp_Data 3;
BA_ "GenSigSwitchedByIgnition" SG_ 2549874862 ISO_BattRegelung_Req_Data 0;
BA_ "GenSigFuncType" SG_ 2549874862 ISO_BattRegelung_Req_Data 9;
BA_ "GenSigSendType" SG_ 2549874862 ISO_BattRegelung_Req_Data 3;
BA_ "GenSigSwitchedByIgnition" SG_ 2550005934 ISO_BattRegelung_Resp_Data 0;
BA_ "GenSigFuncType" SG_ 2550005934 ISO_BattRegelung_Resp_Data 9;
BA_ "GenSigSendType" SG_ 2550005934 ISO_BattRegelung_Resp_Data 3;
BA_ "GenSigSwitchedByIgnition" SG_ 2549874844 ISO_BMS_48V_Req_Data 0;
BA_ "GenSigFuncType" SG_ 2549874844 ISO_BMS_48V_Req_Data 9;
BA_ "GenSigSendType" SG_ 2549874844 ISO_BMS_48V_Req_Data 3;
BA_ "GenSigSwitchedByIgnition" SG_ 2550005916 ISO_BMS_48V_Resp_Data 0;
BA_ "GenSigFuncType" SG_ 2550005916 ISO_BMS_48V_Resp_Data 9;
BA_ "GenSigSendType" SG_ 2550005916 ISO_BMS_48V_Resp_Data 3;
BA_ "GenSigSwitchedByIgnition" SG_ 2549874887 ISO_DCDC_HV_02_Req_Data 0;
BA_ "GenSigFuncType" SG_ 2549874887 ISO_DCDC_HV_02_Req_Data 9;
BA_ "GenSigSendType" SG_ 2549874887 ISO_DCDC_HV_02_Req_Data 3;
BA_ "GenSigSwitchedByIgnition" SG_ 2550005959 ISO_DCDC_HV_02_Resp_Data 0;
BA_ "GenSigFuncType" SG_ 2550005959 ISO_DCDC_HV_02_Resp_Data 9;
BA_ "GenSigSendType" SG_ 2550005959 ISO_DCDC_HV_02_Resp_Data 3;
BA_ "GenSigSwitchedByIgnition" SG_ 2549874895 ISOx_DCDC_HV_03_Req_Data 0;
BA_ "GenSigSendType" SG_ 2549874895 ISOx_DCDC_HV_03_Req_Data 3;
BA_ "GenSigSwitchedByIgnition" SG_ 2550005967 ISOx_DCDC_HV_03_Resp_Data 0;
BA_ "GenSigSendType" SG_ 2550005967 ISOx_DCDC_HV_03_Resp_Data 3;
BA_ "GenSigSwitchedByIgnition" SG_ 2549874871 ISO_DCDC_HV_Req_Data 0;
BA_ "GenSigFuncType" SG_ 2549874871 ISO_DCDC_HV_Req_Data 9;
BA_ "GenSigSendType" SG_ 2549874871 ISO_DCDC_HV_Req_Data 3;
BA_ "GenSigSwitchedByIgnition" SG_ 2550005943 ISO_DCDC_HV_Resp_Data 0;
BA_ "GenSigFuncType" SG_ 2550005943 ISO_DCDC_HV_Resp_Data 9;
BA_ "GenSigSendType" SG_ 2550005943 ISO_DCDC_HV_Resp_Data 3;
BA_ "GenSigSwitchedByIgnition" SG_ 2549874869 ISOx_FCU_Req_Data 0;
BA_ "GenSigFuncType" SG_ 2549874869 ISOx_FCU_Req_Data 9;
BA_ "GenSigSendType" SG_ 2549874869 ISOx_FCU_Req_Data 3;
BA_ "GenSigSwitchedByIgnition" SG_ 2550005941 ISOx_FCU_Resp_Data 0;
BA_ "GenSigFuncType" SG_ 2550005941 ISOx_FCU_Resp_Data 9;
BA_ "GenSigSendType" SG_ 2550005941 ISOx_FCU_Resp_Data 3;
BA_ "GenSigSwitchedByIgnition" SG_ 2549874811 ISO_Hybrid_01_Req_Data 0;
BA_ "GenSigFuncType" SG_ 2549874811 ISO_Hybrid_01_Req_Data 9;
BA_ "GenSigSendType" SG_ 2549874811 ISO_Hybrid_01_Req_Data 3;
BA_ "GenSigSwitchedByIgnition" SG_ 2550005883 ISO_Hybrid_01_Resp_Data 0;
BA_ "GenSigFuncType" SG_ 2550005883 ISO_Hybrid_01_Resp_Data 9;
BA_ "GenSigSendType" SG_ 2550005883 ISO_Hybrid_01_Resp_Data 3;
BA_ "GenSigSwitchedByIgnition" SG_ 2549874886 ISO_Ladegeraet_2_Req_Data 0;
BA_ "GenSigFuncType" SG_ 2549874886 ISO_Ladegeraet_2_Req_Data 9;
BA_ "GenSigSendType" SG_ 2549874886 ISO_Ladegeraet_2_Req_Data 3;
BA_ "GenSigSwitchedByIgnition" SG_ 2550005958 ISO_Ladegeraet_2_Resp_Data 0;
BA_ "GenSigFuncType" SG_ 2550005958 ISO_Ladegeraet_2_Resp_Data 9;
BA_ "GenSigSendType" SG_ 2550005958 ISO_Ladegeraet_2_Resp_Data 3;
BA_ "GenSigSwitchedByIgnition" SG_ 2549874868 ISOx_TelemetrieSG_Req_Data 0;
BA_ "GenSigSendType" SG_ 2549874868 ISOx_TelemetrieSG_Req_Data 3;
BA_ "GenSigSwitchedByIgnition" SG_ 2550005940 ISOx_TelemetrieSG_Resp_Data 0;
BA_ "GenSigSendType" SG_ 2550005940 ISOx_TelemetrieSG_Resp_Data 3;
BA_ "GenSigSwitchedByIgnition" SG_ 497 KY_IDG_in_Reichweite 0;
BA_ "GenSigSendType" SG_ 497 KY_IDG_in_Reichweite 2;
BA_ "GenSigActiveRepetitions" SG_ 497 KY_IDG_in_Reichweite 7;
BA_ "GenSigSwitchedByIgnition" SG_ 497 KY_Auf_Taste 0;
BA_ "GenSigSendType" SG_ 497 KY_Auf_Taste 2;
BA_ "GenSigActiveRepetitions" SG_ 497 KY_Auf_Taste 7;
BA_ "GenSigSwitchedByIgnition" SG_ 497 KY_HDF_Taste 0;
BA_ "GenSigSendType" SG_ 497 KY_HDF_Taste 2;
BA_ "GenSigActiveRepetitions" SG_ 497 KY_HDF_Taste 7;
BA_ "GenSigSwitchedByIgnition" SG_ 497 KY_Panik_Taste 0;
BA_ "GenSigSendType" SG_ 497 KY_Panik_Taste 2;
BA_ "GenSigActiveRepetitions" SG_ 497 KY_Panik_Taste 7;
BA_ "GenSigSwitchedByIgnition" SG_ 497 KY_Zu_Taste 0;
BA_ "GenSigSendType" SG_ 497 KY_Zu_Taste 2;
BA_ "GenSigActiveRepetitions" SG_ 497 KY_Zu_Taste 7;
BA_ "GenSigSwitchedByIgnition" SG_ 497 KY_FT_Entriegelung_Autorisiert 0;
BA_ "GenSigSendType" SG_ 497 KY_FT_Entriegelung_Autorisiert 2;
BA_ "GenSigActiveRepetitions" SG_ 497 KY_FT_Entriegelung_Autorisiert 7;
BA_ "GenSigSwitchedByIgnition" SG_ 497 KY_FT_Verriegelung_Autorisiert 0;
BA_ "GenSigSendType" SG_ 497 KY_FT_Verriegelung_Autorisiert 2;
BA_ "GenSigActiveRepetitions" SG_ 497 KY_FT_Verriegelung_Autorisiert 7;
BA_ "GenSigSwitchedByIgnition" SG_ 497 KY_BT_Entriegelung_Autorisiert 0;
BA_ "GenSigSendType" SG_ 497 KY_BT_Entriegelung_Autorisiert 2;
BA_ "GenSigActiveRepetitions" SG_ 497 KY_BT_Entriegelung_Autorisiert 7;
BA_ "GenSigSwitchedByIgnition" SG_ 497 KY_BT_Verriegelung_Autorisiert 0;
BA_ "GenSigSendType" SG_ 497 KY_BT_Verriegelung_Autorisiert 2;
BA_ "GenSigActiveRepetitions" SG_ 497 KY_BT_Verriegelung_Autorisiert 7;
BA_ "GenSigSwitchedByIgnition" SG_ 497 KY_HFS_Entriegelung_Autorisiert 0;
BA_ "GenSigSendType" SG_ 497 KY_HFS_Entriegelung_Autorisiert 2;
BA_ "GenSigActiveRepetitions" SG_ 497 KY_HFS_Entriegelung_Autorisiert 7;
BA_ "GenSigSwitchedByIgnition" SG_ 497 KY_HFS_Verriegelung_Autorisiert 0;
BA_ "GenSigSendType" SG_ 497 KY_HFS_Verriegelung_Autorisiert 2;
BA_ "GenSigActiveRepetitions" SG_ 497 KY_HFS_Verriegelung_Autorisiert 7;
BA_ "GenSigSwitchedByIgnition" SG_ 497 KY_HBFS_Entriegelung_Autorisiert 0;
BA_ "GenSigSendType" SG_ 497 KY_HBFS_Entriegelung_Autorisiert 2;
BA_ "GenSigActiveRepetitions" SG_ 497 KY_HBFS_Entriegelung_Autorisiert 7;
BA_ "GenSigSwitchedByIgnition" SG_ 497 KY_HBFS_Verriegelung_Autorisiert 0;
BA_ "GenSigSendType" SG_ 497 KY_HBFS_Verriegelung_Autorisiert 2;
BA_ "GenSigActiveRepetitions" SG_ 497 KY_HBFS_Verriegelung_Autorisiert 7;
BA_ "GenSigSwitchedByIgnition" SG_ 497 KY_Front_Entr_Autorisiert 0;
BA_ "GenSigSendType" SG_ 497 KY_Front_Entr_Autorisiert 2;
BA_ "GenSigActiveRepetitions" SG_ 497 KY_Front_Entr_Autorisiert 7;
BA_ "GenSigSwitchedByIgnition" SG_ 497 KY_Front_Verr_Autorisiert 0;
BA_ "GenSigSendType" SG_ 497 KY_Front_Verr_Autorisiert 2;
BA_ "GenSigActiveRepetitions" SG_ 497 KY_Front_Verr_Autorisiert 7;
BA_ "GenSigSwitchedByIgnition" SG_ 497 KY_HD_Entriegelung_Autorisiert 0;
BA_ "GenSigSendType" SG_ 497 KY_HD_Entriegelung_Autorisiert 2;
BA_ "GenSigActiveRepetitions" SG_ 497 KY_HD_Entriegelung_Autorisiert 7;
BA_ "GenSigSwitchedByIgnition" SG_ 497 KY_HD_Verriegelung_Autorisiert 0;
BA_ "GenSigSendType" SG_ 497 KY_HD_Verriegelung_Autorisiert 2;
BA_ "GenSigActiveRepetitions" SG_ 497 KY_HD_Verriegelung_Autorisiert 7;
BA_ "GenSigSwitchedByIgnition" SG_ 497 KY_Bereich 0;
BA_ "GenSigStartValue" SG_ 497 KY_Bereich 7;
BA_ "GenSigSendType" SG_ 497 KY_Bereich 2;
BA_ "GenSigActiveRepetitions" SG_ 497 KY_Bereich 7;
BA_ "GenSigSwitchedByIgnition" SG_ 497 KY_Position 0;
BA_ "GenSigStartValue" SG_ 497 KY_Position 7;
BA_ "GenSigSendType" SG_ 497 KY_Position 2;
BA_ "GenSigActiveRepetitions" SG_ 497 KY_Position 7;
BA_ "GenSigSwitchedByIgnition" SG_ 497 KY_ZV_Signatur 0;
BA_ "GenSigSendType" SG_ 497 KY_ZV_Signatur 2;
BA_ "GenSigActiveRepetitions" SG_ 497 KY_ZV_Signatur 7;
BA_ "Fehlerwert" SG_ 497 Schluesselnr_Personalisierung 15;
BA_ "GenSigSwitchedByIgnition" SG_ 497 Schluesselnr_Personalisierung 0;
BA_ "GenSigStartValue" SG_ 497 Schluesselnr_Personalisierung 14;
BA_ "GenSigSendType" SG_ 497 Schluesselnr_Personalisierung 2;
BA_ "GenSigActiveRepetitions" SG_ 497 Schluesselnr_Personalisierung 7;
BA_ "GenSigSwitchedByIgnition" SG_ 497 FFB_FDF_Taste 0;
BA_ "GenSigSendType" SG_ 497 FFB_FDF_Taste 2;
BA_ "GenSigActiveRepetitions" SG_ 497 FFB_FDF_Taste 7;
BA_ "GenSigSwitchedByIgnition" SG_ 497 FFB_Joker_Taste 0;
BA_ "GenSigSendType" SG_ 497 FFB_Joker_Taste 2;
BA_ "GenSigActiveRepetitions" SG_ 497 FFB_Joker_Taste 7;
BA_ "GenSigSwitchedByIgnition" SG_ 497 FFB_Park_Taste 0;
BA_ "GenSigSendType" SG_ 497 FFB_Park_Taste 2;
BA_ "GenSigActiveRepetitions" SG_ 497 FFB_Park_Taste 7;
BA_ "GenSigSwitchedByIgnition" SG_ 497 FFB_Remotestart_Taste 0;
BA_ "GenSigSendType" SG_ 497 FFB_Remotestart_Taste 2;
BA_ "GenSigActiveRepetitions" SG_ 497 FFB_Remotestart_Taste 7;
BA_ "GenSigSwitchedByIgnition" SG_ 497 FBS_Aktivierung_Pilot_Parken 0;
BA_ "GenSigSendType" SG_ 497 FBS_Aktivierung_Pilot_Parken 2;
BA_ "GenSigActiveRepetitions" SG_ 497 FBS_Aktivierung_Pilot_Parken 7;
BA_ "GenSigSwitchedByIgnition" SG_ 497 KY_Schluessel_im_Fzg 0;
BA_ "GenSigSendType" SG_ 497 KY_Schluessel_im_Fzg 2;
BA_ "GenSigActiveRepetitions" SG_ 497 KY_Schluessel_im_Fzg 7;
BA_ "GenSigSwitchedByIgnition" SG_ 497 KY_EasyClose_Abbruch 0;
BA_ "GenSigSendType" SG_ 497 KY_EasyClose_Abbruch 3;
BA_ "GenSigSwitchedByIgnition" SG_ 497 KY_EasyClose_Status 0;
BA_ "GenSigSendType" SG_ 497 KY_EasyClose_Status 3;
BA_ "GenSigSwitchedByIgnition" SG_ 497 KY_HD_Auffahrt 0;
BA_ "GenSigSendType" SG_ 497 KY_HD_Auffahrt 2;
BA_ "GenSigActiveRepetitions" SG_ 497 KY_HD_Auffahrt 7;
BA_ "GenSigSwitchedByIgnition" SG_ 497 KY_HD_Zufahrt 0;
BA_ "GenSigSendType" SG_ 497 KY_HD_Zufahrt 2;
BA_ "GenSigActiveRepetitions" SG_ 497 KY_HD_Zufahrt 7;
BA_ "GenSigSwitchedByIgnition" SG_ 497 KY_LKL_1_Autorisierung 0;
BA_ "GenSigSendType" SG_ 497 KY_LKL_1_Autorisierung 2;
BA_ "GenSigActiveRepetitions" SG_ 497 KY_LKL_1_Autorisierung 7;
BA_ "GenSigSwitchedByIgnition" SG_ 497 KY_LKL_2_Autorisierung 0;
BA_ "GenSigSendType" SG_ 497 KY_LKL_2_Autorisierung 2;
BA_ "GenSigActiveRepetitions" SG_ 497 KY_LKL_2_Autorisierung 7;
BA_ "GenSigSwitchedByIgnition" SG_ 960 Klemmen_Status_01_CRC 0;
BA_ "GenSigFuncType" SG_ 960 Klemmen_Status_01_CRC 2;
BA_ "GenSigSendType" SG_ 960 Klemmen_Status_01_CRC 0;
BA_ "GenSigSwitchedByIgnition" SG_ 960 Klemmen_Status_01_BZ 0;
BA_ "GenSigFuncType" SG_ 960 Klemmen_Status_01_BZ 1;
BA_ "GenSigSendType" SG_ 960 Klemmen_Status_01_BZ 0;
BA_ "GenSigSwitchedByIgnition" SG_ 960 RSt_Fahrerhinweise 0;
BA_ "GenSigSendType" SG_ 960 RSt_Fahrerhinweise 3;
BA_ "GenSigSwitchedByIgnition" SG_ 960 ZAS_Kl_S 0;
BA_ "GenSigSendType" SG_ 960 ZAS_Kl_S 3;
BA_ "GenSigSwitchedByIgnition" SG_ 960 ZAS_Kl_15 0;
BA_ "GenSigFuncType" SG_ 960 ZAS_Kl_15 6;
BA_ "NWM-WakeupAllowed" SG_ 960 ZAS_Kl_15 1;
BA_ "GenSigSendType" SG_ 960 ZAS_Kl_15 3;
BA_ "GenSigSwitchedByIgnition" SG_ 960 ZAS_Kl_X 0;
BA_ "GenSigSendType" SG_ 960 ZAS_Kl_X 3;
BA_ "GenSigSwitchedByIgnition" SG_ 960 ZAS_Kl_50_Startanforderung 0;
BA_ "GenSigSendType" SG_ 960 ZAS_Kl_50_Startanforderung 3;
BA_ "GenSigSwitchedByIgnition" SG_ 960 BCM_Remotestart_Betrieb 0;
BA_ "GenSigSendType" SG_ 960 BCM_Remotestart_Betrieb 3;
BA_ "GenSigSwitchedByIgnition" SG_ 960 ZAS_Kl_Infotainment 0;
BA_ "GenSigSendType" SG_ 960 ZAS_Kl_Infotainment 3;
BA_ "GenSigSwitchedByIgnition" SG_ 960 BCM_Remotestart_KL15_Anf 0;
BA_ "GenSigSendType" SG_ 960 BCM_Remotestart_KL15_Anf 3;
BA_ "GenSigSwitchedByIgnition" SG_ 960 BCM_Remotestart_MO_Start 0;
BA_ "GenSigSendType" SG_ 960 BCM_Remotestart_MO_Start 3;
BA_ "GenSigSwitchedByIgnition" SG_ 960 KST_Warn_P1_ZST_def 0;
BA_ "GenSigSendType" SG_ 960 KST_Warn_P1_ZST_def 3;
BA_ "GenSigSwitchedByIgnition" SG_ 960 KST_Warn_P2_ZST_def 0;
BA_ "GenSigSendType" SG_ 960 KST_Warn_P2_ZST_def 3;
BA_ "GenSigSwitchedByIgnition" SG_ 960 KST_Fahrerhinweis_1 0;
BA_ "GenSigSendType" SG_ 960 KST_Fahrerhinweis_1 3;
BA_ "GenSigSwitchedByIgnition" SG_ 960 KST_Fahrerhinweis_2 0;
BA_ "GenSigSendType" SG_ 960 KST_Fahrerhinweis_2 3;
BA_ "GenSigSwitchedByIgnition" SG_ 960 BCM_Ausparken_Betrieb 0;
BA_ "GenSigSendType" SG_ 960 BCM_Ausparken_Betrieb 3;
BA_ "GenSigSwitchedByIgnition" SG_ 960 KST_Fahrerhinweis_4 0;
BA_ "GenSigSendType" SG_ 960 KST_Fahrerhinweis_4 3;
BA_ "GenSigSwitchedByIgnition" SG_ 960 KST_Fahrerhinweis_5 0;
BA_ "GenSigSendType" SG_ 960 KST_Fahrerhinweis_5 3;
BA_ "GenSigSwitchedByIgnition" SG_ 960 KST_Fahrerhinweis_6 0;
BA_ "GenSigSendType" SG_ 960 KST_Fahrerhinweis_6 3;
BA_ "GenSigSwitchedByIgnition" SG_ 1646 KL_STL_aktiv 0;
BA_ "GenSigSendType" SG_ 1646 KL_STL_aktiv 3;
BA_ "GenSigSwitchedByIgnition" SG_ 1646 KL_STH_aktiv 0;
BA_ "GenSigSendType" SG_ 1646 KL_STH_aktiv 3;
BA_ "GenSigSwitchedByIgnition" SG_ 1646 KL_Solarluefter_aktiv 0;
BA_ "GenSigSendType" SG_ 1646 KL_Solarluefter_aktiv 3;
BA_ "GenSigSwitchedByIgnition" SG_ 1646 KL_Umluft_Taste 0;
BA_ "GenSigSendType" SG_ 1646 KL_Umluft_Taste 3;
BA_ "Fehlerwert" SG_ 1646 KL_Geblaese_Fond_Status 15;
BA_ "GenSigSwitchedByIgnition" SG_ 1646 KL_Geblaese_Fond_Status 0;
BA_ "GenSigStartValue" SG_ 1646 KL_Geblaese_Fond_Status 14;
BA_ "GenSigSendType" SG_ 1646 KL_Geblaese_Fond_Status 0;
BA_ "GenSigSwitchedByIgnition" SG_ 1646 KL_STH_Ansteuerung 0;
BA_ "GenSigSendType" SG_ 1646 KL_STH_Ansteuerung 3;
BA_ "GenSigSwitchedByIgnition" SG_ 1646 KL_STH_Betriebsdauer 0;
BA_ "GenSigSendType" SG_ 1646 KL_STH_Betriebsdauer 3;
BA_ "GenSigSendType" SG_ 1646 KL_Magnetventil 3;
BA_ "GenSigSwitchedByIgnition" SG_ 1646 KL_WaPu 0;
BA_ "GenSigSendType" SG_ 1646 KL_WaPu 3;
BA_ "Fehlerwert" SG_ 1646 KL_Geblaese_Status 15;
BA_ "GenSigSwitchedByIgnition" SG_ 1646 KL_Geblaese_Status 0;
BA_ "GenSigStartValue" SG_ 1646 KL_Geblaese_Status 14;
BA_ "GenSigSendType" SG_ 1646 KL_Geblaese_Status 0;
BA_ "GenSigSwitchedByIgnition" SG_ 1646 KL_Restwaerme_aktiv 0;
BA_ "GenSigSendType" SG_ 1646 KL_Restwaerme_aktiv 3;
BA_ "GenSigSwitchedByIgnition" SG_ 1646 KL_Kompressorkupplung 0;
BA_ "GenSigSendType" SG_ 1646 KL_Kompressorkupplung 3;
BA_ "GenSigSwitchedByIgnition" SG_ 1646 KL_BCmE_Livetip_Freigabe 0;
BA_ "GenSigSendType" SG_ 1646 KL_BCmE_Livetip_Freigabe 3;
BA_ "GenSigSwitchedByIgnition" SG_ 1646 KL_HYB_ASV_hinten_schliessen_Anf 0;
BA_ "GenSigSendType" SG_ 1646 KL_HYB_ASV_hinten_schliessen_Anf 3;
BA_ "GenSigSwitchedByIgnition" SG_ 1646 KL_HYB_ASV_vorne_schliessen_Anf 0;
BA_ "GenSigSendType" SG_ 1646 KL_HYB_ASV_vorne_schliessen_Anf 3;
BA_ "GenSigSwitchedByIgnition" SG_ 1646 KL_ErwVK_Zusatzrelais 0;
BA_ "GenSigSendType" SG_ 1646 KL_ErwVK_Zusatzrelais 3;
BA_ "GenSigSwitchedByIgnition" SG_ 1646 KL_Status_Beduftung 0;
BA_ "GenSigSendType" SG_ 1646 KL_Status_Beduftung 3;
BA_ "GenSigSwitchedByIgnition" SG_ 1646 KL_Status_Ionisator_Front 0;
BA_ "GenSigSendType" SG_ 1646 KL_Status_Ionisator_Front 3;
BA_ "GenSigSwitchedByIgnition" SG_ 1646 KL_STH_Timer_Status 0;
BA_ "GenSigSendType" SG_ 1646 KL_STH_Timer_Status 3;
BA_ "GenSigSwitchedByIgnition" SG_ 1646 KL_ErwVK_Anf 0;
BA_ "GenSigSendType" SG_ 1646 KL_ErwVK_Anf 3;
BA_ "Fehlerwert" SG_ 1646 KL_Innen_Temp 255;
BA_ "GenSigSwitchedByIgnition" SG_ 1646 KL_Innen_Temp 0;
BA_ "GenSigStartValue" SG_ 1646 KL_Innen_Temp 254;
BA_ "GenSigSendType" SG_ 1646 KL_Innen_Temp 0;
BA_ "Fehlerwert" SG_ 1646 KL_I_Geblaese_Fond 255;
BA_ "GenSigSendType" SG_ 1646 KL_I_Geblaese_Fond 3;
BA_ "GenSigSwitchedByIgnition" SG_ 1646 KL_Anf_AussenspiegelHzg 0;
BA_ "GenSigSendType" SG_ 1646 KL_Anf_AussenspiegelHzg 3;
BA_ "Fehlerwert" SG_ 1646 KL_Heizkreisventilstellung 3;
BA_ "GenSigSendType" SG_ 1646 KL_Heizkreisventilstellung 0;
BA_ "GenSigSendType" SG_ 1646 KL_FSH_Automatikbetrieb 3;
BA_ "GenSigSwitchedByIgnition" SG_ 1646 KL_SIH_LEH_Verteilung_VL 0;
BA_ "GenSigSendType" SG_ 1646 KL_SIH_LEH_Verteilung_VL 3;
BA_ "GenSigSwitchedByIgnition" SG_ 1646 KL_SIH_LEL_Verteilung_VL 0;
BA_ "GenSigSendType" SG_ 1646 KL_SIH_LEL_Verteilung_VL 3;
BA_ "GenSigSwitchedByIgnition" SG_ 1646 KL_SIH_LEH_Verteilung_VR 0;
BA_ "GenSigSendType" SG_ 1646 KL_SIH_LEH_Verteilung_VR 3;
BA_ "GenSigSwitchedByIgnition" SG_ 1646 KL_SIH_LEL_Verteilung_VR 0;
BA_ "GenSigSendType" SG_ 1646 KL_SIH_LEL_Verteilung_VR 3;
BA_ "GenSigSwitchedByIgnition" SG_ 1649 KL_ZZ_Minute 0;
BA_ "GenSigSendType" SG_ 1649 KL_ZZ_Minute 3;
BA_ "GenSigSwitchedByIgnition" SG_ 1649 KL_ZZ_Status_Timer 0;
BA_ "GenSigSendType" SG_ 1649 KL_ZZ_Status_Timer 3;
BA_ "GenSigSwitchedByIgnition" SG_ 1649 KL_ZZ_Monat 0;
BA_ "GenSigSendType" SG_ 1649 KL_ZZ_Monat 3;
BA_ "GenSigSwitchedByIgnition" SG_ 1649 KL_ZZ_Stunde 0;
BA_ "GenSigSendType" SG_ 1649 KL_ZZ_Stunde 3;
BA_ "GenSigSwitchedByIgnition" SG_ 1649 KL_ZZ_Betriebsmodus 0;
BA_ "GenSigSendType" SG_ 1649 KL_ZZ_Betriebsmodus 3;
BA_ "GenSigSwitchedByIgnition" SG_ 1649 KL_ZZ_Tag 0;
BA_ "GenSigSendType" SG_ 1649 KL_ZZ_Tag 3;
BA_ "GenSigSwitchedByIgnition" SG_ 1649 KL_Betriebsmodus_FH 0;
BA_ "GenSigSendType" SG_ 1649 KL_Betriebsmodus_FH 3;
BA_ "GenSigSwitchedByIgnition" SG_ 1649 KL_Stopp_Wiederstart_Anz_01 0;
BA_ "GenSigSendType" SG_ 1649 KL_Stopp_Wiederstart_Anz_01 3;
BA_ "GenSigSwitchedByIgnition" SG_ 1649 KL_Stopp_Wiederstart_Anz_02 0;
BA_ "GenSigSendType" SG_ 1649 KL_Stopp_Wiederstart_Anz_02 3;
BA_ "GenSigSwitchedByIgnition" SG_ 1649 KL_Stopp_Wiederstart_Anz_03 0;
BA_ "GenSigSendType" SG_ 1649 KL_Stopp_Wiederstart_Anz_03 3;
BA_ "GenSigSwitchedByIgnition" SG_ 1649 KL_Stopp_Wiederstart_Anz_04 0;
BA_ "GenSigSendType" SG_ 1649 KL_Stopp_Wiederstart_Anz_04 3;
BA_ "GenSigSwitchedByIgnition" SG_ 1649 KL_Stopp_Wiederstart_Anz_05 0;
BA_ "GenSigSendType" SG_ 1649 KL_Stopp_Wiederstart_Anz_05 3;
BA_ "GenSigSwitchedByIgnition" SG_ 1649 KL_Stopp_Wiederstart_Anz_06 0;
BA_ "GenSigSendType" SG_ 1649 KL_Stopp_Wiederstart_Anz_06 3;
BA_ "GenSigSwitchedByIgnition" SG_ 1649 KL_Stopp_Wiederstart_Anz_07 0;
BA_ "GenSigSendType" SG_ 1649 KL_Stopp_Wiederstart_Anz_07 3;
BA_ "GenSigSwitchedByIgnition" SG_ 1649 KL_Stopp_Wiederstart_Anz_08 0;
BA_ "GenSigSendType" SG_ 1649 KL_Stopp_Wiederstart_Anz_08 3;
BA_ "GenSigSwitchedByIgnition" SG_ 1649 KL_Stopp_Wiederstart_Anz_09 0;
BA_ "GenSigSendType" SG_ 1649 KL_Stopp_Wiederstart_Anz_09 3;
BA_ "GenSigSwitchedByIgnition" SG_ 1649 KL_Stopp_Wiederstart_Anz_Std1 0;
BA_ "GenSigSendType" SG_ 1649 KL_Stopp_Wiederstart_Anz_Std1 3;
BA_ "GenSigSwitchedByIgnition" SG_ 1649 KL_Stopp_Wiederstart_Anz_Std2 0;
BA_ "GenSigSendType" SG_ 1649 KL_Stopp_Wiederstart_Anz_Std2 3;
BA_ "GenSigSwitchedByIgnition" SG_ 949 KL_Drehz_Anh 0;
BA_ "GenSigSendType" SG_ 949 KL_Drehz_Anh 0;
BA_ "GenSigSwitchedByIgnition" SG_ 949 KL_Vorwarn_Komp_ein 0;
BA_ "GenSigSendType" SG_ 949 KL_Vorwarn_Komp_ein 0;
BA_ "GenSigSwitchedByIgnition" SG_ 949 KL_AC_Schalter 0;
BA_ "GenSigSendType" SG_ 949 KL_AC_Schalter 0;
BA_ "GenSigSwitchedByIgnition" SG_ 949 KL_Komp_Moment_alt 0;
BA_ "GenSigFuncType" SG_ 949 KL_Komp_Moment_alt 5;
BA_ "GenSigSendType" SG_ 949 KL_Komp_Moment_alt 0;
BA_ "GenSigSendType" SG_ 949 KL_Vorwarn_Zuheizer_ein 0;
BA_ "GenSigSwitchedByIgnition" SG_ 949 KL_Zustand 0;
BA_ "GenSigSendType" SG_ 949 KL_Zustand 0;
BA_ "GenSigSwitchedByIgnition" SG_ 949 KL_Kompressorkupplung_linear 0;
BA_ "GenSigStartValue" SG_ 949 KL_Kompressorkupplung_linear 254;
BA_ "GenSigSendType" SG_ 949 KL_Kompressorkupplung_linear 0;
BA_ "GenSigSwitchedByIgnition" SG_ 949 KL_Charisma_FahrPr 0;
BA_ "GenSigSendType" SG_ 949 KL_Charisma_FahrPr 0;
BA_ "GenSigSwitchedByIgnition" SG_ 949 KL_Charisma_Status 0;
BA_ "GenSigSendType" SG_ 949 KL_Charisma_Status 0;
BA_ "GenSigSwitchedByIgnition" SG_ 949 KL_nachtr_Stopp_Anf 0;
BA_ "GenSigSendType" SG_ 949 KL_nachtr_Stopp_Anf 0;
BA_ "GenSigSendType" SG_ 949 KL_T_Charge 0;
BA_ "Fehlerwert" SG_ 949 KL_Last_Kompr 255;
BA_ "GenSigSwitchedByIgnition" SG_ 949 KL_Last_Kompr 0;
BA_ "GenSigSendType" SG_ 949 KL_Last_Kompr 0;
BA_ "GenSigSwitchedByIgnition" SG_ 949 KL_Spannungs_Anf 0;
BA_ "GenSigSendType" SG_ 949 KL_Spannungs_Anf 0;
BA_ "GenSigSwitchedByIgnition" SG_ 949 KL_Thermomanagement 0;
BA_ "GenSigSendType" SG_ 949 KL_Thermomanagement 0;
BA_ "GenSigSwitchedByIgnition" SG_ 949 KL_StartStopp_Info 0;
BA_ "GenSigSendType" SG_ 949 KL_StartStopp_Info 0;
BA_ "GenSigSwitchedByIgnition" SG_ 949 KL_Freilauf_Info 0;
BA_ "GenSigSendType" SG_ 949 KL_Freilauf_Info 0;
BA_ "Fehlerwert" SG_ 949 KL_Anf_KL 255;
BA_ "GenSigSwitchedByIgnition" SG_ 949 KL_Anf_KL 0;
BA_ "GenSigSendType" SG_ 949 KL_Anf_KL 0;
BA_ "GenSigSwitchedByIgnition" SG_ 949 KL_el_Zuheizer_Stufe 0;
BA_ "GenSigSendType" SG_ 949 KL_el_Zuheizer_Stufe 0;
BA_ "GenSigSwitchedByIgnition" SG_ 949 KL_Ausstattung_Klima 0;
BA_ "GenSigSendType" SG_ 949 KL_Ausstattung_Klima 0;
BA_ "GenSigSendType" SG_ 949 KL_Variante_Standheizung 0;
BA_ "GenSigSwitchedByIgnition" SG_ 1640 KL_LRH_Taster 0;
BA_ "GenSigSendType" SG_ 1640 KL_LRH_Taster 4;
BA_ "GenSigActiveRepetitions" SG_ 1640 KL_LRH_Taster 5;
BA_ "GenSigSwitchedByIgnition" SG_ 1640 KL_LRH_Stufe 0;
BA_ "GenSigStartValue" SG_ 1640 KL_LRH_Stufe 1;
BA_ "GenSigSendType" SG_ 1640 KL_LRH_Stufe 0;
BA_ "GenSigSwitchedByIgnition" SG_ 1640 HSH_Taster 0;
BA_ "GenSigSendType" SG_ 1640 HSH_Taster 4;
BA_ "GenSigActiveRepetitions" SG_ 1640 HSH_Taster 5;
BA_ "GenSigSwitchedByIgnition" SG_ 1640 FSH_Taster 0;
BA_ "GenSigSendType" SG_ 1640 FSH_Taster 4;
BA_ "GenSigActiveRepetitions" SG_ 1640 FSH_Taster 5;
BA_ "GenSigSwitchedByIgnition" SG_ 1640 KL_Zuheizer_Freigabe 0;
BA_ "GenSigSendType" SG_ 1640 KL_Zuheizer_Freigabe 3;
BA_ "GenSigSwitchedByIgnition" SG_ 1640 KL_Beschlagsgefahr 0;
BA_ "GenSigSendType" SG_ 1640 KL_Beschlagsgefahr 3;
BA_ "GenSigSwitchedByIgnition" SG_ 1640 KL_SIH_Soll_li 0;
BA_ "GenSigSendType" SG_ 1640 KL_SIH_Soll_li 3;
BA_ "GenSigSwitchedByIgnition" SG_ 1640 KL_SIH_Soll_re 0;
BA_ "GenSigSendType" SG_ 1640 KL_SIH_Soll_re 3;
BA_ "GenSigSwitchedByIgnition" SG_ 1640 KRH_Soll_li 0;
BA_ "GenSigSendType" SG_ 1640 KRH_Soll_li 3;
BA_ "GenSigSwitchedByIgnition" SG_ 1640 KL_SIL_Soll_li 0;
BA_ "GenSigSendType" SG_ 1640 KL_SIL_Soll_li 3;
BA_ "GenSigSwitchedByIgnition" SG_ 1640 KL_SIL_Soll_re 0;
BA_ "GenSigSendType" SG_ 1640 KL_SIL_Soll_re 3;
BA_ "GenSigSwitchedByIgnition" SG_ 1640 KRH_Soll_re 0;
BA_ "GenSigSendType" SG_ 1640 KRH_Soll_re 3;
BA_ "Fehlerwert" SG_ 1640 KL_Geblspng_Soll 255;
BA_ "GenSigSendType" SG_ 1640 KL_Geblspng_Soll 0;
BA_ "Fehlerwert" SG_ 1640 KL_Geblspng_Fond_Soll 255;
BA_ "GenSigSendType" SG_ 1640 KL_Geblspng_Fond_Soll 0;
BA_ "Fehlerwert" SG_ 1640 KL_I_Geblaese 255;
BA_ "GenSigSwitchedByIgnition" SG_ 1640 KL_I_Geblaese 0;
BA_ "GenSigSendType" SG_ 1640 KL_I_Geblaese 0;
BA_ "Fehlerwert" SG_ 1640 KL_Kompressorstrom_soll 1023;
BA_ "GenSigSwitchedByIgnition" SG_ 1640 KL_Kompressorstrom_soll 0;
BA_ "GenSigStartValue" SG_ 1640 KL_Kompressorstrom_soll 1022;
BA_ "GenSigSendType" SG_ 1640 KL_Kompressorstrom_soll 0;
BA_ "Fehlerwert" SG_ 1640 KL_Umluftklappe_Status 15;
BA_ "GenSigSwitchedByIgnition" SG_ 1640 KL_Umluftklappe_Status 0;
BA_ "GenSigStartValue" SG_ 1640 KL_Umluftklappe_Status 14;
BA_ "GenSigSendType" SG_ 1640 KL_Umluftklappe_Status 0;
BA_ "GenSigSendType" SG_ 1640 KL_PTC_Verbauinfo 0;
BA_ "GenSigSwitchedByIgnition" SG_ 1441 KL_Temp_Soll_hl 0;
BA_ "GenSigStartValue" SG_ 1441 KL_Temp_Soll_hl 31;
BA_ "GenSigSendType" SG_ 1441 KL_Temp_Soll_hl 0;
BA_ "GenSigSwitchedByIgnition" SG_ 1441 KL_Temp_Soll_hr 0;
BA_ "GenSigStartValue" SG_ 1441 KL_Temp_Soll_hr 31;
BA_ "GenSigSendType" SG_ 1441 KL_Temp_Soll_hr 0;
BA_ "GenSigSwitchedByIgnition" SG_ 1441 KL_Temp_Soll_vl 0;
BA_ "GenSigStartValue" SG_ 1441 KL_Temp_Soll_vl 31;
BA_ "GenSigSendType" SG_ 1441 KL_Temp_Soll_vl 0;
BA_ "GenSigSwitchedByIgnition" SG_ 1441 KL_Temp_Soll_vr 0;
BA_ "GenSigStartValue" SG_ 1441 KL_Temp_Soll_vr 31;
BA_ "GenSigSendType" SG_ 1441 KL_Temp_Soll_vr 0;
BA_ "GenSigSwitchedByIgnition" SG_ 1441 KL_SIH_Stufe_hl 0;
BA_ "GenSigSendType" SG_ 1441 KL_SIH_Stufe_hl 0;
BA_ "GenSigSwitchedByIgnition" SG_ 1441 KL_SIH_Stufe_hr 0;
BA_ "GenSigSendType" SG_ 1441 KL_SIH_Stufe_hr 0;
BA_ "GenSigSwitchedByIgnition" SG_ 1441 KL_SIL_Stufe_hl 0;
BA_ "GenSigSendType" SG_ 1441 KL_SIL_Stufe_hl 0;
BA_ "GenSigSwitchedByIgnition" SG_ 1441 KL_SIL_Stufe_hr 0;
BA_ "GenSigSendType" SG_ 1441 KL_SIL_Stufe_hr 0;
BA_ "GenSigSwitchedByIgnition" SG_ 1441 KL_SIL_LEL_Verteilung_HR 0;
BA_ "GenSigSendType" SG_ 1441 KL_SIL_LEL_Verteilung_HR 0;
BA_ "GenSigSwitchedByIgnition" SG_ 1441 KL_SIL_LEL_Verteilung_HL 0;
BA_ "GenSigSendType" SG_ 1441 KL_SIL_LEL_Verteilung_HL 0;
BA_ "GenSigSwitchedByIgnition" SG_ 1441 KL_SIH_LEH_Verteilung_HR 0;
BA_ "GenSigSendType" SG_ 1441 KL_SIH_LEH_Verteilung_HR 0;
BA_ "Fehlerwert" SG_ 1441 KL_PTC_linear_Anf 63;
BA_ "GenSigSwitchedByIgnition" SG_ 1441 KL_PTC_linear_Anf 0;
BA_ "GenSigSendType" SG_ 1441 KL_PTC_linear_Anf 0;
BA_ "GenSigSwitchedByIgnition" SG_ 1441 KL_SIH_LEH_Verteilung_HL 0;
BA_ "GenSigSendType" SG_ 1441 KL_SIH_LEH_Verteilung_HL 0;
BA_ "Fehlerwert" SG_ 1441 KL_Frischluftklappe_Status 127;
BA_ "GenSigSwitchedByIgnition" SG_ 1441 KL_Frischluftklappe_Status 0;
BA_ "GenSigStartValue" SG_ 1441 KL_Frischluftklappe_Status 126;
BA_ "GenSigSendType" SG_ 1441 KL_Frischluftklappe_Status 0;
BA_ "Fehlerwert" SG_ 2589283469 KL_Verdampferleistung 255;
BA_ "GenSigSwitchedByIgnition" SG_ 2589283469 KL_Verdampferleistung 0;
BA_ "GenSigStartValue" SG_ 2589283469 KL_Verdampferleistung 254;
BA_ "GenSigSendType" SG_ 2589283469 KL_Verdampferleistung 3;
BA_ "Fehlerwert" SG_ 2589283469 KL_VK_Anf 7;
BA_ "GenSigSwitchedByIgnition" SG_ 2589283469 KL_VK_Anf 0;
BA_ "GenSigStartValue" SG_ 2589283469 KL_VK_Anf 6;
BA_ "GenSigSendType" SG_ 2589283469 KL_VK_Anf 3;
BA_ "GenSigSwitchedByIgnition" SG_ 2589283469 KL_Verdampferleistung_Faktor 0;
BA_ "GenSigSendType" SG_ 2589283469 KL_Verdampferleistung_Faktor 3;
BA_ "Fehlerwert" SG_ 2589283469 KL_Geblaese_Fond_erw 15;
BA_ "GenSigSwitchedByIgnition" SG_ 2589283469 KL_Geblaese_Fond_erw 0;
BA_ "GenSigStartValue" SG_ 2589283469 KL_Geblaese_Fond_erw 14;
BA_ "GenSigSendType" SG_ 2589283469 KL_Geblaese_Fond_erw 0;
BA_ "Fehlerwert" SG_ 2589283469 KL_Geblaese_erw 15;
BA_ "GenSigSwitchedByIgnition" SG_ 2589283469 KL_Geblaese_erw 0;
BA_ "GenSigStartValue" SG_ 2589283469 KL_Geblaese_erw 14;
BA_ "GenSigSendType" SG_ 2589283469 KL_Geblaese_erw 0;
BA_ "GenSigSwitchedByIgnition" SG_ 2589283469 KL_Vorkond_Strategie 0;
BA_ "GenSigStartValue" SG_ 2589283469 KL_Vorkond_Strategie 15;
BA_ "GenSigSendType" SG_ 2589283469 KL_Vorkond_Strategie 3;
BA_ "Fehlerwert" SG_ 2589283469 KL_Tempklappe_re 255;
BA_ "GenSigSwitchedByIgnition" SG_ 2589283469 KL_Tempklappe_re 0;
BA_ "GenSigStartValue" SG_ 2589283469 KL_Tempklappe_re 254;
BA_ "GenSigSendType" SG_ 2589283469 KL_Tempklappe_re 0;
BA_ "Fehlerwert" SG_ 2589283469 KL_Tempklappe_li 255;
BA_ "GenSigSwitchedByIgnition" SG_ 2589283469 KL_Tempklappe_li 0;
BA_ "GenSigStartValue" SG_ 2589283469 KL_Tempklappe_li 254;
BA_ "GenSigSendType" SG_ 2589283469 KL_Tempklappe_li 0;
BA_ "Fehlerwert" SG_ 2589283469 KL_Tempklappe_Fond 255;
BA_ "GenSigSwitchedByIgnition" SG_ 2589283469 KL_Tempklappe_Fond 0;
BA_ "GenSigStartValue" SG_ 2589283469 KL_Tempklappe_Fond 254;
BA_ "GenSigSendType" SG_ 2589283469 KL_Tempklappe_Fond 0;
BA_ "Fehlerwert" SG_ 2589283469 KL_Kuehllstg_Delta_Eingriff 255;
BA_ "GenSigSwitchedByIgnition" SG_ 2589283469 KL_Kuehllstg_Delta_Eingriff 0;
BA_ "GenSigStartValue" SG_ 2589283469 KL_Kuehllstg_Delta_Eingriff 254;
BA_ "GenSigSendType" SG_ 2589283469 KL_Kuehllstg_Delta_Eingriff 3;
BA_ "Fehlerwert" SG_ 2589283469 KL_Heizlstg_Delta_Eingriff 255;
BA_ "GenSigSwitchedByIgnition" SG_ 2589283469 KL_Heizlstg_Delta_Eingriff 0;
BA_ "GenSigStartValue" SG_ 2589283469 KL_Heizlstg_Delta_Eingriff 254;
BA_ "GenSigSendType" SG_ 2589283469 KL_Heizlstg_Delta_Eingriff 3;
BA_ "Fehlerwert" SG_ 2589283621 KL_NV_Energie_Anf 255;
BA_ "GenSigSwitchedByIgnition" SG_ 2589283621 KL_NV_Energie_Anf 0;
BA_ "GenSigStartValue" SG_ 2589283621 KL_NV_Energie_Anf 254;
BA_ "GenSigSendType" SG_ 2589283621 KL_NV_Energie_Anf 3;
BA_ "GenSigSwitchedByIgnition" SG_ 2589283621 KL_FlHz_Soll_VL 0;
BA_ "GenSigSendType" SG_ 2589283621 KL_FlHz_Soll_VL 3;
BA_ "GenSigSwitchedByIgnition" SG_ 2589283621 KL_FlHz_Soll_HL 0;
BA_ "GenSigSendType" SG_ 2589283621 KL_FlHz_Soll_HL 3;
BA_ "GenSigSwitchedByIgnition" SG_ 2589283621 KL_FlHz_Soll_VR 0;
BA_ "GenSigSendType" SG_ 2589283621 KL_FlHz_Soll_VR 3;
BA_ "GenSigSwitchedByIgnition" SG_ 2589283621 KL_FlHz_Soll_HR 0;
BA_ "GenSigSendType" SG_ 2589283621 KL_FlHz_Soll_HR 3;
BA_ "GenSigSwitchedByIgnition" SG_ 2589283621 KL_Umluft_Connect_status 0;
BA_ "GenSigSendType" SG_ 2589283621 KL_Umluft_Connect_status 3;
BA_ "GenSigSwitchedByIgnition" SG_ 2589283621 KL_ECO_PRO_Aktiv 0;
BA_ "GenSigSendType" SG_ 2589283621 KL_ECO_PRO_Aktiv 3;
BA_ "GenSigSwitchedByIgnition" SG_ 2589283621 KL_QBit_Sonnenintensitaet 0;
BA_ "GenSigStartValue" SG_ 2589283621 KL_QBit_Sonnenintensitaet 1;
BA_ "GenSigSendType" SG_ 2589283621 KL_QBit_Sonnenintensitaet 3;
BA_ "GenSigSwitchedByIgnition" SG_ 2589283621 KL_ZR_Anforderung 0;
BA_ "GenSigSendType" SG_ 2589283621 KL_ZR_Anforderung 3;
BA_ "GenSigSwitchedByIgnition" SG_ 2589283621 KL_ACmax_Aktiv 0;
BA_ "GenSigSendType" SG_ 2589283621 KL_ACmax_Aktiv 3;
BA_ "GenSigSwitchedByIgnition" SG_ 2589283621 KL_Defrost_Aktiv 0;
BA_ "GenSigSendType" SG_ 2589283621 KL_Defrost_Aktiv 3;
BA_ "GenSigSwitchedByIgnition" SG_ 2589283621 KL_ECO_Aktiv 0;
BA_ "GenSigSendType" SG_ 2589283621 KL_ECO_Aktiv 3;
BA_ "GenSigSwitchedByIgnition" SG_ 2589283621 KL_Status_Klimastil 0;
BA_ "GenSigSendType" SG_ 2589283621 KL_Status_Klimastil 3;
BA_ "GenSigSwitchedByIgnition" SG_ 2589283621 KL_Kundeneingriff_Geblaese 0;
BA_ "GenSigSendType" SG_ 2589283621 KL_Kundeneingriff_Geblaese 3;
BA_ "Fehlerwert" SG_ 2589283621 KL_Thermischer_Bedarf 7;
BA_ "GenSigSwitchedByIgnition" SG_ 2589283621 KL_Thermischer_Bedarf 0;
BA_ "GenSigStartValue" SG_ 2589283621 KL_Thermischer_Bedarf 6;
BA_ "GenSigSendType" SG_ 2589283621 KL_Thermischer_Bedarf 3;
BA_ "Fehlerwert" SG_ 2589283621 KL_Eps_Innen 255;
BA_ "GenSigSwitchedByIgnition" SG_ 2589283621 KL_Eps_Innen 0;
BA_ "GenSigStartValue" SG_ 2589283621 KL_Eps_Innen 254;
BA_ "GenSigSendType" SG_ 2589283621 KL_Eps_Innen 3;
BA_ "Fehlerwert" SG_ 2589283621 KL_Sonnenintensitaet 255;
BA_ "GenSigSwitchedByIgnition" SG_ 2589283621 KL_Sonnenintensitaet 0;
BA_ "GenSigSendType" SG_ 2589283621 KL_Sonnenintensitaet 0;
BA_ "GenSigSwitchedByIgnition" SG_ 2463978701 KL_Temp_Soll_vr_Prognose 0;
BA_ "GenSigStartValue" SG_ 2463978701 KL_Temp_Soll_vr_Prognose 31;
BA_ "GenSigSendType" SG_ 2463978701 KL_Temp_Soll_vr_Prognose 0;
BA_ "GenSigSwitchedByIgnition" SG_ 2463978701 KL_Leistungsreduktions_Hinweis 0;
BA_ "GenSigSendType" SG_ 2463978701 KL_Leistungsreduktions_Hinweis 0;
BA_ "GenSigSwitchedByIgnition" SG_ 2463978701 KL_AC_Schalter_Prognose 0;
BA_ "GenSigSendType" SG_ 2463978701 KL_AC_Schalter_Prognose 0;
BA_ "GenSigSwitchedByIgnition" SG_ 2463978701 KL_Temp_Soll_vl_Prognose 0;
BA_ "GenSigStartValue" SG_ 2463978701 KL_Temp_Soll_vl_Prognose 31;
BA_ "GenSigSendType" SG_ 2463978701 KL_Temp_Soll_vl_Prognose 0;
BA_ "GenSigSwitchedByIgnition" SG_ 2463978701 KL_Sollklimamodus_FPR_1 0;
BA_ "GenSigStartValue" SG_ 2463978701 KL_Sollklimamodus_FPR_1 1;
BA_ "GenSigSendType" SG_ 2463978701 KL_Sollklimamodus_FPR_1 0;
BA_ "GenSigSwitchedByIgnition" SG_ 2463978701 KL_Temp_Soll_hr_Prognose 0;
BA_ "GenSigStartValue" SG_ 2463978701 KL_Temp_Soll_hr_Prognose 31;
BA_ "GenSigSendType" SG_ 2463978701 KL_Temp_Soll_hr_Prognose 0;
BA_ "GenSigSwitchedByIgnition" SG_ 2463978701 KL_Sollklimamodus_FPR_2 0;
BA_ "GenSigStartValue" SG_ 2463978701 KL_Sollklimamodus_FPR_2 1;
BA_ "GenSigSendType" SG_ 2463978701 KL_Sollklimamodus_FPR_2 0;
BA_ "GenSigSwitchedByIgnition" SG_ 2463978701 KL_Temp_Soll_hl_Prognose 0;
BA_ "GenSigStartValue" SG_ 2463978701 KL_Temp_Soll_hl_Prognose 31;
BA_ "GenSigSendType" SG_ 2463978701 KL_Temp_Soll_hl_Prognose 0;
BA_ "GenSigSwitchedByIgnition" SG_ 2463978701 KL_Sollklimamodus_FPR_3 0;
BA_ "GenSigStartValue" SG_ 2463978701 KL_Sollklimamodus_FPR_3 1;
BA_ "GenSigSendType" SG_ 2463978701 KL_Sollklimamodus_FPR_3 0;
BA_ "GenSigMissingSourceValue" SG_ 1712 FS_Taupunkt 1023;
BA_ "Fehlerwert" SG_ 1712 FS_Taupunkt 1023;
BA_ "GenSigSendType" SG_ 1712 FS_Taupunkt 0;
BA_ "Fehlerwert" SG_ 1712 FS_ResponseError 1;
BA_ "GenSigSwitchedByIgnition" SG_ 1712 FS_ResponseError 0;
BA_ "GenSigSendType" SG_ 1712 FS_ResponseError 0;
BA_ "GenSigMissingSourceValue" SG_ 1712 FS_Temp_Scheibe 1023;
BA_ "Fehlerwert" SG_ 1712 FS_Temp_Scheibe 1023;
BA_ "GenSigSendType" SG_ 1712 FS_Temp_Scheibe 0;
BA_ "GenSigMissingSourceValue" SG_ 1712 FS_Temp_Sensor 255;
BA_ "Fehlerwert" SG_ 1712 FS_Temp_Sensor 255;
BA_ "GenSigSendType" SG_ 1712 FS_Temp_Sensor 0;
BA_ "GenSigMissingSourceValue" SG_ 1712 FS_Luftfeuchte_rel 255;
BA_ "Fehlerwert" SG_ 1712 FS_Luftfeuchte_rel 255;
BA_ "GenSigSendType" SG_ 1712 FS_Luftfeuchte_rel 0;
BA_ "Fehlerwert" SG_ 1505 BCM1_Aussen_Temp_ungef 255;
BA_ "GenSigSwitchedByIgnition" SG_ 1505 BCM1_Aussen_Temp_ungef 0;
BA_ "GenSigStartValue" SG_ 1505 BCM1_Aussen_Temp_ungef 254;
BA_ "GenSigSendType" SG_ 1505 BCM1_Aussen_Temp_ungef 0;
BA_ "Fehlerwert" SG_ 1505 BCM_Heizungsabsperrventil_Status 3;
BA_ "GenSigSwitchedByIgnition" SG_ 1505 BCM_Heizungsabsperrventil_Status 0;
BA_ "GenSigStartValue" SG_ 1505 BCM_Heizungsabsperrventil_Status 2;
BA_ "GenSigSendType" SG_ 1505 BCM_Heizungsabsperrventil_Status 0;
BA_ "Fehlerwert" SG_ 1505 BCM_Heizungspumpe_Status 3;
BA_ "GenSigSwitchedByIgnition" SG_ 1505 BCM_Heizungspumpe_Status 0;
BA_ "GenSigStartValue" SG_ 1505 BCM_Heizungspumpe_Status 2;
BA_ "GenSigSendType" SG_ 1505 BCM_Heizungspumpe_Status 0;
BA_ "Fehlerwert" SG_ 1505 BCM_Kompressorkupplung_Status 3;
BA_ "GenSigSwitchedByIgnition" SG_ 1505 BCM_Kompressorkupplung_Status 0;
BA_ "GenSigStartValue" SG_ 1505 BCM_Kompressorkupplung_Status 2;
BA_ "GenSigSendType" SG_ 1505 BCM_Kompressorkupplung_Status 0;
BA_ "Fehlerwert" SG_ 1505 BCM1_PTC_stufig_Status 7;
BA_ "GenSigSwitchedByIgnition" SG_ 1505 BCM1_PTC_stufig_Status 0;
BA_ "GenSigStartValue" SG_ 1505 BCM1_PTC_stufig_Status 6;
BA_ "GenSigSendType" SG_ 1505 BCM1_PTC_stufig_Status 0;
BA_ "GenSigSwitchedByIgnition" SG_ 1505 BCM1_FStatus_Aussentemp_ungef 0;
BA_ "GenSigStartValue" SG_ 1505 BCM1_FStatus_Aussentemp_ungef 1;
BA_ "GenSigSendType" SG_ 1505 BCM1_FStatus_Aussentemp_ungef 0;
BA_ "Fehlerwert" SG_ 1505 BCM1_Kompressorstrom_ist 255;
BA_ "GenSigSwitchedByIgnition" SG_ 1505 BCM1_Kompressorstrom_ist 0;
BA_ "GenSigStartValue" SG_ 1505 BCM1_Kompressorstrom_ist 254;
BA_ "GenSigSendType" SG_ 1505 BCM1_Kompressorstrom_ist 0;
BA_ "GenSigSwitchedByIgnition" SG_ 1505 BCM1_OBD_FStatus_ATemp 0;
BA_ "GenSigSendType" SG_ 1505 BCM1_OBD_FStatus_ATemp 0;
BA_ "GenSigStartValue" SG_ 1717 FSA_Taupunkt 1022;
BA_ "GenSigSendType" SG_ 1717 FSA_Taupunkt 0;
BA_ "GenSigSendType" SG_ 1717 FSA_Err_Defekt_Tsens_TF 0;
BA_ "GenSigStartValue" SG_ 1717 FSA_Luftfeuchte_TNCTOC 1;
BA_ "GenSigSendType" SG_ 1717 FSA_Luftfeuchte_TNCTOC 0;
BA_ "GenSigSendType" SG_ 1717 FSA_Luftfeuchte_TF 0;
BA_ "GenSigSendType" SG_ 1717 FSA_Err_Unterspannung_TF 0;
BA_ "GenSigSendType" SG_ 1717 FSA_Err_RAMROM_Check_TF 0;
BA_ "Fehlerwert" SG_ 1717 FSA_ResponseError 1;
BA_ "GenSigSendType" SG_ 1717 FSA_ResponseError 0;
BA_ "GenSigStartValue" SG_ 1717 FSA_Temp_Luft 1022;
BA_ "GenSigSendType" SG_ 1717 FSA_Temp_Luft 0;
BA_ "GenSigStartValue" SG_ 1717 FSA_Err_RAMROM_Check_TNCTOC 1;
BA_ "GenSigSendType" SG_ 1717 FSA_Err_RAMROM_Check_TNCTOC 0;
BA_ "Fehlerwert" SG_ 1717 FSA_Lokal_Bus_elektr_Fehler 1;
BA_ "GenSigSwitchedByIgnition" SG_ 1717 FSA_Lokal_Bus_elektr_Fehler 0;
BA_ "GenSigSendType" SG_ 1717 FSA_Lokal_Bus_elektr_Fehler 0;
BA_ "Fehlerwert" SG_ 1717 FSA_Timeout 1;
BA_ "GenSigSwitchedByIgnition" SG_ 1717 FSA_Timeout 0;
BA_ "GenSigSendType" SG_ 1717 FSA_Timeout 0;
BA_ "Fehlerwert" SG_ 1717 FSA_Lokal_Bus_Unterbrechung 1;
BA_ "GenSigSwitchedByIgnition" SG_ 1717 FSA_Lokal_Bus_Unterbrechung 0;
BA_ "GenSigSendType" SG_ 1717 FSA_Lokal_Bus_Unterbrechung 0;
BA_ "GenSigSendType" SG_ 1717 FSA_Err_Ueberspannung_TF 0;
BA_ "Fehlerwert" SG_ 1717 FSA_Luftfeuchte_rel 255;
BA_ "GenSigStartValue" SG_ 1717 FSA_Luftfeuchte_rel 254;
BA_ "GenSigSendType" SG_ 1717 FSA_Luftfeuchte_rel 0;
BA_ "GenSigSendType" SG_ 1717 FSA_HW 0;
BA_ "GenSigSendType" SG_ 1717 FSA_SW 0;
BA_ "GenSigStartValue" SG_ 1717 FSA_Temp_Sensor 2046;
BA_ "GenSigSendType" SG_ 1717 FSA_Temp_Sensor 0;
BA_ "GenSigSendType" SG_ 1717 FSA_Sensorheizung_Status 0;
BA_ "GenSigSendType" SG_ 1717 FSA_Err_Defekt_HumSense_TF 0;
BA_ "GenSigStartValue" SG_ 1717 FSA_Err_Defekt_HumSens_TNCTOC 1;
BA_ "GenSigSendType" SG_ 1717 FSA_Err_Defekt_HumSens_TNCTOC 0;
BA_ "GenSigSendType" SG_ 1717 FSA_ErrMemState 0;
BA_ "Fehlerwert" SG_ 1513 DS_Kaeltemittel_P 2047;
BA_ "GenSigSwitchedByIgnition" SG_ 1513 DS_Kaeltemittel_P 0;
BA_ "GenSigStartValue" SG_ 1513 DS_Kaeltemittel_P 2046;
BA_ "GenSigSendType" SG_ 1513 DS_Kaeltemittel_P 0;
BA_ "Fehlerwert" SG_ 1513 DS_Status 3;
BA_ "GenSigSwitchedByIgnition" SG_ 1513 DS_Status 0;
BA_ "GenSigStartValue" SG_ 1513 DS_Status 2;
BA_ "GenSigSendType" SG_ 1513 DS_Status 0;
BA_ "GenSigStartValue" SG_ 1513 ION_Status 2;
BA_ "GenSigSendType" SG_ 1513 ION_Status 0;
BA_ "GenSigSendType" SG_ 1513 ION_Status_LED 0;
BA_ "Fehlerwert" SG_ 1513 AAU_Geblaese 127;
BA_ "GenSigSwitchedByIgnition" SG_ 1513 AAU_Geblaese 0;
BA_ "GenSigStartValue" SG_ 1513 AAU_Geblaese 126;
BA_ "GenSigSendType" SG_ 1513 AAU_Geblaese 0;
BA_ "GenSigSendType" SG_ 1513 ION_Status_Taster 0;
BA_ "Fehlerwert" SG_ 1295 KL_Kuehlenergie_instat_pred 255;
BA_ "GenSigSwitchedByIgnition" SG_ 1295 KL_Kuehlenergie_instat_pred 0;
BA_ "GenSigStartValue" SG_ 1295 KL_Kuehlenergie_instat_pred 254;
BA_ "GenSigSendType" SG_ 1295 KL_Kuehlenergie_instat_pred 0;
BA_ "Fehlerwert" SG_ 1295 KL_Heizenergie_instat_pred 255;
BA_ "GenSigSwitchedByIgnition" SG_ 1295 KL_Heizenergie_instat_pred 0;
BA_ "GenSigStartValue" SG_ 1295 KL_Heizenergie_instat_pred 254;
BA_ "GenSigSendType" SG_ 1295 KL_Heizenergie_instat_pred 0;
BA_ "GenSigSwitchedByIgnition" SG_ 1295 KL_PTC_ein 0;
BA_ "GenSigSendType" SG_ 1295 KL_PTC_ein 0;
BA_ "GenSigSwitchedByIgnition" SG_ 1295 KL_Leistungspriorisierung 0;
BA_ "GenSigSendType" SG_ 1295 KL_Leistungspriorisierung 0;
BA_ "Fehlerwert" SG_ 1295 KL_Verdampfertemperatur 1023;
BA_ "GenSigSwitchedByIgnition" SG_ 1295 KL_Verdampfertemperatur 0;
BA_ "GenSigStartValue" SG_ 1295 KL_Verdampfertemperatur 1022;
BA_ "GenSigSendType" SG_ 1295 KL_Verdampfertemperatur 0;
BA_ "Fehlerwert" SG_ 1295 KL_Heizbedarf 1023;
BA_ "GenSigSwitchedByIgnition" SG_ 1295 KL_Heizbedarf 0;
BA_ "GenSigStartValue" SG_ 1295 KL_Heizbedarf 1022;
BA_ "GenSigSendType" SG_ 1295 KL_Heizbedarf 0;
BA_ "Fehlerwert" SG_ 1295 KL_Kuehlbedarf 255;
BA_ "GenSigSwitchedByIgnition" SG_ 1295 KL_Kuehlbedarf 0;
BA_ "GenSigStartValue" SG_ 1295 KL_Kuehlbedarf 254;
BA_ "GenSigSendType" SG_ 1295 KL_Kuehlbedarf 0;
BA_ "Fehlerwert" SG_ 1295 KL_Kuehlleistg_stat_erw 255;
BA_ "GenSigSwitchedByIgnition" SG_ 1295 KL_Kuehlleistg_stat_erw 0;
BA_ "GenSigStartValue" SG_ 1295 KL_Kuehlleistg_stat_erw 254;
BA_ "GenSigSendType" SG_ 1295 KL_Kuehlleistg_stat_erw 0;
BA_ "Fehlerwert" SG_ 1295 KL_Heizleistg_stat_erw 255;
BA_ "GenSigSwitchedByIgnition" SG_ 1295 KL_Heizleistg_stat_erw 0;
BA_ "GenSigStartValue" SG_ 1295 KL_Heizleistg_stat_erw 254;
BA_ "GenSigSendType" SG_ 1295 KL_Heizleistg_stat_erw 0;
BA_ "Fehlerwert" SG_ 2589283474 KL_Temp_vor_Verdampfer 127;
BA_ "GenSigSwitchedByIgnition" SG_ 2589283474 KL_Temp_vor_Verdampfer 0;
BA_ "GenSigStartValue" SG_ 2589283474 KL_Temp_vor_Verdampfer 126;
BA_ "GenSigSendType" SG_ 2589283474 KL_Temp_vor_Verdampfer 3;
BA_ "Fehlerwert" SG_ 2589283474 KL_Eps_Innen 255;
BA_ "GenSigSwitchedByIgnition" SG_ 2589283474 KL_Eps_Innen 0;
BA_ "GenSigStartValue" SG_ 2589283474 KL_Eps_Innen 254;
BA_ "GenSigSendType" SG_ 2589283474 KL_Eps_Innen 0;
BA_ "Fehlerwert" SG_ 2589283474 KL_Tempklappe_Fond_li 255;
BA_ "GenSigStartValue" SG_ 2589283474 KL_Tempklappe_Fond_li 254;
BA_ "GenSigSendType" SG_ 2589283474 KL_Tempklappe_Fond_li 0;
BA_ "Fehlerwert" SG_ 2589283474 KL_Tempklappe_Fond_re 255;
BA_ "GenSigStartValue" SG_ 2589283474 KL_Tempklappe_Fond_re 254;
BA_ "GenSigSendType" SG_ 2589283474 KL_Tempklappe_Fond_re 0;
BA_ "GenSigSwitchedByIgnition" SG_ 2463978659 KMP_Status_Spgfreiheit 0;
BA_ "GenSigSendType" SG_ 2463978659 KMP_Status_Spgfreiheit 3;
BA_ "GenSigSwitchedByIgnition" SG_ 2463978659 KMP_Warnung_Trockenlauf 0;
BA_ "GenSigSendType" SG_ 2463978659 KMP_Warnung_Trockenlauf 0;
BA_ "GenSigSwitchedByIgnition" SG_ 2463978659 KMP_Warnung_Uebertemperatur 0;
BA_ "GenSigSendType" SG_ 2463978659 KMP_Warnung_Uebertemperatur 0;
BA_ "GenSigSwitchedByIgnition" SG_ 2463978659 KMP_Ist_Spannung 0;
BA_ "GenSigSendType" SG_ 2463978659 KMP_Ist_Spannung 0;
BA_ "Fehlerwert" SG_ 2463978659 KMP_Fehler_Blockiert 1;
BA_ "GenSigSwitchedByIgnition" SG_ 2463978659 KMP_Fehler_Blockiert 0;
BA_ "GenSigSendType" SG_ 2463978659 KMP_Fehler_Blockiert 0;
BA_ "Fehlerwert" SG_ 2463978659 KMP_Fehler_elektrischer_Fehler 1;
BA_ "GenSigSwitchedByIgnition" SG_ 2463978659 KMP_Fehler_elektrischer_Fehler 0;
BA_ "GenSigSendType" SG_ 2463978659 KMP_Fehler_elektrischer_Fehler 0;
BA_ "Fehlerwert" SG_ 2463978659 KMP_Fehler_Ueberspannung_HV 1;
BA_ "GenSigSwitchedByIgnition" SG_ 2463978659 KMP_Fehler_Ueberspannung_HV 0;
BA_ "GenSigSendType" SG_ 2463978659 KMP_Fehler_Ueberspannung_HV 0;
BA_ "Fehlerwert" SG_ 2463978659 KMP_Fehler_Ueberspannung_12V 1;
BA_ "GenSigSwitchedByIgnition" SG_ 2463978659 KMP_Fehler_Ueberspannung_12V 0;
BA_ "GenSigSendType" SG_ 2463978659 KMP_Fehler_Ueberspannung_12V 0;
BA_ "Fehlerwert" SG_ 2463978659 KMP_Fehler_Uebertemperatur 1;
BA_ "GenSigSwitchedByIgnition" SG_ 2463978659 KMP_Fehler_Uebertemperatur 0;
BA_ "GenSigSendType" SG_ 2463978659 KMP_Fehler_Uebertemperatur 0;
BA_ "Fehlerwert" SG_ 2463978659 KMP_Fehler_Unterspannung_HV 1;
BA_ "GenSigSwitchedByIgnition" SG_ 2463978659 KMP_Fehler_Unterspannung_HV 0;
BA_ "GenSigSendType" SG_ 2463978659 KMP_Fehler_Unterspannung_HV 0;
BA_ "Fehlerwert" SG_ 2463978659 KMP_Fehler_Unterspannung_12V 1;
BA_ "GenSigSwitchedByIgnition" SG_ 2463978659 KMP_Fehler_Unterspannung_12V 0;
BA_ "GenSigSendType" SG_ 2463978659 KMP_Fehler_Unterspannung_12V 0;
BA_ "GenSigSwitchedByIgnition" SG_ 2463978659 KMP_Ist_Drehzahl 0;
BA_ "GenSigSendType" SG_ 2463978659 KMP_Ist_Drehzahl 0;
BA_ "GenSigSwitchedByIgnition" SG_ 2463978659 KMP_Error_NW_Timeout 0;
BA_ "GenSigSendType" SG_ 2463978659 KMP_Error_NW_Timeout 0;
BA_ "GenSigSwitchedByIgnition" SG_ 2463978659 KMP_Ist_Strom 0;
BA_ "GenSigSendType" SG_ 2463978659 KMP_Ist_Strom 0;
BA_ "GenSigSendType" SG_ 2549088399 AWC_KompSchutz 0;
BA_ "GenSigSendType" SG_ 2549088399 AWC_Abschaltstufe 0;
BA_ "GenSigSwitchedByIgnition" SG_ 2549088399 AWC_Transport_Mode 0;
BA_ "GenSigSendType" SG_ 2549088399 AWC_Transport_Mode 0;
BA_ "GenSigSwitchedByIgnition" SG_ 2549088399 AWC_Nachlauftyp 0;
BA_ "GenSigStartValue" SG_ 2549088399 AWC_Nachlauftyp 2;
BA_ "GenSigSendType" SG_ 2549088399 AWC_Nachlauftyp 0;
BA_ "GenSigSwitchedByIgnition" SG_ 2549088399 AWC_SNI 0;
BA_ "GenSigStartValue" SG_ 2549088399 AWC_SNI 143;
BA_ "GenSigSendType" SG_ 2549088399 AWC_SNI 0;
BA_ "GenSigSwitchedByIgnition" SG_ 2549088399 KN_AWC_ECUKnockOutTimer 0;
BA_ "GenSigSendType" SG_ 2549088399 KN_AWC_ECUKnockOutTimer 0;
BA_ "GenSigSwitchedByIgnition" SG_ 2549088399 KN_AWC_BusKnockOut 0;
BA_ "GenSigSendType" SG_ 2549088399 KN_AWC_BusKnockOut 0;
BA_ "GenSigSwitchedByIgnition" SG_ 2549088399 KN_AWC_BusKnockOutTimer 0;
BA_ "GenSigSendType" SG_ 2549088399 KN_AWC_BusKnockOutTimer 0;
BA_ "GenSigSwitchedByIgnition" SG_ 2549088399 NM_AWC_Wakeup 0;
BA_ "NWM-WakeupAllowed" SG_ 2549088399 NM_AWC_Wakeup 1;
BA_ "GenSigSendType" SG_ 2549088399 NM_AWC_Wakeup 0;
BA_ "GenSigSwitchedByIgnition" SG_ 2549088399 KN_AWC_ECUKnockOut 0;
BA_ "GenSigSendType" SG_ 2549088399 KN_AWC_ECUKnockOut 0;
BA_ "GenSigSwitchedByIgnition" SG_ 2549088399 AWC_Lokalaktiv 0;
BA_ "GenSigSendType" SG_ 2549088399 AWC_Lokalaktiv 0;
BA_ "GenSigSendType" SG_ 2549088399 AWC_Subsystemaktiv 0;
BA_ "GenSigSwitchedByIgnition" SG_ 2549088399 AWC_KD_Fehler 0;
BA_ "GenSigSendType" SG_ 2549088399 AWC_KD_Fehler 0;
BA_ "GenSigSendType" SG_ 2549088430 BattRegelung_KompSchutz 0;
BA_ "GenSigSendType" SG_ 2549088430 BattRegelung_Abschaltstufe 0;
BA_ "GenSigSendType" SG_ 2549088430 BattRegelung_Transport_Mode 0;
BA_ "GenSigSwitchedByIgnition" SG_ 2549088430 BattRegelung_Nachlauftyp 0;
BA_ "GenSigStartValue" SG_ 2549088430 BattRegelung_Nachlauftyp 2;
BA_ "GenSigSendType" SG_ 2549088430 BattRegelung_Nachlauftyp 0;
BA_ "GenSigSwitchedByIgnition" SG_ 2549088430 BattRegelung_SNI 0;
BA_ "GenSigStartValue" SG_ 2549088430 BattRegelung_SNI 174;
BA_ "GenSigSendType" SG_ 2549088430 BattRegelung_SNI 0;
BA_ "GenSigSwitchedByIgnition" SG_ 2549088430 NM_Battregelung_Wakeup 0;
BA_ "GenSigSendType" SG_ 2549088430 NM_Battregelung_Wakeup 0;
BA_ "GenSigSwitchedByIgnition" SG_ 2549088430 BMS_NV_Lokalaktiv 0;
BA_ "GenSigSendType" SG_ 2549088430 BMS_NV_Lokalaktiv 0;
BA_ "GenSigSwitchedByIgnition" SG_ 2549088430 BattRegelung_KD_Fehler 0;
BA_ "GenSigSendType" SG_ 2549088430 BattRegelung_KD_Fehler 0;
BA_ "GenSigSwitchedByIgnition" SG_ 2549088412 BMS_MV_KompSchutz 0;
BA_ "GenSigSendType" SG_ 2549088412 BMS_MV_KompSchutz 0;
BA_ "GenSigSwitchedByIgnition" SG_ 2549088412 BMS_MV_Abschaltstufe 0;
BA_ "GenSigSendType" SG_ 2549088412 BMS_MV_Abschaltstufe 0;
BA_ "GenSigSwitchedByIgnition" SG_ 2549088412 BMS_MV_Transport_Mode 0;
BA_ "GenSigSendType" SG_ 2549088412 BMS_MV_Transport_Mode 0;
BA_ "GenSigSwitchedByIgnition" SG_ 2549088412 BMS_MV_Nachlauftyp 0;
BA_ "GenSigStartValue" SG_ 2549088412 BMS_MV_Nachlauftyp 2;
BA_ "GenSigSendType" SG_ 2549088412 BMS_MV_Nachlauftyp 0;
BA_ "GenSigSwitchedByIgnition" SG_ 2549088412 BMS_MV_SNI 0;
BA_ "GenSigStartValue" SG_ 2549088412 BMS_MV_SNI 156;
BA_ "GenSigSendType" SG_ 2549088412 BMS_MV_SNI 0;
BA_ "GenSigSwitchedByIgnition" SG_ 2549088412 NM_BMS_MV_Wakeup 0;
BA_ "NWM-WakeupAllowed" SG_ 2549088412 NM_BMS_MV_Wakeup 1;
BA_ "GenSigSendType" SG_ 2549088412 NM_BMS_MV_Wakeup 0;
BA_ "GenSigSwitchedByIgnition" SG_ 2549088412 BMS_MV_Lokalaktiv 0;
BA_ "GenSigSendType" SG_ 2549088412 BMS_MV_Lokalaktiv 0;
BA_ "GenSigSwitchedByIgnition" SG_ 2549088412 BMS_MV_Subsystemaktiv 0;
BA_ "GenSigSendType" SG_ 2549088412 BMS_MV_Subsystemaktiv 0;
BA_ "GenSigSwitchedByIgnition" SG_ 2549088412 BMS_MV_KD_Fehler 0;
BA_ "GenSigSendType" SG_ 2549088412 BMS_MV_KD_Fehler 0;
BA_ "GenSigSendType" SG_ 2549088321 DCDC_KompSchutz 0;
BA_ "GenSigSendType" SG_ 2549088321 DCDC_Abschaltstufe 0;
BA_ "GenSigSendType" SG_ 2549088321 DCDC_Transport_Mode 0;
BA_ "GenSigSwitchedByIgnition" SG_ 2549088321 DCDC_Nachlauftyp 0;
BA_ "GenSigStartValue" SG_ 2549088321 DCDC_Nachlauftyp 2;
BA_ "GenSigSendType" SG_ 2549088321 DCDC_Nachlauftyp 0;
BA_ "GenSigSwitchedByIgnition" SG_ 2549088321 DCDC_SNI 0;
BA_ "GenSigStartValue" SG_ 2549088321 DCDC_SNI 65;
BA_ "GenSigSendType" SG_ 2549088321 DCDC_SNI 0;
BA_ "GenSigSwitchedByIgnition" SG_ 2549088321 KN_DCDC_BusKnockOutTimer 0;
BA_ "GenSigSendType" SG_ 2549088321 KN_DCDC_BusKnockOutTimer 0;
BA_ "GenSigSwitchedByIgnition" SG_ 2549088321 NM_DCDC_Wakeup 0;
BA_ "NWM-WakeupAllowed" SG_ 2549088321 NM_DCDC_Wakeup 1;
BA_ "GenSigSendType" SG_ 2549088321 NM_DCDC_Wakeup 0;
BA_ "GenSigSwitchedByIgnition" SG_ 2549088321 NMH_DCDC_Lokalaktiv 0;
BA_ "GenSigSendType" SG_ 2549088321 NMH_DCDC_Lokalaktiv 0;
BA_ "GenSigSendType" SG_ 2549088321 NMH_DCDC_Subsystemaktiv 0;
BA_ "GenSigSwitchedByIgnition" SG_ 2549088321 DCDC_KD_Fehler 0;
BA_ "GenSigSendType" SG_ 2549088321 DCDC_KD_Fehler 0;
BA_ "GenSigSendType" SG_ 2549088439 DCDC_HV_KompSchutz 0;
BA_ "GenSigSendType" SG_ 2549088439 DCDC_HV_Abschaltstufe 0;
BA_ "GenSigSendType" SG_ 2549088439 DCDC_HV_Transport_Mode 0;
BA_ "GenSigSwitchedByIgnition" SG_ 2549088439 DCDC_HV_Nachlauftyp 0;
BA_ "GenSigStartValue" SG_ 2549088439 DCDC_HV_Nachlauftyp 2;
BA_ "GenSigSendType" SG_ 2549088439 DCDC_HV_Nachlauftyp 0;
BA_ "GenSigSwitchedByIgnition" SG_ 2549088439 DCDC_HV_SNI 0;
BA_ "GenSigStartValue" SG_ 2549088439 DCDC_HV_SNI 183;
BA_ "GenSigSendType" SG_ 2549088439 DCDC_HV_SNI 0;
BA_ "GenSigSwitchedByIgnition" SG_ 2549088439 DCDC_HV_ECUKnockOutTimer 0;
BA_ "GenSigSendType" SG_ 2549088439 DCDC_HV_ECUKnockOutTimer 0;
BA_ "GenSigSwitchedByIgnition" SG_ 2549088439 DCDC_HV_BusKnockOut 0;
BA_ "GenSigSendType" SG_ 2549088439 DCDC_HV_BusKnockOut 0;
BA_ "GenSigSwitchedByIgnition" SG_ 2549088439 DCDC_HV_BusKnockOutTimer 0;
BA_ "GenSigSendType" SG_ 2549088439 DCDC_HV_BusKnockOutTimer 0;
BA_ "GenSigSwitchedByIgnition" SG_ 2549088439 NM_DCDC_HV_Wakeup 0;
BA_ "NWM-WakeupAllowed" SG_ 2549088439 NM_DCDC_HV_Wakeup 1;
BA_ "GenSigSendType" SG_ 2549088439 NM_DCDC_HV_Wakeup 0;
BA_ "GenSigSwitchedByIgnition" SG_ 2549088439 DCDC_HV_ECUKnockOut 0;
BA_ "GenSigSendType" SG_ 2549088439 DCDC_HV_ECUKnockOut 0;
BA_ "GenSigSwitchedByIgnition" SG_ 2549088439 DCDC_HV_Lokalaktiv 0;
BA_ "GenSigSendType" SG_ 2549088439 DCDC_HV_Lokalaktiv 0;
BA_ "GenSigSwitchedByIgnition" SG_ 2549088439 DCDC_HV_KD_Fehler 0;
BA_ "GenSigSendType" SG_ 2549088439 DCDC_HV_KD_Fehler 0;
BA_ "GenSigSendType" SG_ 2549088455 DCDC_HV_02_KompSchutz 0;
BA_ "GenSigSendType" SG_ 2549088455 DCDC_HV_02_Abschaltstufe 0;
BA_ "GenSigSwitchedByIgnition" SG_ 2549088455 DCDC_HV_02_Transport_Mode 0;
BA_ "GenSigSendType" SG_ 2549088455 DCDC_HV_02_Transport_Mode 0;
BA_ "GenSigSwitchedByIgnition" SG_ 2549088455 DCDC_HV_02_Nachlauftyp 0;
BA_ "GenSigStartValue" SG_ 2549088455 DCDC_HV_02_Nachlauftyp 2;
BA_ "GenSigSendType" SG_ 2549088455 DCDC_HV_02_Nachlauftyp 0;
BA_ "GenSigSwitchedByIgnition" SG_ 2549088455 DCDC_HV_02_SNI 0;
BA_ "GenSigStartValue" SG_ 2549088455 DCDC_HV_02_SNI 199;
BA_ "GenSigSendType" SG_ 2549088455 DCDC_HV_02_SNI 0;
BA_ "GenSigSwitchedByIgnition" SG_ 2549088455 KN_DCDC_HV_02_ECUKnockOutTimer 0;
BA_ "GenSigSendType" SG_ 2549088455 KN_DCDC_HV_02_ECUKnockOutTimer 0;
BA_ "GenSigSwitchedByIgnition" SG_ 2549088455 KN_DCDC_HV_02_BusKnockOut 0;
BA_ "GenSigSendType" SG_ 2549088455 KN_DCDC_HV_02_BusKnockOut 0;
BA_ "GenSigSwitchedByIgnition" SG_ 2549088455 KN_DCDC_HV_02_BusKnockOutTimer 0;
BA_ "GenSigSendType" SG_ 2549088455 KN_DCDC_HV_02_BusKnockOutTimer 0;
BA_ "GenSigSwitchedByIgnition" SG_ 2549088455 NM_DCDC_HV_02_Wakeup 0;
BA_ "GenSigSendType" SG_ 2549088455 NM_DCDC_HV_02_Wakeup 0;
BA_ "GenSigSwitchedByIgnition" SG_ 2549088455 KN_DCDC_HV_02_ECUKnockOut 0;
BA_ "GenSigSendType" SG_ 2549088455 KN_DCDC_HV_02_ECUKnockOut 0;
BA_ "GenSigSwitchedByIgnition" SG_ 2549088455 NM_DCDC_HV_02_Lokalaktiv 0;
BA_ "GenSigSendType" SG_ 2549088455 NM_DCDC_HV_02_Lokalaktiv 0;
BA_ "GenSigSwitchedByIgnition" SG_ 2549088455 DCDC_HV_02_KD_Fehler 0;
BA_ "GenSigSendType" SG_ 2549088455 DCDC_HV_02_KD_Fehler 0;
BA_REL_ "GenSigTimeoutTime" BU_SG_REL_ Gateway SG_ 2463978610 HVLM_RtmWarnLadeverbindung 5000;
BA_REL_ "GenSigTimeoutTime" BU_SG_REL_ Gateway_PAG SG_ 2463978610 HVLM_RtmWarnLadeverbindung 5000;
BA_REL_ "GenSigTimeoutTime" BU_SG_REL_ Gateway SG_ 2463978610 HVLM_RtmWarnLadesystem 5000;
BA_REL_ "GenSigTimeoutTime" BU_SG_REL_ Gateway_PAG SG_ 2463978610 HVLM_RtmWarnLadesystem 5000;
BA_REL_ "GenSigTimeoutTime" BU_SG_REL_ Gateway SG_ 2463978610 HVLM_RtmWarnLadestatus 5000;
BA_REL_ "GenSigTimeoutTime" BU_SG_REL_ Gateway_PAG SG_ 2463978610 HVLM_RtmWarnLadestatus 5000;
BA_REL_ "GenSigTimeoutTime" BU_SG_REL_ Gateway SG_ 2463978610 HVLM_RtmWarnLadeKommunikation 5000;
BA_REL_ "GenSigTimeoutTime" BU_SG_REL_ Gateway_PAG SG_ 2463978610 HVLM_RtmWarnLadeKommunikation 5000;
BA_REL_ "GenSigTimeoutTime" BU_SG_REL_ DCDC_HV_02 SG_ 2463978641 HVLM_11_CRC 1000;
BA_REL_ "GenSigTimeoutTime" BU_SG_REL_ DCDC_HV_02 SG_ 2463978641 HVLM_11_BZ 1000;
BA_REL_ "GenSigTimeoutTime" BU_SG_REL_ DCDC_HV_02 SG_ 2463978641 HVLM_HVLB_SollSpannung_HVLS 1000;
BA_REL_ "GenSigTimeoutTime" BU_SG_REL_ DCDC_HV_02 SG_ 2463978641 HVLM_HVLB_Status 1000;
BA_REL_ "GenSigTimeoutTime" BU_SG_REL_ DCDC_HV_02 SG_ 2463978641 HVLM_HVLB_SollModus 1000;
BA_REL_ "GenSigTimeoutTime" BU_SG_REL_ AWC SG_ 2589283661 HVLM_PlanAnfr_Leistung 5000;
BA_REL_ "GenSigTimeoutTime" BU_SG_REL_ DCDC_HV_02 SG_ 2589283661 HVLM_PlanAnfr_Leistung 5000;
BA_REL_ "GenSigTimeoutTime" BU_SG_REL_ TME SG_ 2589283661 HVLM_PlanAnfr_Leistung 5000;
BA_REL_ "GenSigTimeoutTime" BU_SG_REL_ AWC SG_ 2589283661 HVLM_PlanAnfr_Zaehler 5000;
BA_REL_ "GenSigTimeoutTime" BU_SG_REL_ DCDC_HV_02 SG_ 2589283661 HVLM_PlanAnfr_Zaehler 5000;
BA_REL_ "GenSigTimeoutTime" BU_SG_REL_ TME SG_ 2589283661 HVLM_PlanAnfr_Zaehler 5000;
BA_REL_ "GenSigTimeoutTime" BU_SG_REL_ AWC SG_ 2589283661 HVLM_PlanAnfr_Dauer 5000;
BA_REL_ "GenSigTimeoutTime" BU_SG_REL_ DCDC_HV_02 SG_ 2589283661 HVLM_PlanAnfr_Dauer 5000;
BA_REL_ "GenSigTimeoutTime" BU_SG_REL_ TME SG_ 2589283661 HVLM_PlanAnfr_Dauer 5000;
BA_REL_ "GenSigTimeoutTime" BU_SG_REL_ AWC SG_ 2589283661 HVLM_PlanAnfr_Ladeart 5000;
BA_REL_ "GenSigTimeoutTime" BU_SG_REL_ DCDC_HV_02 SG_ 2589283661 HVLM_PlanAnfr_Ladeart 5000;
BA_REL_ "GenSigTimeoutTime" BU_SG_REL_ TME SG_ 2589283661 HVLM_PlanAnfr_Ladeart 5000;
BA_REL_ "GenSigTimeoutTime" BU_SG_REL_ BMC_MLBevo SG_ 2589283661 HVLM_EnergieAnfr_SocStart 5000;
BA_REL_ "GenSigTimeoutTime" BU_SG_REL_ BMC_MLBevo SG_ 2589283661 HVLM_EnergieAnfr_SocZiel 5000;
BA_REL_ "GenSigTimeoutTime" BU_SG_REL_ BMC_MLBevo SG_ 2589283661 HVLM_EnergieAnfr_Zaehler 5000;
BA_REL_ "GenSigTimeoutTime" BU_SG_REL_ BMC_MLBevo SG_ 2589283661 HVLM_LadegrenzeAnfr_Leistung 5000;
BA_REL_ "GenSigTimeoutTime" BU_SG_REL_ BMC_MLBevo SG_ 2589283661 HVLM_LadegrenzeAnfr_Zaehler 5000;
BA_REL_ "GenSigTimeoutTime" BU_SG_REL_ FCU_MLBevo_FCEV SG_ 497 KY_Auf_Taste 5000;
BA_REL_ "GenSigTimeoutTime" BU_SG_REL_ Ladegeraet_Konzern SG_ 497 KY_Auf_Taste 5000;
BA_REL_ "GenSigTimeoutTime" BU_SG_REL_ Ladegeraet_Konzern SG_ 497 KY_Zu_Taste 5000;
BA_REL_ "GenSigTimeoutTime" BU_SG_REL_ FCU_MLBevo_FCEV SG_ 497 KY_FT_Entriegelung_Autorisiert 5000;
BA_REL_ "GenSigTimeoutTime" BU_SG_REL_ FCU_MLBevo_FCEV SG_ 497 KY_BT_Entriegelung_Autorisiert 5000;
BA_REL_ "GenSigTimeoutTime" BU_SG_REL_ FCU_MLBevo_FCEV SG_ 497 KY_HFS_Entriegelung_Autorisiert 5000;
BA_REL_ "GenSigTimeoutTime" BU_SG_REL_ FCU_MLBevo_FCEV SG_ 497 KY_HBFS_Entriegelung_Autorisiert 5000;
BA_REL_ "GenSigTimeoutTime" BU_SG_REL_ FCU_MLBevo_FCEV SG_ 497 KY_HD_Entriegelung_Autorisiert 5000;
BA_REL_ "GenSigTimeoutTime" BU_SG_REL_ Ladegeraet_Konzern SG_ 497 KY_LKL_1_Autorisierung 5000;
BA_REL_ "GenSigTimeoutTime" BU_SG_REL_ Ladegeraet_Konzern SG_ 497 KY_LKL_2_Autorisierung 5000;
BA_REL_ "GenSigTimeoutTime" BU_SG_REL_ BMC_MLBevo SG_ 960 Klemmen_Status_01_CRC 1000;
BA_REL_ "GenSigTimeoutTime" BU_SG_REL_ DCDC_HV_02 SG_ 960 Klemmen_Status_01_CRC 1000;
BA_REL_ "GenSigTimeoutTime" BU_SG_REL_ Ladegeraet_2 SG_ 960 Klemmen_Status_01_CRC 1000;
BA_REL_ "GenSigTimeoutTime" BU_SG_REL_ Ladegeraet_Konzern SG_ 960 Klemmen_Status_01_CRC 1000;
BA_REL_ "GenSigTimeoutTime" BU_SG_REL_ BMC_MLBevo SG_ 960 Klemmen_Status_01_BZ 1000;
BA_REL_ "GenSigTimeoutTime" BU_SG_REL_ DCDC_HV_02 SG_ 960 Klemmen_Status_01_BZ 1000;
BA_REL_ "GenSigTimeoutTime" BU_SG_REL_ Ladegeraet_2 SG_ 960 Klemmen_Status_01_BZ 1000;
BA_REL_ "GenSigTimeoutTime" BU_SG_REL_ Ladegeraet_Konzern SG_ 960 Klemmen_Status_01_BZ 1000;
BA_REL_ "GenSigTimeoutTime" BU_SG_REL_ Ladegeraet_2 SG_ 960 ZAS_Kl_S 1000;
BA_REL_ "GenSigTimeoutTime" BU_SG_REL_ Ladegeraet_Konzern SG_ 960 ZAS_Kl_S 1000;
BA_REL_ "GenSigTimeoutTime" BU_SG_REL_ TME SG_ 960 ZAS_Kl_S 1000;
BA_REL_ "GenSigTimeoutTime" BU_SG_REL_ AWC SG_ 960 ZAS_Kl_15 1000;
BA_REL_ "GenSigTimeoutTime" BU_SG_REL_ BMC_MLBevo SG_ 960 ZAS_Kl_15 1000;
BA_REL_ "GenSigTimeoutTime" BU_SG_REL_ BMS_NV SG_ 960 ZAS_Kl_15 1000;
BA_REL_ "GenSigTimeoutTime" BU_SG_REL_ DCDC_800V_PAG SG_ 960 ZAS_Kl_15 1000;
BA_REL_ "GenSigTimeoutTime" BU_SG_REL_ DCDC_HV SG_ 960 ZAS_Kl_15 1000;
BA_REL_ "GenSigTimeoutTime" BU_SG_REL_ DCDC_HV_02 SG_ 960 ZAS_Kl_15 1000;
BA_REL_ "GenSigTimeoutTime" BU_SG_REL_ DCDC_IHEV SG_ 960 ZAS_Kl_15 1000;
BA_REL_ "GenSigTimeoutTime" BU_SG_REL_ FCU_MLBevo_FCEV SG_ 960 ZAS_Kl_15 1000;
BA_REL_ "GenSigTimeoutTime" BU_SG_REL_ Ladegeraet_2 SG_ 960 ZAS_Kl_15 1000;
BA_REL_ "GenSigTimeoutTime" BU_SG_REL_ Ladegeraet_Konzern SG_ 960 ZAS_Kl_15 1000;
BA_REL_ "GenSigTimeoutTime" BU_SG_REL_ TME SG_ 960 ZAS_Kl_15 1000;
BA_REL_ "GenSigTimeoutTime" BU_SG_REL_ AWC SG_ 960 ZAS_Kl_50_Startanforderung 1000;
BA_REL_ "GenSigTimeoutTime" BU_SG_REL_ BMC_MLBevo SG_ 960 ZAS_Kl_50_Startanforderung 1000;
BA_REL_ "GenSigTimeoutTime" BU_SG_REL_ FCU_MLBevo_FCEV SG_ 960 ZAS_Kl_50_Startanforderung 1000;
BA_REL_ "GenSigTimeoutTime" BU_SG_REL_ Ladegeraet_2 SG_ 960 ZAS_Kl_50_Startanforderung 1000;
BA_REL_ "GenSigTimeoutTime" BU_SG_REL_ Ladegeraet_Konzern SG_ 960 ZAS_Kl_50_Startanforderung 1000;
BA_REL_ "GenSigTimeoutTime" BU_SG_REL_ TME SG_ 960 ZAS_Kl_50_Startanforderung 1000;
BA_REL_ "GenSigTimeoutTime" BU_SG_REL_ TME SG_ 1646 KL_Umluft_Taste 5000;
BA_REL_ "GenSigTimeoutTime" BU_SG_REL_ TME SG_ 1646 KL_Geblaese_Fond_Status 5000;
BA_REL_ "GenSigTimeoutTime" BU_SG_REL_ TME SG_ 1646 KL_Geblaese_Status 5000;
BA_REL_ "GenSigTimeoutTime" BU_SG_REL_ TME SG_ 1646 KL_BCmE_Livetip_Freigabe 5000;
BA_REL_ "GenSigTimeoutTime" BU_SG_REL_ TME SG_ 1646 KL_HYB_ASV_hinten_schliessen_Anf 5000;
BA_REL_ "GenSigTimeoutTime" BU_SG_REL_ TME SG_ 1646 KL_HYB_ASV_vorne_schliessen_Anf 5000;
BA_REL_ "GenSigTimeoutTime" BU_SG_REL_ TME SG_ 1646 KL_ErwVK_Anf 5000;
BA_REL_ "GenSigTimeoutTime" BU_SG_REL_ TME SG_ 1646 KL_Innen_Temp 5000;
BA_REL_ "GenSigTimeoutTime" BU_SG_REL_ TME SG_ 1649 KL_ZZ_Minute 5000;
BA_REL_ "GenSigTimeoutTime" BU_SG_REL_ TME SG_ 1649 KL_ZZ_Status_Timer 5000;
BA_REL_ "GenSigTimeoutTime" BU_SG_REL_ TME SG_ 1649 KL_ZZ_Monat 5000;
BA_REL_ "GenSigTimeoutTime" BU_SG_REL_ TME SG_ 1649 KL_ZZ_Stunde 5000;
BA_REL_ "GenSigTimeoutTime" BU_SG_REL_ TME SG_ 1649 KL_ZZ_Betriebsmodus 5000;
BA_REL_ "GenSigTimeoutTime" BU_SG_REL_ TME SG_ 1649 KL_ZZ_Tag 5000;
BA_REL_ "GenSigTimeoutTime" BU_SG_REL_ TME SG_ 949 KL_Drehz_Anh 1000;
BA_REL_ "GenSigTimeoutTime" BU_SG_REL_ TME SG_ 949 KL_Vorwarn_Komp_ein 1000;
BA_REL_ "GenSigTimeoutTime" BU_SG_REL_ TME SG_ 949 KL_AC_Schalter 1000;
BA_REL_ "GenSigTimeoutTime" BU_SG_REL_ TME SG_ 949 KL_Komp_Moment_alt 1000;
BA_REL_ "GenSigTimeoutTime" BU_SG_REL_ TME SG_ 949 KL_Zustand 1000;
BA_REL_ "GenSigTimeoutTime" BU_SG_REL_ TME SG_ 949 KL_Charisma_FahrPr 1000;
BA_REL_ "GenSigTimeoutTime" BU_SG_REL_ TME SG_ 949 KL_Charisma_Status 1000;
BA_REL_ "GenSigTimeoutTime" BU_SG_REL_ TME SG_ 949 KL_Last_Kompr 1000;
BA_REL_ "GenSigTimeoutTime" BU_SG_REL_ TME SG_ 949 KL_Thermomanagement 1000;
BA_REL_ "GenSigTimeoutTime" BU_SG_REL_ TME SG_ 949 KL_StartStopp_Info 1000;
BA_REL_ "GenSigTimeoutTime" BU_SG_REL_ TME SG_ 949 KL_Anf_KL 1000;
BA_REL_ "GenSigTimeoutTime" BU_SG_REL_ TME SG_ 949 KL_el_Zuheizer_Stufe 1000;
BA_REL_ "GenSigTimeoutTime" BU_SG_REL_ TME SG_ 1640 KL_Zuheizer_Freigabe 2000;
BA_REL_ "GenSigTimeoutTime" BU_SG_REL_ TME SG_ 1640 KL_Beschlagsgefahr 2000;
BA_REL_ "GenSigTimeoutTime" BU_SG_REL_ TME SG_ 1640 KL_SIH_Soll_li 2000;
BA_REL_ "GenSigTimeoutTime" BU_SG_REL_ TME SG_ 1640 KL_SIH_Soll_re 2000;
BA_REL_ "GenSigTimeoutTime" BU_SG_REL_ TME SG_ 1640 KL_SIL_Soll_li 2000;
BA_REL_ "GenSigTimeoutTime" BU_SG_REL_ TME SG_ 1640 KL_SIL_Soll_re 2000;
BA_REL_ "GenSigTimeoutTime" BU_SG_REL_ TME SG_ 1640 KL_Kompressorstrom_soll 2000;
BA_REL_ "GenSigTimeoutTime" BU_SG_REL_ TME SG_ 1640 KL_Umluftklappe_Status 2000;
BA_REL_ "GenSigTimeoutTime" BU_SG_REL_ TME SG_ 1441 KL_Temp_Soll_hl 5000;
BA_REL_ "GenSigTimeoutTime" BU_SG_REL_ TME SG_ 1441 KL_Temp_Soll_hr 5000;
BA_REL_ "GenSigTimeoutTime" BU_SG_REL_ TME SG_ 1441 KL_Temp_Soll_vl 5000;
BA_REL_ "GenSigTimeoutTime" BU_SG_REL_ TME SG_ 1441 KL_Temp_Soll_vr 5000;
BA_REL_ "GenSigTimeoutTime" BU_SG_REL_ TME SG_ 1441 KL_Frischluftklappe_Status 5000;
BA_REL_ "GenSigTimeoutTime" BU_SG_REL_ TME SG_ 2589283469 KL_Verdampferleistung 5000;
BA_REL_ "GenSigTimeoutTime" BU_SG_REL_ Ladegeraet_Konzern SG_ 2589283469 KL_VK_Anf 5000;
BA_REL_ "GenSigTimeoutTime" BU_SG_REL_ TME SG_ 2589283469 KL_VK_Anf 5000;
BA_REL_ "GenSigTimeoutTime" BU_SG_REL_ TME SG_ 2589283469 KL_Verdampferleistung_Faktor 5000;
BA_REL_ "GenSigTimeoutTime" BU_SG_REL_ TME SG_ 2589283469 KL_Vorkond_Strategie 5000;
BA_REL_ "GenSigTimeoutTime" BU_SG_REL_ TME SG_ 2589283469 KL_Tempklappe_re 5000;
BA_REL_ "GenSigTimeoutTime" BU_SG_REL_ TME SG_ 2589283469 KL_Tempklappe_li 5000;
BA_REL_ "GenSigTimeoutTime" BU_SG_REL_ TME SG_ 2589283469 KL_Tempklappe_Fond 5000;
BA_REL_ "GenSigTimeoutTime" BU_SG_REL_ TME SG_ 2589283469 KL_Kuehllstg_Delta_Eingriff 5000;
BA_REL_ "GenSigTimeoutTime" BU_SG_REL_ TME SG_ 2589283469 KL_Heizlstg_Delta_Eingriff 5000;
BA_REL_ "GenSigTimeoutTime" BU_SG_REL_ Ladegeraet_Konzern SG_ 2589283621 KL_NV_Energie_Anf 5000;
BA_REL_ "GenSigTimeoutTime" BU_SG_REL_ TME SG_ 2589283621 KL_NV_Energie_Anf 5000;
BA_REL_ "GenSigTimeoutTime" BU_SG_REL_ TME SG_ 2589283621 KL_ECO_PRO_Aktiv 5000;
BA_REL_ "GenSigTimeoutTime" BU_SG_REL_ TME SG_ 2589283621 KL_QBit_Sonnenintensitaet 5000;
BA_REL_ "GenSigTimeoutTime" BU_SG_REL_ TME SG_ 2589283621 KL_ACmax_Aktiv 5000;
BA_REL_ "GenSigTimeoutTime" BU_SG_REL_ TME SG_ 2589283621 KL_Defrost_Aktiv 5000;
BA_REL_ "GenSigTimeoutTime" BU_SG_REL_ TME SG_ 2589283621 KL_ECO_Aktiv 5000;
BA_REL_ "GenSigTimeoutTime" BU_SG_REL_ TME SG_ 2589283621 KL_Status_Klimastil 5000;
BA_REL_ "GenSigTimeoutTime" BU_SG_REL_ TME SG_ 2589283621 KL_Kundeneingriff_Geblaese 5000;
BA_REL_ "GenSigTimeoutTime" BU_SG_REL_ TME SG_ 2589283621 KL_Thermischer_Bedarf 5000;
BA_REL_ "GenSigTimeoutTime" BU_SG_REL_ TME SG_ 2589283621 KL_Eps_Innen 5000;
BA_REL_ "GenSigTimeoutTime" BU_SG_REL_ TME SG_ 2589283621 KL_Sonnenintensitaet 5000;
BA_REL_ "GenSigTimeoutTime" BU_SG_REL_ TME SG_ 2463978701 KL_Temp_Soll_vr_Prognose 1000;
BA_REL_ "GenSigTimeoutTime" BU_SG_REL_ TME SG_ 2463978701 KL_AC_Schalter_Prognose 1000;
BA_REL_ "GenSigTimeoutTime" BU_SG_REL_ TME SG_ 2463978701 KL_Temp_Soll_vl_Prognose 1000;
BA_REL_ "GenSigTimeoutTime" BU_SG_REL_ TME SG_ 2463978701 KL_Sollklimamodus_FPR_1 1000;
BA_REL_ "GenSigTimeoutTime" BU_SG_REL_ TME SG_ 2463978701 KL_Temp_Soll_hr_Prognose 1000;
BA_REL_ "GenSigTimeoutTime" BU_SG_REL_ TME SG_ 2463978701 KL_Sollklimamodus_FPR_2 1000;
BA_REL_ "GenSigTimeoutTime" BU_SG_REL_ TME SG_ 2463978701 KL_Temp_Soll_hl_Prognose 1000;
BA_REL_ "GenSigTimeoutTime" BU_SG_REL_ TME SG_ 2463978701 KL_Sollklimamodus_FPR_3 1000;
BA_REL_ "GenSigTimeoutTime" BU_SG_REL_ TME SG_ 1712 FS_Taupunkt 5000;
BA_REL_ "GenSigTimeoutTime" BU_SG_REL_ TME SG_ 1712 FS_Temp_Scheibe 5000;
BA_REL_ "GenSigTimeoutTime" BU_SG_REL_ TME SG_ 1712 FS_Temp_Sensor 5000;
BA_REL_ "GenSigTimeoutTime" BU_SG_REL_ TME SG_ 1712 FS_Luftfeuchte_rel 5000;
BA_REL_ "GenSigTimeoutTime" BU_SG_REL_ BMC_MLBevo SG_ 1505 BCM1_Aussen_Temp_ungef 2000;
BA_REL_ "GenSigTimeoutTime" BU_SG_REL_ BMS_NV SG_ 1505 BCM1_Aussen_Temp_ungef 2000;
BA_REL_ "GenSigTimeoutTime" BU_SG_REL_ FCU_MLBevo_FCEV SG_ 1505 BCM1_Aussen_Temp_ungef 2000;
BA_REL_ "GenSigTimeoutTime" BU_SG_REL_ Ladegeraet_Konzern SG_ 1505 BCM1_Aussen_Temp_ungef 2000;
BA_REL_ "GenSigTimeoutTime" BU_SG_REL_ TME SG_ 1505 BCM1_Aussen_Temp_ungef 2000;
BA_REL_ "GenSigTimeoutTime" BU_SG_REL_ TME SG_ 1505 BCM1_FStatus_Aussentemp_ungef 2000;
BA_REL_ "GenSigTimeoutTime" BU_SG_REL_ BMC_MLBevo SG_ 1505 BCM1_OBD_FStatus_ATemp 2000;
BA_REL_ "GenSigTimeoutTime" BU_SG_REL_ Ladegeraet_Konzern SG_ 1505 BCM1_OBD_FStatus_ATemp 2000;
BA_REL_ "GenSigTimeoutTime" BU_SG_REL_ TME SG_ 1505 BCM1_OBD_FStatus_ATemp 2000;
BA_REL_ "GenSigTimeoutTime" BU_SG_REL_ TME SG_ 1717 FSA_Taupunkt 5000;
BA_REL_ "GenSigTimeoutTime" BU_SG_REL_ TME SG_ 1717 FSA_Temp_Luft 5000;
BA_REL_ "GenSigTimeoutTime" BU_SG_REL_ TME SG_ 1717 FSA_Luftfeuchte_rel 5000;
BA_REL_ "GenSigTimeoutTime" BU_SG_REL_ TME SG_ 1717 FSA_Temp_Sensor 5000;
BA_REL_ "GenSigTimeoutTime" BU_SG_REL_ TME SG_ 1717 FSA_Sensorheizung_Status 5000;
BA_REL_ "GenSigTimeoutTime" BU_SG_REL_ TME SG_ 1513 DS_Kaeltemittel_P 2000;
BA_REL_ "GenSigTimeoutTime" BU_SG_REL_ TME SG_ 1513 DS_Status 2000;
BA_REL_ "GenSigTimeoutTime" BU_SG_REL_ TME SG_ 1295 KL_Kuehlenergie_instat_pred 1000;
BA_REL_ "GenSigTimeoutTime" BU_SG_REL_ TME SG_ 1295 KL_Heizenergie_instat_pred 1000;
BA_REL_ "GenSigTimeoutTime" BU_SG_REL_ TME SG_ 1295 KL_Leistungspriorisierung 1000;
BA_REL_ "GenSigTimeoutTime" BU_SG_REL_ TME SG_ 1295 KL_Verdampfertemperatur 1000;
BA_REL_ "GenSigTimeoutTime" BU_SG_REL_ TME SG_ 1295 KL_Heizbedarf 1000;
BA_REL_ "GenSigTimeoutTime" BU_SG_REL_ TME SG_ 1295 KL_Kuehlbedarf 1000;
BA_REL_ "GenSigTimeoutTime" BU_SG_REL_ TME SG_ 1295 KL_Kuehlleistg_stat_erw 1000;
BA_REL_ "GenSigTimeoutTime" BU_SG_REL_ TME SG_ 1295 KL_Heizleistg_stat_erw 1000;
BA_REL_ "GenSigTimeoutTime" BU_SG_REL_ TME SG_ 2589283474 KL_Temp_vor_Verdampfer 5000;
BA_REL_ "GenSigTimeoutTime" BU_SG_REL_ Gateway SG_ 2463978659 KMP_Status_Spgfreiheit 1000;
BA_REL_ "GenSigTimeoutTime" BU_SG_REL_ Gateway SG_ 2463978659 KMP_Ist_Spannung 1000;
BA_REL_ "GenSigTimeoutTime" BU_SG_REL_ TME SG_ 2463978659 KMP_Ist_Drehzahl 1000;
BA_REL_ "GenSigTimeoutTime" BU_SG_REL_ Gateway SG_ 2549088399 AWC_Nachlauftyp 5000;
BA_REL_ "GenSigTimeoutTime" BU_SG_REL_ Gateway_PAG SG_ 2549088399 AWC_Nachlauftyp 5000;
BA_REL_ "GenSigTimeoutTime" BU_SG_REL_ Gateway SG_ 2549088399 AWC_SNI 5000;
BA_REL_ "GenSigTimeoutTime" BU_SG_REL_ Gateway_PAG SG_ 2549088399 AWC_SNI 5000;
BA_REL_ "GenSigTimeoutTime" BU_SG_REL_ Gateway SG_ 2549088399 KN_AWC_ECUKnockOutTimer 5000;
BA_REL_ "GenSigTimeoutTime" BU_SG_REL_ Gateway_PAG SG_ 2549088399 KN_AWC_ECUKnockOutTimer 5000;
BA_REL_ "GenSigTimeoutTime" BU_SG_REL_ Gateway SG_ 2549088399 KN_AWC_BusKnockOut 5000;
BA_REL_ "GenSigTimeoutTime" BU_SG_REL_ Gateway_PAG SG_ 2549088399 KN_AWC_BusKnockOut 5000;
BA_REL_ "GenSigTimeoutTime" BU_SG_REL_ Gateway SG_ 2549088399 KN_AWC_BusKnockOutTimer 5000;
BA_REL_ "GenSigTimeoutTime" BU_SG_REL_ Gateway_PAG SG_ 2549088399 KN_AWC_BusKnockOutTimer 5000;
BA_REL_ "GenSigTimeoutTime" BU_SG_REL_ Gateway SG_ 2549088399 KN_AWC_ECUKnockOut 5000;
BA_REL_ "GenSigTimeoutTime" BU_SG_REL_ Gateway_PAG SG_ 2549088399 KN_AWC_ECUKnockOut 5000;
BA_REL_ "GenSigTimeoutTime" BU_SG_REL_ Gateway SG_ 2549088399 AWC_Lokalaktiv 5000;
BA_REL_ "GenSigTimeoutTime" BU_SG_REL_ Gateway_PAG SG_ 2549088399 AWC_Lokalaktiv 5000;
BA_REL_ "GenSigTimeoutTime" BU_SG_REL_ Gateway SG_ 2549088399 AWC_KD_Fehler 2500;
BA_REL_ "GenSigTimeoutTime" BU_SG_REL_ Gateway_PAG SG_ 2549088399 AWC_KD_Fehler 2500;
BA_REL_ "GenSigTimeoutTime" BU_SG_REL_ Gateway SG_ 2549088430 BattRegelung_Nachlauftyp 5000;
BA_REL_ "GenSigTimeoutTime" BU_SG_REL_ Gateway_PAG SG_ 2549088430 BattRegelung_Nachlauftyp 5000;
BA_REL_ "GenSigTimeoutTime" BU_SG_REL_ Gateway SG_ 2549088430 BattRegelung_SNI 5000;
BA_REL_ "GenSigTimeoutTime" BU_SG_REL_ Gateway_PAG SG_ 2549088430 BattRegelung_SNI 5000;
BA_REL_ "GenSigTimeoutTime" BU_SG_REL_ Gateway SG_ 2549088430 BMS_NV_Lokalaktiv 5000;
BA_REL_ "GenSigTimeoutTime" BU_SG_REL_ Gateway_PAG SG_ 2549088430 BMS_NV_Lokalaktiv 5000;
BA_REL_ "GenSigTimeoutTime" BU_SG_REL_ Gateway SG_ 2549088430 BattRegelung_KD_Fehler 2500;
BA_REL_ "GenSigTimeoutTime" BU_SG_REL_ Gateway_PAG SG_ 2549088430 BattRegelung_KD_Fehler 2500;
BA_REL_ "GenSigTimeoutTime" BU_SG_REL_ Gateway SG_ 2549088412 BMS_MV_Nachlauftyp 5000;
BA_REL_ "GenSigTimeoutTime" BU_SG_REL_ Gateway_PAG SG_ 2549088412 BMS_MV_Nachlauftyp 5000;
BA_REL_ "GenSigTimeoutTime" BU_SG_REL_ Gateway SG_ 2549088412 BMS_MV_SNI 5000;
BA_REL_ "GenSigTimeoutTime" BU_SG_REL_ Gateway_PAG SG_ 2549088412 BMS_MV_SNI 5000;
BA_REL_ "GenSigTimeoutTime" BU_SG_REL_ Gateway SG_ 2549088412 BMS_MV_Lokalaktiv 5000;
BA_REL_ "GenSigTimeoutTime" BU_SG_REL_ Gateway_PAG SG_ 2549088412 BMS_MV_Lokalaktiv 5000;
BA_REL_ "GenSigTimeoutTime" BU_SG_REL_ Gateway SG_ 2549088412 BMS_MV_Subsystemaktiv 5000;
BA_REL_ "GenSigTimeoutTime" BU_SG_REL_ Gateway_PAG SG_ 2549088412 BMS_MV_Subsystemaktiv 5000;
BA_REL_ "GenSigTimeoutTime" BU_SG_REL_ Gateway SG_ 2549088412 BMS_MV_KD_Fehler 2500;
BA_REL_ "GenSigTimeoutTime" BU_SG_REL_ Gateway_PAG SG_ 2549088412 BMS_MV_KD_Fehler 2500;
BA_REL_ "GenSigTimeoutTime" BU_SG_REL_ Gateway SG_ 2549088321 DCDC_Nachlauftyp 5000;
BA_REL_ "GenSigTimeoutTime" BU_SG_REL_ Gateway_PAG SG_ 2549088321 DCDC_Nachlauftyp 5000;
BA_REL_ "GenSigTimeoutTime" BU_SG_REL_ Gateway SG_ 2549088321 DCDC_SNI 5000;
BA_REL_ "GenSigTimeoutTime" BU_SG_REL_ Gateway_PAG SG_ 2549088321 DCDC_SNI 5000;
BA_REL_ "GenSigTimeoutTime" BU_SG_REL_ Gateway SG_ 2549088321 KN_DCDC_BusKnockOutTimer 5000;
BA_REL_ "GenSigTimeoutTime" BU_SG_REL_ Gateway_PAG SG_ 2549088321 KN_DCDC_BusKnockOutTimer 5000;
BA_REL_ "GenSigTimeoutTime" BU_SG_REL_ Gateway SG_ 2549088321 NMH_DCDC_Lokalaktiv 5000;
BA_REL_ "GenSigTimeoutTime" BU_SG_REL_ Gateway_PAG SG_ 2549088321 NMH_DCDC_Lokalaktiv 5000;
BA_REL_ "GenSigTimeoutTime" BU_SG_REL_ Gateway SG_ 2549088321 DCDC_KD_Fehler 2500;
BA_REL_ "GenSigTimeoutTime" BU_SG_REL_ Gateway_PAG SG_ 2549088321 DCDC_KD_Fehler 2500;
BA_REL_ "GenSigTimeoutTime" BU_SG_REL_ Gateway SG_ 2549088439 DCDC_HV_Nachlauftyp 5000;
BA_REL_ "GenSigTimeoutTime" BU_SG_REL_ Gateway_PAG SG_ 2549088439 DCDC_HV_Nachlauftyp 5000;
BA_REL_ "GenSigTimeoutTime" BU_SG_REL_ Gateway SG_ 2549088439 DCDC_HV_SNI 5000;
BA_REL_ "GenSigTimeoutTime" BU_SG_REL_ Gateway_PAG SG_ 2549088439 DCDC_HV_SNI 5000;
BA_REL_ "GenSigTimeoutTime" BU_SG_REL_ Gateway SG_ 2549088439 DCDC_HV_ECUKnockOutTimer 5000;
BA_REL_ "GenSigTimeoutTime" BU_SG_REL_ Gateway_PAG SG_ 2549088439 DCDC_HV_ECUKnockOutTimer 5000;
BA_REL_ "GenSigTimeoutTime" BU_SG_REL_ Gateway SG_ 2549088439 DCDC_HV_BusKnockOut 5000;
BA_REL_ "GenSigTimeoutTime" BU_SG_REL_ Gateway_PAG SG_ 2549088439 DCDC_HV_BusKnockOut 5000;
BA_REL_ "GenSigTimeoutTime" BU_SG_REL_ Gateway SG_ 2549088439 DCDC_HV_BusKnockOutTimer 5000;
BA_REL_ "GenSigTimeoutTime" BU_SG_REL_ Gateway_PAG SG_ 2549088439 DCDC_HV_BusKnockOutTimer 5000;
BA_REL_ "GenSigTimeoutTime" BU_SG_REL_ Gateway SG_ 2549088439 DCDC_HV_ECUKnockOut 5000;
BA_REL_ "GenSigTimeoutTime" BU_SG_REL_ Gateway_PAG SG_ 2549088439 DCDC_HV_ECUKnockOut 5000;
BA_REL_ "GenSigTimeoutTime" BU_SG_REL_ Gateway SG_ 2549088439 DCDC_HV_Lokalaktiv 5000;
BA_REL_ "GenSigTimeoutTime" BU_SG_REL_ Gateway_PAG SG_ 2549088439 DCDC_HV_Lokalaktiv 5000;
BA_REL_ "GenSigTimeoutTime" BU_SG_REL_ Gateway SG_ 2549088439 DCDC_HV_KD_Fehler 2500;
BA_REL_ "GenSigTimeoutTime" BU_SG_REL_ Gateway_PAG SG_ 2549088439 DCDC_HV_KD_Fehler 2500;
BA_REL_ "GenSigTimeoutTime" BU_SG_REL_ Gateway SG_ 2549088455 DCDC_HV_02_Nachlauftyp 5000;
BA_REL_ "GenSigTimeoutTime" BU_SG_REL_ Gateway_PAG SG_ 2549088455 DCDC_HV_02_Nachlauftyp 5000;
BA_REL_ "GenSigTimeoutTime" BU_SG_REL_ Gateway SG_ 2549088455 DCDC_HV_02_SNI 5000;
BA_REL_ "GenSigTimeoutTime" BU_SG_REL_ Gateway_PAG SG_ 2549088455 DCDC_HV_02_SNI 5000;
BA_REL_ "GenSigTimeoutTime" BU_SG_REL_ Gateway SG_ 2549088455 KN_DCDC_HV_02_ECUKnockOutTimer 5000;
BA_REL_ "GenSigTimeoutTime" BU_SG_REL_ Gateway_PAG SG_ 2549088455 KN_DCDC_HV_02_ECUKnockOutTimer 5000;
BA_REL_ "GenSigTimeoutTime" BU_SG_REL_ Gateway SG_ 2549088455 KN_DCDC_HV_02_BusKnockOut 5000;
BA_REL_ "GenSigTimeoutTime" BU_SG_REL_ Gateway_PAG SG_ 2549088455 KN_DCDC_HV_02_BusKnockOut 5000;
BA_REL_ "GenSigTimeoutTime" BU_SG_REL_ Gateway SG_ 2549088455 KN_DCDC_HV_02_BusKnockOutTimer 5000;
BA_REL_ "GenSigTimeoutTime" BU_SG_REL_ Gateway_PAG SG_ 2549088455 KN_DCDC_HV_02_BusKnockOutTimer 5000;
BA_REL_ "GenSigTimeoutTime" BU_SG_REL_ Gateway SG_ 2549088455 KN_DCDC_HV_02_ECUKnockOut 5000;
BA_REL_ "GenSigTimeoutTime" BU_SG_REL_ Gateway_PAG SG_ 2549088455 KN_DCDC_HV_02_ECUKnockOut 5000;
BA_REL_ "GenSigTimeoutTime" BU_SG_REL_ Gateway SG_ 2549088455 NM_DCDC_HV_02_Lokalaktiv 5000;
BA_REL_ "GenSigTimeoutTime" BU_SG_REL_ Gateway_PAG SG_ 2549088455 NM_DCDC_HV_02_Lokalaktiv 5000;
BA_REL_ "GenSigTimeoutTime" BU_SG_REL_ Gateway SG_ 2549088455 DCDC_HV_02_KD_Fehler 2500;
BA_REL_ "GenSigTimeoutTime" BU_SG_REL_ Gateway_PAG SG_ 2549088455 DCDC_HV_02_KD_Fehler 2500;
VAL_ 2463978610 HVLM_RtmWarnLadeverbindung 0 "kein_Fehler" 1 "Fehler_Stufe_1" 2 "Fehler_Stufe_2" 3 "Fehler_Stufe_3" 4 "reserviert" 5 "reserviert" 6 "reserviert" 7 "reserviert" ;
VAL_ 2463978610 HVLM_RtmWarnLadesystem 0 "kein_Fehler" 1 "Fehler_Stufe_1" 2 "Fehler_Stufe_2" 3 "Fehler_Stufe_3" 4 "reserviert" 5 "reserviert" 6 "reserviert" 7 "reserviert" ;
VAL_ 2463978610 HVLM_RtmWarnLadestatus 0 "kein_Fehler" 1 "Fehler_Stufe_1" 2 "Fehler_Stufe_2" 3 "Fehler_Stufe_3" 4 "reserviert" 5 "reserviert" 6 "reserviert" 7 "reserviert" ;
VAL_ 2463978610 HVLM_RtmWarnLadeKommunikation 0 "kein_Fehler" 1 "Fehler_Stufe_1" 2 "Fehler_Stufe_2" 3 "Fehler_Stufe_3" 4 "reserviert" 5 "reserviert" 6 "reserviert" 7 "reserviert" ;
VAL_ 2463978610 HVLM_Ladeanzeige_Anf 0 "Licht_Aus" 1 "Licht_An" ;
VAL_ 2463978610 HVLM_Ladeanzeige_Status 0 "Funktion_Aus" 1 "Funktion_Ein_ohne_SOC" 2 "Funktion_Ein_mit_SOC" 3 "Reserve" ;
VAL_ 2463978610 HVLM_Ladeanzeige_Intens_Heck 126 "Init" 127 "Fehler" ;
VAL_ 2463978610 HVLM_Ladeanzeige_Intens_Front 126 "Init" 127 "Fehler" ;
VAL_ 2463978641 HVLM_HVLB_SollSpannung_HVLS 4094 "Init" 4095 "Fehler" ;
VAL_ 2463978641 HVLM_HVLB_SollModus 0 "Standby" 1 "Laden_DC_ohneBoost" 2 "Laden_DC_mitBoost" 3 "Laden_AC" 4 "Notabschaltung" 5 "Laden_DC_ohneBoost_ohneVorladung" 6 "Laden_DC_mitBoost_ohneVorladung" 7 "Init" ;
VAL_ 2589283661 HVLM_PlanAnfr_Leistung 4094 "Init" 4095 "Fehler" ;
VAL_ 2589283661 HVLM_PlanAnfr_Zaehler 14 "Init" 15 "Fehler" ;
VAL_ 2589283661 HVLM_PlanAnfr_Dauer 1022 "Init" 1023 "Fehler" ;
VAL_ 2589283661 HVLM_PlanAnfr_Ladeart 0 "keine_Ladeart" 1 "AC_Laden" 2 "DC_Laden_ohne_Boost" 3 "DC_Laden_mit_Boost" 4 "AWC_Laden" 5 "Reserve" 6 "Init" 7 "Fehler" ;
VAL_ 2589283661 HVLM_EnergieAnfr_SocStart 126 "Init" 127 "Fehler" ;
VAL_ 2589283661 HVLM_EnergieAnfr_SocZiel 126 "Init" 127 "Fehler" ;
VAL_ 2589283661 HVLM_EnergieAnfr_Zaehler 14 "Init" 15 "Fehler" ;
VAL_ 2589283661 HVLM_LadegrenzeAnfr_Leistung 4094 "Init" 4095 "Fehler" ;
VAL_ 2589283661 HVLM_LadegrenzeAnfr_Zaehler 14 "Init" 15 "Fehler" ;
VAL_ 497 KY_IDG_in_Reichweite 0 "ausser_Reichweite_bzw_nicht_ermittelbar" 1 "innerhalb_Reichweite" ;
VAL_ 497 KY_Auf_Taste 0 "Taste_nicht_betaetigt" 1 "Oeffnentaste_betaetigt" ;
VAL_ 497 KY_HDF_Taste 0 "Taste_nicht_betaetigt" 1 "HDF_Taste_am_Funkschluessel_betaetigt" ;
VAL_ 497 KY_Panik_Taste 0 "Taste_nicht_betaetigt" 1 "Panik_Taste_am_Funkschluessel_betaetigt" ;
VAL_ 497 KY_Zu_Taste 0 "Taste_nicht_betaetigt" 1 "Zu_Taste_am_Funkschluessel_betaetigt" ;
VAL_ 497 KY_FT_Entriegelung_Autorisiert 0 "kein_Keylessschluessel_erkannt" 1 "Keyless_Schluessel_erkannt_und_authorisiert" ;
VAL_ 497 KY_FT_Verriegelung_Autorisiert 0 "kein_Verriegelungssensor_erkannt" 1 "Verriegelungssensor_erkannt_und_authorisiert" ;
VAL_ 497 KY_BT_Entriegelung_Autorisiert 0 "kein_Keylessschluessel_erkannt" 1 "Keyless_Schluessel_erkannt_und_authorisiert" ;
VAL_ 497 KY_BT_Verriegelung_Autorisiert 0 "kein_Verriegelungssensor_erkannt" 1 "Verriegelungssensor_erkannt_und_authorisiert" ;
VAL_ 497 KY_HFS_Entriegelung_Autorisiert 0 "kein_Keylessschluessel_erkannt" 1 "Keyless_Schluessel_erkannt_und_authorisiert" ;
VAL_ 497 KY_HFS_Verriegelung_Autorisiert 0 "kein_Verriegelungssensor_erkannt" 1 "Verriegelungssensor_erkannt_und_authorisiert" ;
VAL_ 497 KY_HBFS_Entriegelung_Autorisiert 0 "kein_Keylessschluessel_erkannt" 1 "Keyless_Schluessel_erkannt_und_authorisiert" ;
VAL_ 497 KY_HBFS_Verriegelung_Autorisiert 0 "kein_Verriegelungssensor_erkannt" 1 "Verriegelungssensor_erkannt_und_authorisiert" ;
VAL_ 497 KY_Front_Entr_Autorisiert 0 "kein_Keylessschluessel_erkannt" 1 "Keyless_Schluessel_erkannt_und_authorisiert" ;
VAL_ 497 KY_Front_Verr_Autorisiert 0 "kein_Verriegelungssensor_erkannt" 1 "Verriegelungssensor_erkannt_und_authorisiert" ;
VAL_ 497 KY_HD_Entriegelung_Autorisiert 0 "kein_Keylessschluessel_erkannt" 1 "Keyless_Schluessel_erkannt_und_authorisiert" ;
VAL_ 497 KY_HD_Verriegelung_Autorisiert 0 "nicht_autorisiert" 1 "autorisiert" ;
VAL_ 497 KY_Bereich 0 "Bereich_0" 1 "Bereich_1" 2 "Bereich_2" 3 "Bereich_3" 4 "Bereich_4" 5 "Bereich_5" 6 "Kein_Schluessel_gefunden" 7 "Init" ;
VAL_ 497 KY_Position 0 "Position_0" 1 "Postition_1" 2 "Postition_2" 3 "Postition_3" 4 "Postition_4" 6 "Kein_Schluessel_gefunden" 7 "Init" ;
VAL_ 497 Schluesselnr_Personalisierung 1 "Schluesselnummer_eins_aktiv" 2 "Schluesselnummer_zwei_aktiv" 3 "Schluesselnummer_drei_aktiv" 4 "Schluesselnummer_vier_aktiv" 5 "Schluesselnummer_fuenf_aktiv" 6 "Schluesselnummer_sechs_aktiv" 7 "Schluesselnummer_sieben_aktiv" 8 "Schluesselnummer_acht_aktiv" 14 "Init" 15 "Fehler" ;
VAL_ 497 FFB_FDF_Taste 0 "Taste_nicht_betaetigt" 1 "FDF_Taste_am_Funkschluessel_betaetigt" ;
VAL_ 497 FFB_Joker_Taste 0 "Taste_nicht_betaetigt" 1 "Joker_Taste_an_FFFB_betaetigt" ;
VAL_ 497 FFB_Park_Taste 0 "Taste_nicht_betaetigt" 1 "Park_Taste_betaetigt" ;
VAL_ 497 FFB_Remotestart_Taste 0 "Taste_nicht_betaetigt" 1 "Remotestart_Taste_betaetigt" ;
VAL_ 497 FBS_Aktivierung_Pilot_Parken 0 "keine_Funktionsaktivierung" 1 "Aktivierung_FFB_erkannt" ;
VAL_ 497 KY_Schluessel_im_Fzg 0 "Schluessel_nicht_im_Fahrzeug" 1 "Schluessel_im_Fahrzeug" ;
VAL_ 497 KY_EasyClose_Abbruch 0 "EasyClose_kein_Abbruch" 1 "EasyClose_Abbruch" ;
VAL_ 497 KY_EasyClose_Status 0 "Lampe_AUS" 1 "Lampe_EIN" 2 "Lampe_NORMAL" 3 "Lampe_HEKTIK" 4 "Akustik_Verweigerung" ;
VAL_ 497 KY_HD_Auffahrt 0 "keine_Anforderung" 1 "HD_Auffahrt_angefordert" ;
VAL_ 497 KY_HD_Zufahrt 0 "keine_Anforderung" 1 "HD_Zufahrt_angefordert" ;
VAL_ 497 KY_LKL_1_Autorisierung 0 "Kein_Zugang_LKL_1_erkannt" 1 "Zugang_LKL_1_erkannt" ;
VAL_ 497 KY_LKL_2_Autorisierung 0 "Kein_Zugang_LKL_2_erkannt" 1 "Zugang_LKL_2_erkannt" ;
VAL_ 960 RSt_Fahrerhinweise 0 "Init" 1 "Fahreruebernahme_Hinweis_ZAT_Automat_ohne_Gong" 2 "Fahreruebernahme_Hinweis_ZAT_Automat_mit_Gong" 3 "Fahreruebernahme_Hinweis_ZAT_Handschalter_ohne_Gong" 4 "Fahreruebernahme_Hinweis_ZAT_Handschalter_mit_Gong" 5 "Fahreruebernahme_Hinweis_ZAS_Automat_ohne_Gong" 6 "Fahreruebernahme_Hinweis_ZAS_Automat_mit_Gong" 7 "Fahreruebernahme_Hinweis_ZAS_Handschalter_ohne_Gong" 8 "Fahreruebernahme_Hinweis_ZAS_Handschalter_mit_Gong" 9 "RemoteStart_aktiv_ohne_Gong" 10 "RemoteStart_aktiv_mit_Gong" 11 "void" 12 "void" 13 "void" 14 "void" 15 "void" ;
VAL_ 960 ZAS_Kl_S 0 "aus" 1 "S_Kontakt_ein" ;
VAL_ 960 ZAS_Kl_15 0 "aus" 1 "ein" ;
VAL_ 960 ZAS_Kl_X 0 "aus" 1 "ein" ;
VAL_ 960 ZAS_Kl_50_Startanforderung 0 "aus" 1 "KL50_ein_Startwunsch_Fahrer" ;
VAL_ 960 BCM_Remotestart_Betrieb 0 "kein_RS_Betrieb" 1 "RS_Betrieb" ;
VAL_ 960 ZAS_Kl_Infotainment 0 "inaktiv" 1 "aktiv" ;
VAL_ 960 BCM_Remotestart_KL15_Anf 0 "inaktiv" 1 "aktiv" ;
VAL_ 960 BCM_Remotestart_MO_Start 0 "nicht_angefordert" 1 "angefordert" ;
VAL_ 960 KST_Warn_P1_ZST_def 0 "nicht_defekt" 1 "defekt" ;
VAL_ 960 KST_Warn_P2_ZST_def 0 "nicht_defekt" 1 "defekt" ;
VAL_ 960 KST_Fahrerhinweis_1 0 "inaktiv" 1 "aktiv" ;
VAL_ 960 KST_Fahrerhinweis_2 0 "inaktiv" 1 "aktiv" ;
VAL_ 960 BCM_Ausparken_Betrieb 0 "kein_Betrieb" 1 "Ausparkvorgang_aktiv" ;
VAL_ 960 KST_Fahrerhinweis_4 0 "inaktiv" 1 "aktiv" ;
VAL_ 960 KST_Fahrerhinweis_5 0 "inaktiv" 1 "aktiv" ;
VAL_ 960 KST_Fahrerhinweis_6 0 "inaktiv" 1 "aktiv" ;
VAL_ 1646 KL_STL_aktiv 0 "Standlueftung_nicht_aktiv" 1 "Standlueftung_aktiv" ;
VAL_ 1646 KL_STH_aktiv 0 "Standheizung_nicht_aktiv" 1 "Standheizung_aktiv" ;
VAL_ 1646 KL_Solarluefter_aktiv 0 "Solarluefter_nicht_aktiv" 1 "Solarluefter_aktiv__auto" ;
VAL_ 1646 KL_Umluft_Taste 0 "Taste_nicht_gedrueckt" 1 "Taste_gedrueckt" ;
VAL_ 1646 KL_Geblaese_Fond_Status 0 "Geblaese_aus" 1 "Geblaesestufe_10" 2 "Geblaesestufe_20" 3 "Geblaesestufe_30" 4 "Geblaesestufe_40" 5 "Geblaesestufe_50" 6 "Geblaesestufe_60" 7 "Geblaesestufe_70" 8 "Geblaesestufe_80" 9 "Geblaesestufe_90" 10 "Geblaesestufe_100" 14 "Init" 15 "Fehler" ;
VAL_ 1646 KL_STH_Ansteuerung 0 "Aus" 1 "Ein" 2 "Ein_mit_Motorvorwaermung" 3 "Heizleistung_reduziert" ;
VAL_ 1646 KL_Magnetventil 0 "Aus" 1 "Ein" ;
VAL_ 1646 KL_WaPu 0 "Wasserpumpe_aus" 1 "Wasserpumpe_aktiv" ;
VAL_ 1646 KL_Geblaese_Status 0 "Geblaese_aus" 1 "Geblaesestufe_10" 2 "Geblaesestufe_20" 3 "Geblaesestufe_30" 4 "Geblaesestufe_40" 5 "Geblaesestufe_50" 6 "Geblaesestufe_60" 7 "Geblaesestufe_70" 8 "Geblaesestufe_80" 9 "Geblaesestufe_90" 10 "Geblaesestufe_100" 14 "Init" 15 "Fehler" ;
VAL_ 1646 KL_Restwaerme_aktiv 0 "inaktiv" 1 "aktiv" ;
VAL_ 1646 KL_Kompressorkupplung 0 "oeffnen" 1 "schliessen" ;
VAL_ 1646 KL_BCmE_Livetip_Freigabe 0 "Anzeige_Livetip_nicht_zulaessig" 1 "Anzeige_Livetip_zulaessig" ;
VAL_ 1646 KL_HYB_ASV_hinten_schliessen_Anf 0 "keine_Anforderung" 1 "Ventil_schliessen" ;
VAL_ 1646 KL_HYB_ASV_vorne_schliessen_Anf 0 "keine_Anforderung" 1 "Ventil_schliessen" ;
VAL_ 1646 KL_ErwVK_Zusatzrelais 0 "nicht_angefordert" 1 "angefordert" ;
VAL_ 1646 KL_Status_Beduftung 0 "inaktiv" 1 "aktiv" ;
VAL_ 1646 KL_Status_Ionisator_Front 0 "inaktiv" 1 "aktiv" ;
VAL_ 1646 KL_STH_Timer_Status 0 "TimerInaktiv" 1 "TimerAktiv" ;
VAL_ 1646 KL_ErwVK_Anf 0 "nicht_angefordert" 1 "angefordert" ;
VAL_ 1646 KL_Innen_Temp 253 "nicht_verbaut" 254 "nicht_verfuegbar" 255 "Fehler" ;
VAL_ 1646 KL_I_Geblaese_Fond 255 "Fehler" ;
VAL_ 1646 KL_Anf_AussenspiegelHzg 0 "nicht_angefordert" 1 "angefordert" ;
VAL_ 1646 KL_Heizkreisventilstellung 0 "Init" 1 "Ventilstellung_gem_Anforderung" 2 "Ventilstellung_abweichend_Anf" 3 "Fehler" ;
VAL_ 1646 KL_FSH_Automatikbetrieb 0 "aus" 1 "angefordert_durch_Regelung" ;
VAL_ 1646 KL_SIH_LEH_Verteilung_VL 0 "gleichmaessige_Verteilung" 1 "Sitz_Prio_Hoch" 2 "Sitz_Prio_Mittel" 3 "Sitz_Prio_Niedrig" 4 "Lehne_Prio_Niedrig" 5 "Lehne_Prio_Mittel" 6 "Lehne_Prio_Hoch" ;
VAL_ 1646 KL_SIH_LEL_Verteilung_VL 0 "gleichmaessige_Verteilung" 1 "Sitz_Prio_Hoch" 2 "Sitz_Prio_Mittel" 3 "Sitz_Prio_Niedrig" 4 "Lehne_Prio_Niedrig" 5 "Lehne_Prio_Mittel" 6 "Lehne_Prio_Hoch" ;
VAL_ 1646 KL_SIH_LEH_Verteilung_VR 0 "gleichmaessige_Verteilung" 1 "Sitz_Prio_Hoch" 2 "Sitz_Prio_Mittel" 3 "Sitz_Prio_Niedrig" 4 "Lehne_Prio_Niedrig" 5 "Lehne_Prio_Mittel" 6 "Lehne_Prio_Hoch" ;
VAL_ 1646 KL_SIH_LEL_Verteilung_VR 0 "gleichmaessige_Verteilung" 1 "Sitz_Prio_Hoch" 2 "Sitz_Prio_Mittel" 3 "Sitz_Prio_Niedrig" 4 "Lehne_Prio_Niedrig" 5 "Lehne_Prio_Mittel" 6 "Lehne_Prio_Hoch" ;
VAL_ 1649 KL_ZZ_Status_Timer 0 "Timer_n_aktiv_bzw_loeschen" 1 "Timer_aktiv_bzw_aktivieren" ;
VAL_ 1649 KL_ZZ_Monat 0 "Init" ;
VAL_ 1649 KL_ZZ_Betriebsmodus 0 "Do_not_Care" 1 "ECO" 2 "Standard" 3 "Standard_plus" 4 "Comfort" ;
VAL_ 1649 KL_ZZ_Tag 0 "Init" ;
VAL_ 1649 KL_Betriebsmodus_FH 0 "undefined__init" 1 "Klemme15" 2 "Standheizung" 3 "Restwaerme" 4 "Nachlauf" 5 "Standlueften" 6 "Betriebsart_X" 7 "Betriebsart_Y" ;
VAL_ 1649 KL_Stopp_Wiederstart_Anz_01 0 "keine_Anzeige" 1 "Geblaese" ;
VAL_ 1649 KL_Stopp_Wiederstart_Anz_02 0 "keine_Anzeige" 1 "Differenz_Soll_Ausblas_zu_Ist_Ausblastemperatur" ;
VAL_ 1649 KL_Stopp_Wiederstart_Anz_03 0 "keine_Anzeige" 1 "Beschlagsgefahr" ;
VAL_ 1649 KL_Stopp_Wiederstart_Anz_04 0 "keine_Anzeige" 1 "Differenz_Soll_Innentemperatur_zu_Ist_Innenraumtemperatur" ;
VAL_ 1649 KL_Stopp_Wiederstart_Anz_05 0 "keine_Anzeige" 1 "Komfortfeuchte" ;
VAL_ 1649 KL_Stopp_Wiederstart_Anz_06 0 "keine_Anzeige" 1 "Aussentemperatur" ;
VAL_ 1649 KL_Stopp_Wiederstart_Anz_07 0 "keine_Anzeige" 1 "Defrost" ;
VAL_ 1649 KL_Stopp_Wiederstart_Anz_08 0 "keine_Anzeige" 1 "High_Low" ;
VAL_ 1649 KL_Stopp_Wiederstart_Anz_09 0 "keine_Anzeige" 1 "Frontscheibenheizung" ;
VAL_ 1649 KL_Stopp_Wiederstart_Anz_Std1 0 "keine_Anzeige" 1 "maxA/C" ;
VAL_ 1649 KL_Stopp_Wiederstart_Anz_Std2 0 "keine_Anzeige" 1 "Sitzlueftung" ;
VAL_ 949 KL_Drehz_Anh 0 "keine_Anhebung" 1 "Drehzahlanhebung_vom_Motor_angefordert" ;
VAL_ 949 KL_Vorwarn_Komp_ein 0 "Init" 1 "Vorwarnung_Kompressor_ein" ;
VAL_ 949 KL_AC_Schalter 0 "aus" 1 "ein" ;
VAL_ 949 KL_Komp_Moment_alt 1 "veraltet_bzw_Ermittlung_des_Moments_nicht_moeglich__zB_keine_Drehzahl_kein_Kaeltemitteldruck" ;
VAL_ 949 KL_Vorwarn_Zuheizer_ein 0 "keine_Vorwarnung" 1 "Vorwarnung_Zuheizer_ein" ;
VAL_ 949 KL_Zustand 0 "Aus" 1 "Ein" ;
VAL_ 949 KL_Kompressorkupplung_linear 253 "volle_Ansteuerung" 254 "Init__nicht_bedient" ;
VAL_ 949 KL_Charisma_FahrPr 0 "keine_Funktion" 1 "Programm_1" 2 "Programm_2" 3 "Programm_3" 4 "Programm_4" 5 "Programm_5" 6 "Programm_6" 7 "Programm_7" 8 "Programm_8" 9 "Programm_9" 10 "Programm_10" 11 "Programm_11" 12 "Programm_12" 13 "Programm_13" 14 "Programm_14" 15 "Programm_15" ;
VAL_ 949 KL_Charisma_Status 0 "Init" 1 "verfuegbar" 2 "nicht_verfuegbar" 3 "asynchron_durch_Fahrerwunsch" ;
VAL_ 949 KL_nachtr_Stopp_Anf 0 "nicht_angefordert" 1 "angefordert" ;
VAL_ 949 KL_T_Charge 0 "Taster_nicht_betaetigt" 1 "Taster_betaetigt" ;
VAL_ 949 KL_Last_Kompr 255 "Fehler" ;
VAL_ 949 KL_Spannungs_Anf 0 "keine_Anforderung" 1 "Anforderung_Stufe_1" 2 "Anforderung_Stufe_2" 3 "Anforderung_Stufe_3" ;
VAL_ 949 KL_Thermomanagement 0 "keine_Freigabe_TMM__max_Heizbedarf" 1 "kleine_Freigabe_TMM" 2 "mittlere_Freigabe_TMM" 3 "volle_Freigabe_TMM__kein_Heizbedarf" ;
VAL_ 949 KL_StartStopp_Info 0 "Motorlauf_nicht_notwendig_(Stoppfreigabe)" 1 "Motoranlauf_nicht_zwingend_notwendig_(Stoppverbot,keine_Startanforderung)" 2 "Motoranlauf_zwingend_notwendig_(Startanforderung)" 3 "Systemfehler" ;
VAL_ 949 KL_Freilauf_Info 0 "Freilauf_freigegeben" 1 "Uebergang_in_Freilauf_unzulaessig" 2 "Freilauf_nicht_freigegeben_Abbruch" 3 "Freilauf_Anforderung" ;
VAL_ 949 KL_Anf_KL 255 "Fehler" ;
VAL_ 949 KL_el_Zuheizer_Stufe 0 "Aus" 1 "Stufe_1" 2 "Stufe_2" 3 "Stufe_3" ;
VAL_ 949 KL_Ausstattung_Klima 0 "Heizung_elektrisch" 1 "Klimamanuell_elektrisch" 2 "Climatic__1_Zone" 3 "Climatronic__1_Zone" 4 "Climatronic__2_Zonen" 5 "Climatronic__3_Zonen" 6 "Climatronic__4_Zonen" 7 "reserviert" ;
VAL_ 949 KL_Variante_Standheizung 0 "Wasserstandheizung_60_min_Laufzeit" 1 "Luftstandheizung_120_min_Laufzeit" 2 "Wasserstandheizung_120_min_Laufzeit" 3 "Wasser_und_Luftstandheizung_120_min_Laufzeit" ;
VAL_ 1640 KL_LRH_Taster 0 "nicht_betaetigt" 1 "betaetigt" ;
VAL_ 1640 KL_LRH_Stufe 0 "Stufe_niedrig" 1 "Stufe_mittel" 2 "Stufe_hoch" 3 "AUS" ;
VAL_ 1640 HSH_Taster 0 "nicht_betaetigt" 1 "short_push" 2 "long_push" 3 "tbd" ;
VAL_ 1640 FSH_Taster 0 "nicht_betaetigt" 1 "betaetigt" ;
VAL_ 1640 KL_Zuheizer_Freigabe 0 "keine_Freigabe_Zuheizer" 1 "Zuheizerfreigabe" ;
VAL_ 1640 KL_Beschlagsgefahr 0 "keine_Beschlagsgefahr" 1 "Beschlagsgefahr" ;
VAL_ 1640 KRH_Soll_li 0 "aus" 1 "Stufe_1" 2 "Stufe_2" 3 "Stufe_3" ;
VAL_ 1640 KRH_Soll_re 0 "aus" 1 "Stufe_1" 2 "Stufe_2" 3 "Stufe_3" ;
VAL_ 1640 KL_Geblspng_Soll 0 "0V_Motorspannung" 252 "0V_sofort_Abschalten" 253 "0V_senken_mit_Rampe" 254 "reserviert" 255 "Fehler" ;
VAL_ 1640 KL_Geblspng_Fond_Soll 0 "0V_Motorspannung" 252 "0V_sofort_Abschalten" 253 "0V_senken_mit_Rampe" 254 "reserviert" 255 "Fehler" ;
VAL_ 1640 KL_I_Geblaese 255 "Fehler" ;
VAL_ 1640 KL_Kompressorstrom_soll 1022 "Init" 1023 "Fehler" ;
VAL_ 1640 KL_Umluftklappe_Status 0 "Frischluft" 1 "Teilumluft_10" 2 "Teilumluft_20" 3 "Teilumluft_30" 4 "Teilumluft_40" 5 "Teilumluft_50" 6 "Teilumluft_60" 7 "Teilumluft_70" 8 "Teilumluft_80" 9 "Teilumluft_90" 10 "Umluft" 14 "Init" 15 "Fehler" ;
VAL_ 1640 KL_PTC_Verbauinfo 0 "kein_PTC" 1 "600W_geschaltet" 2 "1000W_geschaltet" 3 "1400W_LIN" ;
VAL_ 1441 KL_Temp_Soll_hl 30 "Klima_OFF" 31 "Init" ;
VAL_ 1441 KL_Temp_Soll_hr 30 "Klima_OFF" 31 "Init" ;
VAL_ 1441 KL_Temp_Soll_vl 30 "Klima_OFF" 31 "Init" ;
VAL_ 1441 KL_Temp_Soll_vr 30 "Klima_OFF" 31 "Init" ;
VAL_ 1441 KL_SIH_Stufe_hl 7 "nicht_verbaut" ;
VAL_ 1441 KL_SIH_Stufe_hr 7 "nicht_verbaut" ;
VAL_ 1441 KL_SIL_Stufe_hl 7 "nicht_verbaut" ;
VAL_ 1441 KL_SIL_Stufe_hr 7 "nicht_verbaut" ;
VAL_ 1441 KL_SIL_LEL_Verteilung_HR 0 "gleichmaessige_Verteilung" 1 "Sitz_Prio_Hoch" 2 "Sitz_Prio_Mittel" 3 "Sitz_Prio_Niedrig" 4 "Lehne_Prio_Niedrig" 5 "Lehne_Prio_Mittel" 6 "Lehne_Prio_Hoch" ;
VAL_ 1441 KL_SIL_LEL_Verteilung_HL 0 "gleichmaessige_Verteilung" 1 "Sitz_Prio_Hoch" 2 "Sitz_Prio_Mittel" 3 "Sitz_Prio_Niedrig" 4 "Lehne_Prio_Niedrig" 5 "Lehne_Prio_Mittel" 6 "Lehne_Prio_Hoch" ;
VAL_ 1441 KL_SIH_LEH_Verteilung_HR 0 "gleichmaessige_Verteilung" 1 "Sitz_Prio_Hoch" 2 "Sitz_Prio_Mittel" 3 "Sitz_Prio_Niedrig" 4 "Lehne_Prio_Niedrig" 5 "Lehne_Prio_Mittel" 6 "Lehne_Prio_Hoch" ;
VAL_ 1441 KL_PTC_linear_Anf 0 "Init" 63 "Fehler" ;
VAL_ 1441 KL_SIH_LEH_Verteilung_HL 0 "gleichmaessige_Verteilung" 1 "Sitz_Prio_Hoch" 2 "Sitz_Prio_Mittel" 3 "Sitz_Prio_Niedrig" 4 "Lehne_Prio_Niedrig" 5 "Lehne_Prio_Mittel" 6 "Lehne_Prio_Hoch" ;
VAL_ 1441 KL_Frischluftklappe_Status 126 "Init" 127 "Fehler" ;
VAL_ 2589283469 KL_Verdampferleistung 254 "Init" 255 "Fehler" ;
VAL_ 2589283469 KL_VK_Anf 0 "keine_Startanf_von_Climatronic" 1 "Startanf_via_FFB" 2 "Startanf_via_Sofortheiztaste" 3 "VK_Strategie_STH" 4 "Startanf_via_ZV_FFB" 5 "VK_Abbruch" 6 "Init" 7 "Fehler" ;
VAL_ 2589283469 KL_Verdampferleistung_Faktor 0 "Faktor_1" 1 "Faktor_2" ;
VAL_ 2589283469 KL_Geblaese_Fond_erw 0 "Geblaese_aus" 1 "Geblaesestufe_10" 2 "Geblaesestufe_20" 3 "Geblaesestufe_30" 4 "Geblaesestufe_40" 5 "Geblaesestufe_50" 6 "Geblaesestufe_60" 7 "Geblaesestufe_70" 8 "Geblaesestufe_80" 9 "Geblaesestufe_90" 10 "Geblaesestufe_100" 14 "Init" 15 "Fehler" ;
VAL_ 2589283469 KL_Geblaese_erw 0 "Geblaese_aus" 1 "Geblaesestufe_10" 2 "Geblaesestufe_20" 3 "Geblaesestufe_30" 4 "Geblaesestufe_40" 5 "Geblaesestufe_50" 6 "Geblaesestufe_60" 7 "Geblaesestufe_70" 8 "Geblaesestufe_80" 9 "Geblaesestufe_90" 10 "Geblaesestufe_100" 14 "Init" 15 "Fehler" ;
VAL_ 2589283469 KL_Vorkond_Strategie 0 "Aus" 1 "Spülen" 2 "Kanalkühlung" 3 "Kühlwasserzirkulation" 4 "Aktive Kühlung" 5 "Heizen" 6 "Reheat" 7 "Heizen_elektrisch" 8 "Heizen_verbrennungstechnisch" 13 "Strategie_nicht_berechnet" 14 "Konditionierung_nicht_moeglich" 15 "Init" ;
VAL_ 2589283469 KL_Tempklappe_re 254 "Init" 255 "Fehler" ;
VAL_ 2589283469 KL_Tempklappe_li 254 "Init" 255 "Fehler" ;
VAL_ 2589283469 KL_Tempklappe_Fond 254 "Init" 255 "Fehler" ;
VAL_ 2589283469 KL_Kuehllstg_Delta_Eingriff 254 "Init" 255 "Fehler" ;
VAL_ 2589283469 KL_Heizlstg_Delta_Eingriff 254 "Init" 255 "Fehler" ;
VAL_ 2589283621 KL_NV_Energie_Anf 254 "Init" 255 "Fehler" ;
VAL_ 2589283621 KL_Umluft_Connect_status 0 "Keine_Umluft" 1 "Umluft_Kundenwunsch" 2 "Umluft_AQS" 3 "Umluft_Backend_Empfehlung" 4 "Umluft_Navi_Daten" ;
VAL_ 2589283621 KL_ECO_PRO_Aktiv 0 "inaktiv" 1 "aktiv" ;
VAL_ 2589283621 KL_QBit_Sonnenintensitaet 0 "gueltiger_Wert" 1 "Ersatz_Init_oder_Fehlerwert" ;
VAL_ 2589283621 KL_ZR_Anforderung 0 "init" 1 "inaktiv" 2 "aktiv" 3 "reserviert" ;
VAL_ 2589283621 KL_ACmax_Aktiv 0 "inaktiv" 1 "aktiv" ;
VAL_ 2589283621 KL_Defrost_Aktiv 0 "inaktiv" 1 "aktiv" ;
VAL_ 2589283621 KL_ECO_Aktiv 0 "inaktiv" 1 "aktiv" ;
VAL_ 2589283621 KL_Status_Klimastil 0 "Modus_1" 1 "Modus_2" 2 "Modus_3" 3 "Modus_4" ;
VAL_ 2589283621 KL_Kundeneingriff_Geblaese 0 "Kein_Kundeneingriff_Geblaese" 1 "Kundeneingriff_Geblaese_aktiv" ;
VAL_ 2589283621 KL_Thermischer_Bedarf 0 "Aus" 1 "Heizen" 2 "Nachlauf_Heizen" 3 "Lueften" 4 "Kuehlen" 6 "Init" 7 "Fehler" ;
VAL_ 2589283621 KL_Eps_Innen 254 "Init" 255 "Fehler" ;
VAL_ 2589283621 KL_Sonnenintensitaet 255 "Fehler" ;
VAL_ 2463978701 KL_Temp_Soll_vr_Prognose 30 "Klima_OFF" 31 "Init" ;
VAL_ 2463978701 KL_Leistungsreduktions_Hinweis 0 "kein_Hinweis_Anzeigen" 1 "Hinweis_Anzeigen" ;
VAL_ 2463978701 KL_AC_Schalter_Prognose 0 "aus" 1 "ein" 2 "automatisiertes_an_ab_schalten" ;
VAL_ 2463978701 KL_Temp_Soll_vl_Prognose 30 "Klima_Off" 31 "Init" ;
VAL_ 2463978701 KL_Sollklimamodus_FPR_1 0 "Klima_OFF" 1 "Normal" 2 "ECO_aktiv" 3 "ECO_aktiv_AC_toggeln" 4 "FANonly" ;
VAL_ 2463978701 KL_Temp_Soll_hr_Prognose 30 "Klima_OFF" 31 "Init" ;
VAL_ 2463978701 KL_Sollklimamodus_FPR_2 0 "Klima_OFF" 1 "Normal" 2 "ECO_aktiv" 3 "ECO_aktiv_AC_toggeln" 4 "FANonly" ;
VAL_ 2463978701 KL_Temp_Soll_hl_Prognose 30 "Klima_OFF" 31 "Init" ;
VAL_ 2463978701 KL_Sollklimamodus_FPR_3 0 "Klima_OFF" 1 "Normal" 2 "ECO_aktiv" 3 "ECO_aktiv_AC_toggeln" 4 "FANonly" ;
VAL_ 1712 FS_Taupunkt 0 "nicht verfuegbar" 1023 "Fehler" ;
VAL_ 1712 FS_ResponseError 0 "normal" 1 "Fehler" ;
VAL_ 1712 FS_Temp_Scheibe 0 "nicht verfuegbar" 1023 "Fehler" ;
VAL_ 1712 FS_Temp_Sensor 0 "nicht verfuegbar" 255 "Fehler" ;
VAL_ 1712 FS_Luftfeuchte_rel 0 "nicht verfuegbar" 255 "Fehler" ;
VAL_ 1505 BCM1_Aussen_Temp_ungef 253 "nicht_verbaut" 254 "Initwert" 255 "Fehler" ;
VAL_ 1505 BCM_Heizungsabsperrventil_Status 0 "HAV_offen" 1 "HAV_geschlossen" 2 "Init_oder_nicht_verbaut" 3 "Fehler" ;
VAL_ 1505 BCM_Heizungspumpe_Status 0 "Pumpe_aus" 1 "Pumpe_aktiv_und_Stauts_iO" 2 "Init_oder_nicht_verbaut" 3 "Fehler" ;
VAL_ 1505 BCM_Kompressorkupplung_Status 0 "Kupplung_offen" 1 "Kupplung_geschlossen" 2 "Init_oder_nicht_verbaut" 3 "Fehler" ;
VAL_ 1505 BCM1_PTC_stufig_Status 0 "Aus" 1 "Stufe_1_aktiv" 2 "Stufe_2_aktiv" 3 "Stufe_3_aktiv" 6 "Init_oder_nicht_verbaut" 7 "Fehler" ;
VAL_ 1505 BCM1_FStatus_Aussentemp_ungef 0 "iO" 1 "niO" ;
VAL_ 1505 BCM1_Kompressorstrom_ist 254 "Init, bzw. nicht verfuegbar" 255 "Fehler" ;
VAL_ 1505 BCM1_OBD_FStatus_ATemp 0 "kein Fehler / Init / nicht verbaut" 1 "KS- (Kurzschluss nach minus)" 2 "KS+ (Kurzschluss nach plus)" 3 "OC (Leitungsunterbrechung)" 4 "OOR+ (Signal zu gross)" 5 "OOR- (Signal zu klein)" 6 "RC+ (Signal unplausibel zu gross)" 7 "RC- (Signal unplausibel zu klein)" 8 "KS+/OC (Kurzschluss nach plus/Unterbrechung)" 9 "KS-/OC  (Kurzschluss nach minus/Unterbrechung)" 10 "KS-/KS+  (Kurzschluss nach minus/plus)" 11 "KS-/KS+/OC (Kurzschluss nach minus/plus/Unterbrechung)" 12 "frei" 13 "frei" 14 "frei" 15 "frei" ;
VAL_ 1717 FSA_Taupunkt 1021 "nicht_verbaut" 1022 "Init" 1023 "Fehler" ;
VAL_ 1717 FSA_Err_Defekt_Tsens_TF 0 "inaktiv" 1 "aktiv" ;
VAL_ 1717 FSA_Luftfeuchte_TNCTOC 0 "Test_Completed_TOC" 1 "Test_Not_Completed_TOC" ;
VAL_ 1717 FSA_Luftfeuchte_TF 0 "inaktiv" 1 "aktiv" ;
VAL_ 1717 FSA_Err_Unterspannung_TF 0 "inaktiv" 1 "aktiv" ;
VAL_ 1717 FSA_Err_RAMROM_Check_TF 0 "inaktiv" 1 "aktiv" ;
VAL_ 1717 FSA_ResponseError 0 "normal" 1 "Fehler" ;
VAL_ 1717 FSA_Temp_Luft 1021 "nicht_verbaut" 1022 "Init" 1023 "Fehler" ;
VAL_ 1717 FSA_Err_RAMROM_Check_TNCTOC 0 "Test_Completed_TOC" 1 "Test_Not_Completed_TOC" ;
VAL_ 1717 FSA_Lokal_Bus_elektr_Fehler 0 "kein_Fehler" 1 "Fehler" ;
VAL_ 1717 FSA_Timeout 0 "kein_Fehler" 1 "Fehler" ;
VAL_ 1717 FSA_Lokal_Bus_Unterbrechung 0 "kein_Fehler" 1 "Fehler" ;
VAL_ 1717 FSA_Err_Ueberspannung_TF 0 "inaktiv" 1 "aktiv" ;
VAL_ 1717 FSA_Luftfeuchte_rel 253 "nicht_verbaut" 254 "Init" 255 "Fehler" ;
VAL_ 1717 FSA_Temp_Sensor 2045 "nicht_verbaut" 2046 "Init" 2047 "Fehler" ;
VAL_ 1717 FSA_Sensorheizung_Status 0 "inaktiv" 1 "aktiv" ;
VAL_ 1717 FSA_Err_Defekt_HumSense_TF 0 "inaktiv" 1 "aktiv" ;
VAL_ 1717 FSA_Err_Defekt_HumSens_TNCTOC 0 "Test_Completed_TOC" 1 "Test_Not_Completed_TOC" ;
VAL_ 1717 FSA_ErrMemState 0 "Init_Default" 1 "ErrMem_Active_State" 2 "ErrMem_InitProgress" 3 "ErrMem_Init_done" ;
VAL_ 1513 DS_Kaeltemittel_P 2046 "Init" 2047 "Fehler" ;
VAL_ 1513 DS_Status 0 "i.O." 1 "t.b.d." 2 "Init bzw. nicht verfügbar" 3 "Fehler" ;
VAL_ 1513 ION_Status 0 "Hochspannung_ausgeschaltet" 1 "Hochspannung_eingeschaltet" 2 "Init" ;
VAL_ 1513 ION_Status_LED 0 "Aus" 1 "Ein" ;
VAL_ 1513 AAU_Geblaese 126 "Init" 127 "Fehler" ;
VAL_ 1513 ION_Status_Taster 0 "nicht_betaetigt" 1 "betaetigt" ;
VAL_ 1295 KL_Kuehlenergie_instat_pred 254 "Init" 255 "Fehler" ;
VAL_ 1295 KL_Heizenergie_instat_pred 254 "Init" 255 "Fehler" ;
VAL_ 1295 KL_PTC_ein 0 "Aus" 1 "Ein" ;
VAL_ 1295 KL_Leistungspriorisierung 0 "keine_Priorisierung" 1 "PullDown" 2 "Beschlagsgefahr" 3 "Defrost_aktiv" ;
VAL_ 1295 KL_Verdampfertemperatur 1022 "Init" 1023 "Fehler" ;
VAL_ 1295 KL_Heizbedarf 0 "Kein_Heizbedarf" 1022 "Init" 1023 "Fehler" ;
VAL_ 1295 KL_Kuehlbedarf 253 "Kein_Kuehlbedarf" 254 "Init" 255 "Fehler" ;
VAL_ 1295 KL_Kuehlleistg_stat_erw 254 "Init" 255 "Fehler" ;
VAL_ 1295 KL_Heizleistg_stat_erw 254 "Init" 255 "Fehler" ;
VAL_ 2589283474 KL_Temp_vor_Verdampfer 126 "Init" 127 "Fehler" ;
VAL_ 2589283474 KL_Eps_Innen 254 "Init" 255 "Fehler" ;
VAL_ 2589283474 KL_Tempklappe_Fond_li 254 "Init" 255 "Fehler" ;
VAL_ 2589283474 KL_Tempklappe_Fond_re 254 "Init" 255 "Fehler" ;
VAL_ 2463978659 KMP_Status_Spgfreiheit 0 "Init" 1 "HV_Komponente_spannungsfrei" 2 "HV_Komp_nicht_spannungsfrei" 3 "Fehler_nicht_spannungsfrei" ;
VAL_ 2463978659 KMP_Warnung_Trockenlauf 0 "kein_Fehler" 1 "Warnung_Trockenlauf_KMP" ;
VAL_ 2463978659 KMP_Warnung_Uebertemperatur 0 "kein_Fehler" 1 "Warnung_Uebertemperatur" ;
VAL_ 2463978659 KMP_Fehler_Blockiert 0 "kein_Fehler" 1 "Fehler" ;
VAL_ 2463978659 KMP_Fehler_elektrischer_Fehler 0 "kein_Fehler" 1 "Fehler" ;
VAL_ 2463978659 KMP_Fehler_Ueberspannung_HV 0 "kein_Fehler" 1 "Fehler" ;
VAL_ 2463978659 KMP_Fehler_Ueberspannung_12V 0 "kein_Fehler" 1 "Fehler" ;
VAL_ 2463978659 KMP_Fehler_Uebertemperatur 0 "kein_Fehler" 1 "Fehler" ;
VAL_ 2463978659 KMP_Fehler_Unterspannung_HV 0 "kein_Fehler" 1 "Fehler" ;
VAL_ 2463978659 KMP_Fehler_Unterspannung_12V 0 "kein_Fehler" 1 "Fehler" ;
VAL_ 2463978659 KMP_Error_NW_Timeout 0 "TestNotCompleted_TOC" 1 "TestCompleted_TOC_PASS" 3 "TestCompleted_TOC_FAIL" ;
VAL_ 2549088399 AWC_KompSchutz 0 "inaktiv" 1 "aktiv" ;
VAL_ 2549088399 AWC_Abschaltstufe 0 "keine_Einschraenkung" 1 "Funktionseinschraenkung" ;
VAL_ 2549088399 AWC_Transport_Mode 0 "keine_Einschraenkung" 1 "Funktionseinschraenkung" ;
VAL_ 2549088399 AWC_Nachlauftyp 0 "Komm_bei_KL15_EIN" 1 "Komm_nach_KL15_AUS" 2 "Komm_bei_KL15_AUS" ;
VAL_ 2549088399 AWC_SNI 143 "AWC" ;
VAL_ 2549088399 KN_AWC_ECUKnockOutTimer 63 "ECUKnockOut_deaktiviert" ;
VAL_ 2549088399 KN_AWC_BusKnockOut 0 "Funktion_nicht_ausgeloest" 1 "Veto_aktiv" 2 "Funktion_ausgeloest" 3 "Funktion_deaktiviert" ;
VAL_ 2549088399 KN_AWC_BusKnockOutTimer 255 "BusKnockOut_deaktiviert" ;
VAL_ 2549088399 NM_AWC_Wakeup 0 "Peripherie_Wakeup__Ursache_nicht_bekannt" 1 "Bus_Wakeup" 2 "KL15_HW" 5 "Infrastrukturladeplatte_erkannt" ;
VAL_ 2549088399 KN_AWC_ECUKnockOut 0 "Funktion_nicht_ausgeloest" 1 "Veto_war_aktiv" 2 "Funktion_ausgeloest" 3 "Funktion_deaktiviert" ;
VAL_ 2549088399 AWC_Lokalaktiv 0 "war_nicht_lokal_aktiv" 1 "war_lokal_aktiv" ;
VAL_ 2549088399 AWC_Subsystemaktiv 0 "Subsystem_war_nicht_lokalaktiv" 1 "war_lokalaktiv" ;
VAL_ 2549088399 AWC_KD_Fehler 0 "kein_KD_Fehler" 1 "KD_Fehler" ;
VAL_ 2549088430 BattRegelung_KompSchutz 0 "inaktiv" 1 "aktiv" ;
VAL_ 2549088430 BattRegelung_Abschaltstufe 0 "keine_Einschraenkung" 1 "Funktionseinschraenkung" ;
VAL_ 2549088430 BattRegelung_Transport_Mode 0 "keine_Einschraenkung" 1 "Funktionseinschraenkung" ;
VAL_ 2549088430 BattRegelung_Nachlauftyp 0 "Komm_bei_KL15_EIN" 1 "Komm_nach_KL15_AUS" 2 "Komm_bei_KL15_AUS" ;
VAL_ 2549088430 BattRegelung_SNI 174 "Battregelung" ;
VAL_ 2549088430 NM_Battregelung_Wakeup 0 "Peripherie_Wakeup_Ursache_nicht_bekannt" 1 "Bus_Wakeup" 2 "KL15_HW" ;
VAL_ 2549088430 BMS_NV_Lokalaktiv 0 "war_nicht_Lokalaktiv" 1 "war_Lokalaktiv" ;
VAL_ 2549088430 BattRegelung_KD_Fehler 0 "kein_KD_Fehler" 1 "KD_Fehler" ;
VAL_ 2549088412 BMS_MV_KompSchutz 0 "inaktiv" 1 "aktiv" ;
VAL_ 2549088412 BMS_MV_Abschaltstufe 0 "keine_Einschraenkung" 1 "Funktionseinschraenkung" ;
VAL_ 2549088412 BMS_MV_Transport_Mode 0 "keine_Einschraenkung" 1 "Funktionseinschraenkung" ;
VAL_ 2549088412 BMS_MV_Nachlauftyp 0 "Komm_bei_KL15_EIN" 1 "Komm_nach_KL15_AUS" 2 "Komm_bei_KL15_AUS" ;
VAL_ 2549088412 BMS_MV_SNI 156 "BMS_MV" ;
VAL_ 2549088412 NM_BMS_MV_Wakeup 0 "Peripherie_Wakeup__Ursache_nicht_bekannt" 1 "Bus_Wakeup" 2 "KL15_HW" 3 "KL_30_Reset" ;
VAL_ 2549088412 BMS_MV_Lokalaktiv 0 "war_nicht_Lokalaktiv" 1 "war_Lokalaktiv" ;
VAL_ 2549088412 BMS_MV_Subsystemaktiv 0 "war_nicht_Lokalaktiv" 1 "war_Lokalaktiv" ;
VAL_ 2549088412 BMS_MV_KD_Fehler 0 "kein_KD_Fehler" 1 "KD_Fehler" ;
VAL_ 2549088321 DCDC_KompSchutz 0 "inaktiv" 1 "aktiv" ;
VAL_ 2549088321 DCDC_Abschaltstufe 0 "keine_Einschraenkung" 1 "Funktionseinschraenkung" ;
VAL_ 2549088321 DCDC_Transport_Mode 0 "keine_Einschraenkung" 1 "Funktionseinschraenkung" ;
VAL_ 2549088321 DCDC_Nachlauftyp 0 "Komm_bei_KL15_EIN" 1 "Komm_nach_KL15_AUS" 2 "Komm_bei_KL15_AUS" ;
VAL_ 2549088321 DCDC_SNI 65 "DCDC" ;
VAL_ 2549088321 KN_DCDC_BusKnockOutTimer 255 "BusKnockOut_deaktiviert" ;
VAL_ 2549088321 NM_DCDC_Wakeup 0 "Peripherie_Wakeup__Ursache_nicht_bekannt" 1 "Bus_Wakeup" 2 "KL15_HW" ;
VAL_ 2549088321 NMH_DCDC_Lokalaktiv 0 "war_nicht_lokal_aktiv" 1 "war_lokal_aktiv" ;
VAL_ 2549088321 NMH_DCDC_Subsystemaktiv 0 "Subsystem_war_nicht_lokalaktiv" 1 "war_lokalaktiv" ;
VAL_ 2549088321 DCDC_KD_Fehler 0 "Kein KD_Fehler" 1 "KD_Fehler" ;
VAL_ 2549088439 DCDC_HV_KompSchutz 0 "inaktiv" 1 "aktiv" ;
VAL_ 2549088439 DCDC_HV_Abschaltstufe 0 "keine_Einschraenkung" 1 "Funktionseinschraenkung" ;
VAL_ 2549088439 DCDC_HV_Transport_Mode 0 "keine_Einschraenkung" 1 "Funktionseinschraenkung" ;
VAL_ 2549088439 DCDC_HV_Nachlauftyp 0 "Komm_bei_KL15_EIN" 1 "Komm_nach_KL15_AUS" 2 "Komm_bei_KL15_AUS" ;
VAL_ 2549088439 DCDC_HV_SNI 183 "DCDC_HV" ;
VAL_ 2549088439 DCDC_HV_ECUKnockOutTimer 63 "ECUKnockOut_deaktiviert" ;
VAL_ 2549088439 DCDC_HV_BusKnockOut 0 "Funktion_nicht_ausgeloest" 1 "Veto_aktiv" 2 "Funktion_ausgeloest" 3 "Funktion_deaktiviert" ;
VAL_ 2549088439 DCDC_HV_BusKnockOutTimer 255 "BusKnockOut_deaktiviert" ;
VAL_ 2549088439 NM_DCDC_HV_Wakeup 0 "Peripherie_Wakeup__Ursache_nicht_bekannt" 1 "Bus_Wakeup" 2 "KL15_HW" ;
VAL_ 2549088439 DCDC_HV_ECUKnockOut 0 "Funktion_nicht_ausgeloest" 1 "Veto_war_aktiv" 2 "Funktion_ausgeloest" 3 "Funktion_deaktiviert" ;
VAL_ 2549088439 DCDC_HV_Lokalaktiv 0 "war_nicht_lokal_aktiv" 1 "war_lokal_aktiv" ;
VAL_ 2549088439 DCDC_HV_KD_Fehler 0 "kein_KD_Fehler" 1 "KD_Fehler" ;
VAL_ 2549088455 DCDC_HV_02_KompSchutz 0 "inaktiv" 1 "aktiv" ;
VAL_ 2549088455 DCDC_HV_02_Abschaltstufe 0 "keine_Einschraenkung" 1 "Funktionseinschraenkung" ;
VAL_ 2549088455 DCDC_HV_02_Transport_Mode 0 "keine_Einschraenkung" 1 "Funktionseinschraenkung" ;
VAL_ 2549088455 DCDC_HV_02_Nachlauftyp 0 "Komm_bei_KL15_EIN" 1 "Komm_nach_KL15_AUS" 2 "Komm_bei_KL15_AUS" ;
VAL_ 2549088455 DCDC_HV_02_SNI 199 "DCDC_HV_02" ;
VAL_ 2549088455 KN_DCDC_HV_02_ECUKnockOutTimer 63 "ECUKnockOut_deaktiviert" ;
VAL_ 2549088455 KN_DCDC_HV_02_BusKnockOut 0 "Funktion_nicht_ausgeloest" 1 "Veto_aktiv" 2 "Funktion_ausgeloest" 3 "Funktion_deaktiviert" ;
VAL_ 2549088455 KN_DCDC_HV_02_BusKnockOutTimer 255 "BusKnockOut_deaktiviert" ;
VAL_ 2549088455 NM_DCDC_HV_02_Wakeup 0 "Peripherie_Wakeup__Ursache_nicht_bekannt" 1 "Bus_Wakeup" 2 "KL15_HW" ;
VAL_ 2549088455 KN_DCDC_HV_02_ECUKnockOut 0 "Funktion_nicht_ausgeloest" 1 "Veto_war_aktiv" 2 "Funktion_ausgeloest" 3 "Funktion_deaktiviert" ;
VAL_ 2549088455 NM_DCDC_HV_02_Lokalaktiv 0 "war_nicht_lokal_aktiv" 1 "war_lokal_aktiv" ;
VAL_ 2549088455 DCDC_HV_02_KD_Fehler 0 "kein_KD_Fehler" 1 "KD_Fehler" ;
